// *************************************************************************** *
// *                                                                           *
// *                      Mentor Graphics Corporation                          *
// *                          All rights reserved                              *
// *                                                                           *
// *************************************************************************** *
// *                                                                           *
// * Description:         CANDB File                                           *
// * Generated at:        2021-09-06 14:00                                     *
// * System:              LPCsystem_MAIN                                       *
// * Network:             LPC1CAN                                              *
// *                                                                           *
// *************************************************************************** *
// *                                                                           *
// *             THIS CONFIGURATION MIGHT CONTAIN SOME ERRORS                  *
// *              IF THE INPUT MODEL WAS NOT PROPERLY FORMED!                  *
// *                    Do Not Use this File directly!                         *
// *                                                                           *
// *************************************************************************** *
VERSION "LPC1CAN"

NS_ :

BS_ :

BU_ :  LPC LPCdp LPCETC

BO_ 337 LpcdpLpcPASFr01 : 64 LPCdp
 SG_ AbsCtrlActv2 : 469|1@0+ (1,0) [0|1] "" LPC
 SG_ AbsCtrlActv2_UB : 468|1@0+ (1,0) [0|1] "" LPC
 SG_ AccSts2 : 415|3@0+ (1,0) [0|7] "" LPC
 SG_ AccSts2_UB : 412|1@0+ (1,0) [0|1] "" LPC
 SG_ AdPrimWhlAgEstimdGroupSafe_UB : 504|1@0+ (1,0) [0|1] "" LPC
 SG_ AdPrimWhlAgEstimdGroupSafeChks : 0|8@1+ (1.0,0.0) [0.0|255.0] "Unitless" LPC
 SG_ AdPrimWhlAgEstimdGroupSafeCntr : 8|4@1+ (1.0,0.0) [0.0|15.0] "Unitless" LPC
 SG_ AdPrimWhlAgEstimdGroupSafeQf1 : 48|2@1+ (1,0) [0|3] "" LPC
 SG_ AdPrimWhlAgEstimdGroupSafeWhlAg : 16|15@1+ (0.00005249,-0.85) [-0.85|0.8500461200000001] "rad" LPC
 SG_ AdPrimWhlAgEstimdGroupSafeWhlAgRate : 32|15@1+ (0.00005,-0.7) [-0.7|0.7000000000000002] "rad/s" LPC
 SG_ EpbSts2_UB : 254|1@0+ (1,0) [0|1] "" LPC
 SG_ EpbSts2EpbSts : 272|4@1+ (1,0) [0|15] "" LPC
 SG_ EpbSts2EpbStsChks : 256|8@1+ (1.0,0.0) [0.0|255.0] "Unitless" LPC
 SG_ EpbSts2EpbStsCntr : 264|4@1+ (1.0,0.0) [0.0|15.0] "Unitless" LPC
 SG_ FrntLeWhlSpdSnsrData_UB : 505|1@0+ (1,0) [0|1] "" LPC
 SG_ FrntLeWhlSpdSnsrDataChks : 56|8@1+ (1.0,0.0) [0.0|255.0] "Unitless" LPC
 SG_ FrntLeWhlSpdSnsrDataCntr : 64|4@1+ (1.0,0.0) [0.0|15.0] "Unitless" LPC
 SG_ FrntLeWhlSpdSnsrDataWhlAgSpdFrntLe : 72|15@1+ (0.0078125,0.0) [0.0|255.0] "Unitless" LPC
 SG_ FrntLeWhlSpdSnsrDataWhlAgSpdFrntLeQf : 96|2@1+ (1,0) [0|3] "" LPC
 SG_ FrntLeWhlSpdSnsrDataWhlRotDirFrntLe : 98|2@1+ (1,0) [0|3] "" LPC
 SG_ FrntLeWhlSpdSnsrDataWhlRotDirFrntLeQf : 100|2@1+ (1,0) [0|3] "" LPC
 SG_ FrntLeWhlSpdSnsrDataWhlRotToothCntrFrntLe : 88|8@1+ (1.0,0.0) [0.0|255.0] "Unitless" LPC
 SG_ FrntLeWhlSpdSnsrDataWhlRotToothCntrFrntLeQf : 102|2@1+ (1,0) [0|3] "" LPC
 SG_ FrntRiWhlSpdSnsrData_UB : 506|1@0+ (1,0) [0|1] "" LPC
 SG_ FrntRiWhlSpdSnsrDataChks : 104|8@1+ (1.0,0.0) [0.0|255.0] "Unitless" LPC
 SG_ FrntRiWhlSpdSnsrDataCntr : 112|4@1+ (1.0,0.0) [0.0|15.0] "Unitless" LPC
 SG_ FrntRiWhlSpdSnsrDataWhlAgSpdFrntRi : 120|15@1+ (0.0078125,0.0) [0.0|255.0] "Unitless" LPC
 SG_ FrntRiWhlSpdSnsrDataWhlAgSpdFrntRiQf : 144|2@1+ (1,0) [0|3] "" LPC
 SG_ FrntRiWhlSpdSnsrDataWhlRotDirFrntRi : 146|2@1+ (1,0) [0|3] "" LPC
 SG_ FrntRiWhlSpdSnsrDataWhlRotDirFrntRiQf : 148|2@1+ (1,0) [0|3] "" LPC
 SG_ FrntRiWhlSpdSnsrDataWhlRotToothCntrFrntRi : 136|8@1+ (1.0,0.0) [0.0|255.0] "Unitless" LPC
 SG_ FrntRiWhlSpdSnsrDataWhlRotToothCntrFrntRiQf : 150|2@1+ (1,0) [0|3] "" LPC
 SG_ IMURawData_UB : 255|1@0+ (1,0) [0|1] "" LPC
 SG_ IMURawDataIMULatAccRaw : 296|16@1+ (0.0015258789,-49.9999997952) [-49.9999997952|49.9984739163] "m/s^2" LPC
 SG_ IMURawDataIMULatAccRawQf : 392|2@1+ (1,0) [0|3] "" LPC
 SG_ IMURawDataIMULongAccRaw : 312|16@1+ (0.0015258789,-49.9999997952) [-49.9999997952|49.9984739163] "m/s^2" LPC
 SG_ IMURawDataIMULongAccRawQf : 394|2@1+ (1,0) [0|3] "" LPC
 SG_ IMURawDataIMUPitchRateRaw : 328|16@1+ (0.000159791,-5.236031488) [-5.236031488|5.235871697] "rad/s" LPC
 SG_ IMURawDataIMUPitchRateRawQf : 396|2@1+ (1,0) [0|3] "" LPC
 SG_ IMURawDataIMURollRateRaw : 344|16@1+ (0.000159791,-5.236031488) [-5.236031488|5.235871697] "rad/s" LPC
 SG_ IMURawDataIMURollRateRawQf : 398|2@1+ (1,0) [0|3] "" LPC
 SG_ IMURawDataIMUVertAccRaw : 360|16@1+ (0.0015258789,-49.9999997952) [-49.9999997952|49.9984739163] "m/s^2" LPC
 SG_ IMURawDataIMUVertAccRawQf : 400|2@1+ (1,0) [0|3] "" LPC
 SG_ IMURawDataIMUYawRateRaw : 376|16@1+ (0.000159791,-5.236031488) [-5.236031488|5.235871697] "rad/s" LPC
 SG_ IMURawDataIMUYawRateRawQf : 402|2@1+ (1,0) [0|3] "" LPC
 SG_ IMURawDataIndicationChks : 280|8@1+ (1.0,0.0) [0.0|255.0] "Unitless" LPC
 SG_ IMURawDataIndicationCntr : 288|4@1+ (1.0,0.0) [0.0|15.0] "Unitless" LPC
 SG_ NFSStMacSts_UB : 507|1@0+ (1,0) [0|1] "" LPC
 SG_ NFSStMacStsNFSActvSt : 248|3@1+ (1,0) [0|7] "" LPC
 SG_ NFSStMacStsNFSIntrfInfoTyp : 251|3@1+ (1,0) [0|7] "" LPC
 SG_ PAPAvl : 486|3@0+ (1,0) [0|7] "" LPC
 SG_ PAPAvl_UB : 487|1@0+ (1,0) [0|1] "" LPC
 SG_ PAPDrvrActvn : 496|1@0+ (1,0) [0|1] "" LPC
 SG_ PAPDrvrActvn_UB : 497|1@0+ (1,0) [0|1] "" LPC
 SG_ PAPManvStrtReq : 498|1@0+ (1,0) [0|1] "" LPC
 SG_ PAPManvStrtReq_UB : 499|1@0+ (1,0) [0|1] "" LPC
 SG_ PrkgAssiAvl : 411|3@0+ (1,0) [0|7] "" LPC
 SG_ PrkgAssiAvl_UB : 408|1@0+ (1,0) [0|1] "" LPC
 SG_ PrkgAssiDrvnActvn : 500|1@0+ (1,0) [0|1] "" LPC
 SG_ PrkgAssiDrvnActvn_UB : 501|1@0+ (1,0) [0|1] "" LPC
 SG_ ReLeWhlSpdSnsrData_UB : 502|1@0+ (1,0) [0|1] "" LPC
 SG_ ReLeWhlSpdSnsrDataChks : 152|8@1+ (1.0,0.0) [0.0|255.0] "Unitless" LPC
 SG_ ReLeWhlSpdSnsrDataCntr : 160|4@1+ (1.0,0.0) [0.0|15.0] "Unitless" LPC
 SG_ ReLeWhlSpdSnsrDataWhlAgSpdReLe : 168|15@1+ (0.0078125,0.0) [0.0|255.0] "Unitless" LPC
 SG_ ReLeWhlSpdSnsrDataWhlAgSpdReLeQf : 192|2@1+ (1,0) [0|3] "" LPC
 SG_ ReLeWhlSpdSnsrDataWhlRotDirReLe : 194|2@1+ (1,0) [0|3] "" LPC
 SG_ ReLeWhlSpdSnsrDataWhlRotDirReLeQf : 196|2@1+ (1,0) [0|3] "" LPC
 SG_ ReLeWhlSpdSnsrDataWhlRotToothCntrReLe : 184|8@1+ (1.0,0.0) [0.0|255.0] "Unitless" LPC
 SG_ ReLeWhlSpdSnsrDataWhlRotToothCntrReLeQf : 198|2@1+ (1,0) [0|3] "" LPC
 SG_ ReRiWhlSpdSnsrData_UB : 503|1@0+ (1,0) [0|1] "" LPC
 SG_ ReRiWhlSpdSnsrDataChks : 200|8@1+ (1.0,0.0) [0.0|255.0] "Unitless" LPC
 SG_ ReRiWhlSpdSnsrDataCntr : 208|4@1+ (1.0,0.0) [0.0|15.0] "Unitless" LPC
 SG_ ReRiWhlSpdSnsrDataWhlAgSpdReRi : 216|15@1+ (0.0078125,0.0) [0.0|255.0] "Unitless" LPC
 SG_ ReRiWhlSpdSnsrDataWhlAgSpdReRiQf : 240|2@1+ (1,0) [0|3] "" LPC
 SG_ ReRiWhlSpdSnsrDataWhlRotDirReRi : 242|2@1+ (1,0) [0|3] "" LPC
 SG_ ReRiWhlSpdSnsrDataWhlRotDirReRiQf : 244|2@1+ (1,0) [0|3] "" LPC
 SG_ ReRiWhlSpdSnsrDataWhlRotToothCntrReRi : 232|8@1+ (1.0,0.0) [0.0|255.0] "Unitless" LPC
 SG_ ReRiWhlSpdSnsrDataWhlRotToothCntrReRiQf : 246|2@1+ (1,0) [0|3] "" LPC
 SG_ SteerWhlTq2 : 483|12@0- (0.01,0.0) [-20.0|20.0] "NewtonMeter" LPC
 SG_ SteerWhlTq2_UB : 467|1@0+ (1,0) [0|1] "" LPC
 SG_ TireRdEstimd : 465|10@0+ (0.00048828,0.25) [0.25|0.50048764] "m" LPC
 SG_ TireRdEstimd_UB : 466|1@0+ (1,0) [0|1] "" LPC
 SG_ TrsmParkLockdSafe2_UB : 471|1@0+ (1,0) [0|1] "" LPC
 SG_ TrsmParkLockdSafe2TrsmParkLockd : 432|2@1+ (1,0) [0|3] "" LPC
 SG_ TrsmParkLockdSafe2TrsmParkLockdChks : 416|8@1+ (1.0,0.0) [0.0|255.0] "Unitless" LPC
 SG_ TrsmParkLockdSafe2TrsmParkLockdCntr : 424|4@1+ (1.0,0.0) [0.0|15.0] "Unitless" LPC
 SG_ VehMtnStSafe3_UB : 470|1@0+ (1,0) [0|1] "" LPC
 SG_ VehMtnStSafe3VehMtnSt : 456|3@1+ (1,0) [0|7] "" LPC
 SG_ VehMtnStSafe3VehMtnStChks : 440|8@1+ (1.0,0.0) [0.0|255.0] "Unitless" LPC
 SG_ VehMtnStSafe3VehMtnStCntr : 448|4@1+ (1.0,0.0) [0.0|15.0] "Unitless" LPC

BO_ 339 LpcdpSharedFr03 : 16 LPCdp
 SG_ CarTiGlb : 7|32@0+ (0.1,0.0) [0.0|429496729.5] "s" LPC
 SG_ CarTiGlb_UB : 39|1@0+ (1,0) [0|1] "" LPC
 SG_ DstTrvld : 36|21@0+ (1.0,0.0) [0.0|2000000.0] "km" LPC
 SG_ DstTrvld_UB : 38|1@0+ (1,0) [0|1] "" LPC
 SG_ OutdT_UB : 61|1@0+ (1,0) [0|1] "" LPC
 SG_ OutdTAmbTVal : 58|11@0+ (0.1,-70.0) [-70.0|134.70000000000002] "degC" LPC
 SG_ OutdTQly : 60|2@0+ (1,0) [0|3] "" LPC
 SG_ VehBattU_UB : 85|1@0+ (1,0) [0|1] "" LPC
 SG_ VehBattUSysU : 79|8@0+ (0.1,0.0) [0.0|25.0] "Volt" LPC
 SG_ VehBattUSysUQf : 87|2@0+ (1,0) [0|3] "" LPC
 SG_ VehSpdNom : 84|13@0+ (0.01,0.0) [0.0|81.91] "m/s" LPC
 SG_ VehSpdNom_UB : 103|1@0+ (1,0) [0|1] "" LPC
 SG_ VehSpdNomQf : 63|2@0+ (1,0) [0|3] "" LPC
 SG_ VehSpdNomQf_UB : 37|1@0+ (1,0) [0|1] "" LPC

BO_ 1409 LpcEtcToLpcLpc1canXcpFr01 : 64 LPCETC

BO_ 1410 LpcEtcToLpcLpc1canXcpFr02 : 64 LPCETC

BO_ 257 LpcLpc1CanFr01_100ms : 64 LPC
 SG_ AlrmPasRst : 86|1@0+ (1,0) [0|1] "" LPCdp
 SG_ AlrmPasRst_UB : 87|1@0+ (1,0) [0|1] "" LPCdp
 SG_ AlrmRednSts : 205|2@0+ (1,0) [0|3] "" LPCdp
 SG_ AlrmRednSts_UB : 181|1@0+ (1,0) [0|1] "" LPCdp
 SG_ AlrmSnsrSts_UB : 191|1@0+ (1,0) [0|1] "" LPCdp
 SG_ AlrmSnsrStsInclination : 199|2@0+ (1,0) [0|3] "" LPCdp
 SG_ AlrmSnsrStsInteriorMotion : 197|2@0+ (1,0) [0|3] "" LPCdp
 SG_ AlrmSnsrStsPerimeter : 195|2@0+ (1,0) [0|3] "" LPCdp
 SG_ AlrmSnsrStsSirenConnected : 193|2@0+ (1,0) [0|3] "" LPCdp
 SG_ AlrmSts : 119|2@0+ (1,0) [0|3] "" LPCdp
 SG_ AlrmSts_UB : 127|1@0+ (1,0) [0|1] "" LPCdp
 SG_ AlrmTrgSrc : 167|4@0+ (1,0) [0|15] "" LPCdp
 SG_ AlrmTrgSrc_UB : 103|1@0+ (1,0) [0|1] "" LPCdp
 SG_ AmbIllmnFwdSts2_UB : 301|1@0+ (1,0) [0|1] "" LPCdp
 SG_ AmbIllmnFwdSts2AmbLiIllmn : 320|16@1+ (1.0,0.0) [0.0|65534.0] "Unitless" LPCdp
 SG_ AmbIllmnFwdSts2Chks : 304|8@1+ (1.0,0.0) [0.0|255.0] "Unitless" LPCdp
 SG_ AmbIllmnFwdSts2Cntr : 312|4@1+ (1.0,0.0) [0.0|15.0] "Unitless" LPCdp
 SG_ CenLockSts_UB : 23|1@0+ (1,0) [0|1] "" LPCdp
 SG_ CenLockStsLockSrc : 19|4@0+ (1,0) [0|15] "" LPCdp
 SG_ CenLockStsLockSts : 21|2@0+ (1,0) [0|3] "" LPCdp
 SG_ CenLockStsUpdEve : 22|1@0+ (1,0) [0|1] "" LPCdp
 SG_ ChdLockSts_UB : 190|1@0+ (1,0) [0|1] "" LPCdp
 SG_ ChdLockStsDoorDrvrRe : 189|2@0+ (1,0) [0|3] "" LPCdp
 SG_ ChdLockStsDoorPass : 187|2@0+ (1,0) [0|3] "" LPCdp
 SG_ ChdLockStsDoorPassRe : 185|2@0+ (1,0) [0|3] "" LPCdp
 SG_ ChdWinProtnStsAtDrvrRe : 0|1@0+ (1,0) [0|1] "" LPCdp
 SG_ ChdWinProtnStsAtDrvrRe_UB : 1|1@0+ (1,0) [0|1] "" LPCdp
 SG_ ChdWinProtnStsAtPass : 2|1@0+ (1,0) [0|1] "" LPCdp
 SG_ ChdWinProtnStsAtPass_UB : 3|1@0+ (1,0) [0|1] "" LPCdp
 SG_ ChdWinProtnStsAtPassRe : 4|1@0+ (1,0) [0|1] "" LPCdp
 SG_ ChdWinProtnStsAtPassRe_UB : 5|1@0+ (1,0) [0|1] "" LPCdp
 SG_ DiagcForLCSP : 203|3@0+ (1,0) [0|7] "" LPCdp
 SG_ DiagcForLCSP_UB : 200|1@0+ (1,0) [0|1] "" LPCdp
 SG_ DoorDrvrSts : 27|2@0+ (1,0) [0|3] "" LPCdp
 SG_ DoorDrvrSts_UB : 28|1@0+ (1,0) [0|1] "" LPCdp
 SG_ DoorDrvrStsRe : 30|2@0+ (1,0) [0|3] "" LPCdp
 SG_ DoorDrvrStsRe_UB : 31|1@0+ (1,0) [0|1] "" LPCdp
 SG_ DoorPassSts : 33|2@0+ (1,0) [0|3] "" LPCdp
 SG_ DoorPassSts_UB : 34|1@0+ (1,0) [0|1] "" LPCdp
 SG_ DoorPassStsRe : 36|2@0+ (1,0) [0|3] "" LPCdp
 SG_ DoorPassStsRe_UB : 37|1@0+ (1,0) [0|1] "" LPCdp
 SG_ DrvrGearShiftDirReqAux_UB : 216|1@0+ (1,0) [0|1] "" LPCdp
 SG_ DrvrGearShiftDirReqAuxChks : 224|8@1+ (1.0,0.0) [0.0|255.0] "Unitless" LPCdp
 SG_ DrvrGearShiftDirReqAuxCntr : 232|4@1+ (1.0,0.0) [0.0|15.0] "Unitless" LPCdp
 SG_ DrvrGearShiftDirReqAuxDrvrGearShiftDirReqAukSts : 245|2@1+ (1,0) [0|3] "" LPCdp
 SG_ DrvrGearShiftDirReqAuxPosn : 240|5@1+ (1,0) [0|31] "" LPCdp
 SG_ ExLiHcFltHdlampBeamHiLe : 273|1@0+ (1,0) [0|1] "" LPCdp
 SG_ ExLiHcFltHdlampBeamHiLe_UB : 274|1@0+ (1,0) [0|1] "" LPCdp
 SG_ ExLiHcFltHdlampBeamHiRi : 275|1@0+ (1,0) [0|1] "" LPCdp
 SG_ ExLiHcFltHdlampBeamHiRi_UB : 276|1@0+ (1,0) [0|1] "" LPCdp
 SG_ ExLiHcFltHdlampBeamLoLe : 277|1@0+ (1,0) [0|1] "" LPCdp
 SG_ ExLiHcFltHdlampBeamLoLe_UB : 278|1@0+ (1,0) [0|1] "" LPCdp
 SG_ ExLiHcFltHdlampBeamLoRi : 279|1@0+ (1,0) [0|1] "" LPCdp
 SG_ ExLiHcFltHdlampBeamLoRi_UB : 280|1@0+ (1,0) [0|1] "" LPCdp
 SG_ ExLiHcFltHdlampDaytiRunngLe : 281|1@0+ (1,0) [0|1] "" LPCdp
 SG_ ExLiHcFltHdlampDaytiRunngLe_UB : 282|1@0+ (1,0) [0|1] "" LPCdp
 SG_ ExLiHcFltHdlampDaytiRunngRi : 283|1@0+ (1,0) [0|1] "" LPCdp
 SG_ ExLiHcFltHdlampDaytiRunngRi_UB : 284|1@0+ (1,0) [0|1] "" LPCdp
 SG_ ExLiHcFltHdlampPosLe : 285|1@0+ (1,0) [0|1] "" LPCdp
 SG_ ExLiHcFltHdlampPosLe_UB : 286|1@0+ (1,0) [0|1] "" LPCdp
 SG_ ExLiHcFltHdlampPosRi : 287|1@0+ (1,0) [0|1] "" LPCdp
 SG_ ExLiHcFltHdlampPosRi_UB : 288|1@0+ (1,0) [0|1] "" LPCdp
 SG_ ExLiHcFltHdlampSmlLe : 289|1@0+ (1,0) [0|1] "" LPCdp
 SG_ ExLiHcFltHdlampSmlLe_UB : 290|1@0+ (1,0) [0|1] "" LPCdp
 SG_ ExLiHcFltHdlampSmlRi : 291|1@0+ (1,0) [0|1] "" LPCdp
 SG_ ExLiHcFltHdlampSmlRi_UB : 292|1@0+ (1,0) [0|1] "" LPCdp
 SG_ ExLiHdFltBeamHiLe : 293|1@0+ (1,0) [0|1] "" LPCdp
 SG_ ExLiHdFltBeamHiLe_UB : 294|1@0+ (1,0) [0|1] "" LPCdp
 SG_ ExLiHdFltBeamHiRi : 295|1@0+ (1,0) [0|1] "" LPCdp
 SG_ ExLiHdFltBeamHiRi_UB : 296|1@0+ (1,0) [0|1] "" LPCdp
 SG_ ExLiHdFltBeamLoLe : 297|1@0+ (1,0) [0|1] "" LPCdp
 SG_ ExLiHdFltBeamLoLe_UB : 298|1@0+ (1,0) [0|1] "" LPCdp
 SG_ ExLiHdFltBeamLoRi : 299|1@0+ (1,0) [0|1] "" LPCdp
 SG_ ExLiHdFltBeamLoRi_UB : 300|1@0+ (1,0) [0|1] "" LPCdp
 SG_ FltBrkLiIndcn : 81|2@0+ (1,0) [0|3] "" LPCdp
 SG_ FltBrkLiIndcn_UB : 95|1@0+ (1,0) [0|1] "" LPCdp
 SG_ FwdLookCamHeatingSts : 6|1@0+ (1,0) [0|1] "" LPCdp
 SG_ FwdLookCamHeatingSts_UB : 7|1@0+ (1,0) [0|1] "" LPCdp
 SG_ GlvBoxSts : 9|2@0+ (1,0) [0|3] "" LPCdp
 SG_ GlvBoxSts_UB : 10|1@0+ (1,0) [0|1] "" LPCdp
 SG_ HoodSts : 12|2@0+ (1,0) [0|3] "" LPCdp
 SG_ HoodSts_UB : 13|1@0+ (1,0) [0|1] "" LPCdp
 SG_ LcmaLedStsDrvrSide : 15|1@0+ (1,0) [0|1] "" LPCdp
 SG_ LcmaLedStsDrvrSide_UB : 14|1@0+ (1,0) [0|1] "" LPCdp
 SG_ LcmaLedStsPassSide : 24|1@0+ (1,0) [0|1] "" LPCdp
 SG_ LcmaLedStsPassSide_UB : 25|1@0+ (1,0) [0|1] "" LPCdp
 SG_ LiOperMod : 207|2@0+ (1,0) [0|3] "" LPCdp
 SG_ LiOperMod_UB : 182|1@0+ (1,0) [0|1] "" LPCdp
 SG_ LockgCenStsForUsrFb : 42|3@0+ (1,0) [0|7] "" LPCdp
 SG_ LockgCenStsForUsrFb_UB : 43|1@0+ (1,0) [0|1] "" LPCdp
 SG_ LockgPrvtSts : 82|1@0+ (1,0) [0|1] "" LPCdp
 SG_ LockgPrvtSts_UB : 83|1@0+ (1,0) [0|1] "" LPCdp
 SG_ MirrFoldStsAtDrvr : 91|3@0+ (1,0) [0|7] "" LPCdp
 SG_ MirrFoldStsAtDrvr_UB : 88|1@0+ (1,0) [0|1] "" LPCdp
 SG_ MirrFoldStsAtPass : 47|3@0+ (1,0) [0|7] "" LPCdp
 SG_ MirrFoldStsAtPass_UB : 84|1@0+ (1,0) [0|1] "" LPCdp
 SG_ MirrorDefrosterStatus : 93|2@0+ (1,0) [0|3] "" LPCdp
 SG_ MirrorDefrosterStatus_UB : 94|1@0+ (1,0) [0|1] "" LPCdp
 SG_ MirrPosnSensFdbValDrvr_UB : 126|1@0+ (1,0) [0|1] "" LPCdp
 SG_ MirrPosnSensFdbValDrvrMirrSensXPos : 135|16@0+ (1.0,0.0) [0.0|65535.0] "Unitless" LPCdp
 SG_ MirrPosnSensFdbValDrvrMirrSensYPos : 151|16@0+ (1.0,0.0) [0.0|65535.0] "Unitless" LPCdp
 SG_ MirrPosnSensFdbValPass_UB : 85|1@0+ (1,0) [0|1] "" LPCdp
 SG_ MirrPosnSensFdbValPassMirrSensXPos : 55|16@0+ (1.0,0.0) [0.0|65535.0] "Unitless" LPCdp
 SG_ MirrPosnSensFdbValPassMirrSensYPos : 71|16@0+ (1.0,0.0) [0.0|65535.0] "Unitless" LPCdp
 SG_ PassAirbLmpSts : 179|3@0+ (1,0) [0|7] "" LPCdp
 SG_ PassAirbLmpSts_UB : 176|1@0+ (1,0) [0|1] "" LPCdp
 SG_ SeatRowSecBackRestSwtSts_UB : 210|1@0+ (1,0) [0|1] "" LPCdp
 SG_ SeatRowSecBackRestSwtStsSwtLeSts : 209|1@0+ (1,0) [0|1] "" LPCdp
 SG_ SeatRowSecBackRestSwtStsSwtRiSts : 208|1@0+ (1,0) [0|1] "" LPCdp
 SG_ SeatSwtTrSts_UB : 217|1@0+ (1,0) [0|1] "" LPCdp
 SG_ SeatSwtTrStsLeHalfSts : 221|2@0+ (1,0) [0|3] "" LPCdp
 SG_ SeatSwtTrStsRiHalfSts : 219|2@0+ (1,0) [0|3] "" LPCdp
 SG_ SftyBltTelltlFlt : 111|1@0+ (1,0) [0|1] "" LPCdp
 SG_ SftyBltTelltlFlt_UB : 110|1@0+ (1,0) [0|1] "" LPCdp
 SG_ TrlrLampChk : 215|1@0+ (1,0) [0|1] "" LPCdp
 SG_ TrlrLampChk_UB : 180|1@0+ (1,0) [0|1] "" LPCdp
 SG_ TrlrLampChkSts : 214|3@0+ (1,0) [0|7] "" LPCdp
 SG_ TrlrLampChkSts_UB : 211|1@0+ (1,0) [0|1] "" LPCdp
 SG_ TrlrLiSts : 170|3@0+ (1,0) [0|7] "" LPCdp
 SG_ TrlrLiSts_UB : 183|1@0+ (1,0) [0|1] "" LPCdp
 SG_ TrlrSrvReqToHMI : 172|1@0+ (1,0) [0|1] "" LPCdp
 SG_ TrlrSrvReqToHMI_UB : 171|1@0+ (1,0) [0|1] "" LPCdp
 SG_ TrSts : 39|2@0+ (1,0) [0|3] "" LPCdp
 SG_ TrSts_UB : 44|1@0+ (1,0) [0|1] "" LPCdp
 SG_ TurnIndcrFault_UB : 272|1@0+ (1,0) [0|1] "" LPCdp
 SG_ TurnIndcrFaultChks : 248|8@1+ (1.0,0.0) [0.0|255.0] "Unitless" LPCdp
 SG_ TurnIndcrFaultCntr : 256|4@1+ (1.0,0.0) [0.0|15.0] "Unitless" LPCdp
 SG_ TurnIndcrFaultRearLe : 264|2@1+ (1,0) [0|3] "" LPCdp
 SG_ TurnIndcrFaultRearRi : 266|2@1+ (1,0) [0|3] "" LPCdp
 SG_ TurnIndcrFaultSideLe : 268|2@1+ (1,0) [0|3] "" LPCdp
 SG_ TurnIndcrFaultSideRi : 270|2@1+ (1,0) [0|3] "" LPCdp
 SG_ TwbrSts_UB : 163|1@0+ (1,0) [0|1] "" LPCdp
 SG_ TwbrStsTwbrSts : 162|3@0+ (1,0) [0|7] "" LPCdp
 SG_ TwbrStsTwbrTyp : 175|3@0+ (1,0) [0|7] "" LPCdp
 SG_ WinPosnStsAtDrv : 100|5@0+ (1,0) [0|31] "" LPCdp
 SG_ WinPosnStsAtDrv_UB : 101|1@0+ (1,0) [0|1] "" LPCdp
 SG_ WinPosnStsAtDrvrRe : 108|5@0+ (1,0) [0|31] "" LPCdp
 SG_ WinPosnStsAtDrvrRe_UB : 109|1@0+ (1,0) [0|1] "" LPCdp
 SG_ WinPosnStsAtPass : 116|5@0+ (1,0) [0|31] "" LPCdp
 SG_ WinPosnStsAtPass_UB : 117|1@0+ (1,0) [0|1] "" LPCdp
 SG_ WinPosnStsAtPassRe : 124|5@0+ (1,0) [0|31] "" LPCdp
 SG_ WinPosnStsAtPassRe_UB : 125|1@0+ (1,0) [0|1] "" LPCdp

BO_ 256 LpcLpc1CanFr01_10ms : 64 LPC
 SG_ ActvnOfDispIllmnCSD : 305|1@0+ (1,0) [0|1] "" LPCdp
 SG_ ActvnOfDispIllmnCSD_UB : 304|1@0+ (1,0) [0|1] "" LPCdp
 SG_ ActvnOfDispIllmnDIM : 258|1@0+ (1,0) [0|1] "" LPCdp
 SG_ ActvnOfDispIllmnDIM_UB : 257|1@0+ (1,0) [0|1] "" LPCdp
 SG_ ActvnOfSwtIllmnMSM : 256|1@0+ (1,0) [0|1] "" LPCdp
 SG_ ActvnOfSwtIllmnMSM_UB : 271|1@0+ (1,0) [0|1] "" LPCdp
 SG_ ActvnOfSwtIllmnRCSM : 270|1@0+ (1,0) [0|1] "" LPCdp
 SG_ ActvnOfSwtIllmnRCSM_UB : 269|1@0+ (1,0) [0|1] "" LPCdp
 SG_ ActvnOfSwtIllmnSWM : 268|1@0+ (1,0) [0|1] "" LPCdp
 SG_ ActvnOfSwtIllmnSWM_UB : 267|1@0+ (1,0) [0|1] "" LPCdp
 SG_ ActvnOfSwtIllmnSWS : 266|1@0+ (1,0) [0|1] "" LPCdp
 SG_ ActvnOfSwtIllmnSWS_UB : 265|1@0+ (1,0) [0|1] "" LPCdp
 SG_ ADPMWakeUp : 352|1@0+ (1,0) [0|1] "" LPCdp
 SG_ ADPMWakeUp_UB : 353|1@0+ (1,0) [0|1] "" LPCdp
 SG_ ApduCmdLpcToIntrEth_UB : 431|1@0+ (1,0) [0|1] "" LPCdp
 SG_ ApduCmdLpcToIntrEthByte0 : 367|8@0+ (1.0,0.0) [0.0|255.0] "Unitless" LPCdp
 SG_ ApduCmdLpcToIntrEthByte1 : 375|8@0+ (1.0,0.0) [0.0|255.0] "Unitless" LPCdp
 SG_ ApduCmdLpcToIntrEthByte2 : 383|8@0+ (1.0,0.0) [0.0|255.0] "Unitless" LPCdp
 SG_ ApduCmdLpcToIntrEthByte3 : 391|8@0+ (1.0,0.0) [0.0|255.0] "Unitless" LPCdp
 SG_ ApduCmdLpcToIntrEthByte4 : 399|8@0+ (1.0,0.0) [0.0|255.0] "Unitless" LPCdp
 SG_ ApduCmdLpcToIntrEthByte5 : 407|8@0+ (1.0,0.0) [0.0|255.0] "Unitless" LPCdp
 SG_ ApduCmdLpcToIntrEthByte6 : 415|8@0+ (1.0,0.0) [0.0|255.0] "Unitless" LPCdp
 SG_ ApduCmdLpcToIntrEthByte7 : 423|8@0+ (1.0,0.0) [0.0|255.0] "Unitless" LPCdp
 SG_ AUDWakeUp : 358|1@0+ (1,0) [0|1] "" LPCdp
 SG_ AUDWakeUp_UB : 359|1@0+ (1,0) [0|1] "" LPCdp
 SG_ AutoIllumReq1RCSM_UB : 424|1@0+ (1,0) [0|1] "" LPCdp
 SG_ AutoIllumReq1RCSMDelayTime : 439|8@0+ (1.0,0.0) [0.0|255.0] "Unitless" LPCdp
 SG_ AutoIllumReq1RCSMPWM1 : 447|8@0+ (1.0,0.0) [0.0|255.0] "Unitless" LPCdp
 SG_ AutoIllumReq1RCSMPWM2 : 455|8@0+ (1.0,0.0) [0.0|255.0] "Unitless" LPCdp
 SG_ AutoIllumReq1RCSMPWM3 : 463|8@0+ (1.0,0.0) [0.0|255.0] "Unitless" LPCdp
 SG_ AutoIllumReq1RCSMReserve1 : 471|4@0+ (1.0,0.0) [0.0|15.0] "Unitless" LPCdp
 SG_ AutoIllumReq1RCSMReserve2 : 467|4@0+ (1.0,0.0) [0.0|15.0] "Unitless" LPCdp
 SG_ AutoIllumReq1RCSMTranBehavior : 479|2@0+ (1.0,0.0) [0.0|3.0] "Unitless" LPCdp
 SG_ AutoIllumReq1RCSMTranStep : 477|6@0+ (1.0,0.0) [0.0|63.0] "Unitless" LPCdp
 SG_ AutoIllumReqCSD_UB : 279|1@0+ (1,0) [0|1] "" LPCdp
 SG_ AutoIllumReqCSDDelayTime : 151|8@0+ (1.0,0.0) [0.0|255.0] "Unitless" LPCdp
 SG_ AutoIllumReqCSDPWM : 159|8@0+ (1.0,0.0) [0.0|255.0] "Unitless" LPCdp
 SG_ AutoIllumReqCSDReserve1 : 167|4@0+ (1.0,0.0) [0.0|15.0] "Unitless" LPCdp
 SG_ AutoIllumReqCSDReserve2 : 163|4@0+ (1.0,0.0) [0.0|15.0] "Unitless" LPCdp
 SG_ AutoIllumReqCSDTranBehavior : 175|2@0+ (1.0,0.0) [0.0|3.0] "Unitless" LPCdp
 SG_ AutoIllumReqCSDTranStep : 173|6@0+ (1.0,0.0) [0.0|63.0] "Unitless" LPCdp
 SG_ AutoIllumReqDIM_UB : 306|1@0+ (1,0) [0|1] "" LPCdp
 SG_ AutoIllumReqDIMDelayTime : 487|8@0+ (1.0,0.0) [0.0|255.0] "Unitless" LPCdp
 SG_ AutoIllumReqDIMPWM : 495|8@0+ (1.0,0.0) [0.0|255.0] "Unitless" LPCdp
 SG_ AutoIllumReqDIMReserve1 : 503|4@0+ (1.0,0.0) [0.0|15.0] "Unitless" LPCdp
 SG_ AutoIllumReqDIMReserve2 : 499|4@0+ (1.0,0.0) [0.0|15.0] "Unitless" LPCdp
 SG_ AutoIllumReqDIMTranBehavior : 511|2@0+ (1.0,0.0) [0.0|3.0] "Unitless" LPCdp
 SG_ AutoIllumReqDIMTranStep : 509|6@0+ (1.0,0.0) [0.0|63.0] "Unitless" LPCdp
 SG_ AutoIllumReqMSM_UB : 264|1@0+ (1,0) [0|1] "" LPCdp
 SG_ AutoIllumReqMSMDelayTime : 119|8@0+ (1.0,0.0) [0.0|255.0] "Unitless" LPCdp
 SG_ AutoIllumReqMSMPWM : 127|8@0+ (1.0,0.0) [0.0|255.0] "Unitless" LPCdp
 SG_ AutoIllumReqMSMReserve1 : 135|4@0+ (1.0,0.0) [0.0|15.0] "Unitless" LPCdp
 SG_ AutoIllumReqMSMReserve2 : 131|4@0+ (1.0,0.0) [0.0|15.0] "Unitless" LPCdp
 SG_ AutoIllumReqMSMTranBehavior : 143|2@0+ (1.0,0.0) [0.0|3.0] "Unitless" LPCdp
 SG_ AutoIllumReqMSMTranStep : 141|6@0+ (1.0,0.0) [0.0|63.0] "Unitless" LPCdp
 SG_ AutoIllumReqSWM_UB : 278|1@0+ (1,0) [0|1] "" LPCdp
 SG_ AutoIllumReqSWMDelayTime : 183|8@0+ (1.0,0.0) [0.0|255.0] "Unitless" LPCdp
 SG_ AutoIllumReqSWMPWM : 191|8@0+ (1.0,0.0) [0.0|255.0] "Unitless" LPCdp
 SG_ AutoIllumReqSWMReserve1 : 199|4@0+ (1.0,0.0) [0.0|15.0] "Unitless" LPCdp
 SG_ AutoIllumReqSWMReserve2 : 195|4@0+ (1.0,0.0) [0.0|15.0] "Unitless" LPCdp
 SG_ AutoIllumReqSWMTranBehavior : 207|2@0+ (1.0,0.0) [0.0|3.0] "Unitless" LPCdp
 SG_ AutoIllumReqSWMTranStep : 205|6@0+ (1.0,0.0) [0.0|63.0] "Unitless" LPCdp
 SG_ AutoIllumReqSWS_UB : 277|1@0+ (1,0) [0|1] "" LPCdp
 SG_ AutoIllumReqSWSDelayTime : 215|8@0+ (1.0,0.0) [0.0|255.0] "Unitless" LPCdp
 SG_ AutoIllumReqSWSPWM : 223|8@0+ (1.0,0.0) [0.0|255.0] "Unitless" LPCdp
 SG_ AutoIllumReqSWSReserve1 : 231|4@0+ (1.0,0.0) [0.0|15.0] "Unitless" LPCdp
 SG_ AutoIllumReqSWSReserve2 : 227|4@0+ (1.0,0.0) [0.0|15.0] "Unitless" LPCdp
 SG_ AutoIllumReqSWSTranBehavior : 239|2@0+ (1.0,0.0) [0.0|3.0] "Unitless" LPCdp
 SG_ AutoIllumReqSWSTranStep : 237|6@0+ (1.0,0.0) [0.0|63.0] "Unitless" LPCdp
 SG_ ClimateActuatorsRelay : 425|1@0+ (1,0) [0|1] "" LPCdp
 SG_ ClimateActuatorsRelay_UB : 426|1@0+ (1,0) [0|1] "" LPCdp
 SG_ DIMWakeUp : 356|1@0+ (1,0) [0|1] "" LPCdp
 SG_ DIMWakeUp_UB : 357|1@0+ (1,0) [0|1] "" LPCdp
 SG_ DrvrDetnOfMovmtInCbnRecIf_UB : 280|1@0+ (1,0) [0|1] "" LPCdp
 SG_ DrvrDetnOfMovmtInCbnRecIfDetnSts : 284|2@0+ (1,0) [0|3] "" LPCdp
 SG_ DrvrDetnOfMovmtInCbnRecIfIntrDetnAvlSts : 287|3@0+ (1,0) [0|7] "" LPCdp
 SG_ DrvrDetnOfMovmtInCbnRecIfIntrDetnOf : 282|2@0+ (1,0) [0|3] "" LPCdp
 SG_ DrvrDetnOfPresInSeatRecIf_UB : 288|1@0+ (1,0) [0|1] "" LPCdp
 SG_ DrvrDetnOfPresInSeatRecIfDetnSts : 292|2@0+ (1,0) [0|3] "" LPCdp
 SG_ DrvrDetnOfPresInSeatRecIfIntrDetnAvlSts : 295|3@0+ (1,0) [0|7] "" LPCdp
 SG_ DrvrDetnOfPresInSeatRecIfIntrDetnOf : 290|2@0+ (1,0) [0|3] "" LPCdp
 SG_ DrvrDetnOfPresRecIf_UB : 336|1@0+ (1,0) [0|1] "" LPCdp
 SG_ DrvrDetnOfPresRecIfDetnSts : 340|2@0+ (1,0) [0|3] "" LPCdp
 SG_ DrvrDetnOfPresRecIfIntrDetnAvlSts : 343|3@0+ (1,0) [0|7] "" LPCdp
 SG_ DrvrDetnOfPresRecIfIntrDetnOf : 338|2@0+ (1,0) [0|3] "" LPCdp
 SG_ ExteriorLightRelay : 427|1@0+ (1,0) [0|1] "" LPCdp
 SG_ ExteriorLightRelay_UB : 428|1@0+ (1,0) [0|1] "" LPCdp
 SG_ IgnitionPowerRelay : 308|1@0+ (1,0) [0|1] "" LPCdp
 SG_ IgnitionPowerRelay_UB : 307|1@0+ (1,0) [0|1] "" LPCdp
 SG_ NfcCardAuthPrnst_UB : 323|1@0+ (1,0) [0|1] "" LPCdp
 SG_ NfcCardAuthPrnstPakNfcDeviceIDInt : 319|8@0+ (1.0,0.0) [0.0|255.0] "Unitless" LPCdp
 SG_ NfcCardAuthPrnstSubZoneLocation : 327|4@0+ (1,0) [0|15] "" LPCdp
 SG_ PassDetnOfMovmtInCbnRecIf_UB : 255|1@0+ (1,0) [0|1] "" LPCdp
 SG_ PassDetnOfMovmtInCbnRecIfDetnSts : 249|2@0+ (1,0) [0|3] "" LPCdp
 SG_ PassDetnOfMovmtInCbnRecIfIntrDetnAvlSts : 252|3@0+ (1,0) [0|7] "" LPCdp
 SG_ PassDetnOfMovmtInCbnRecIfIntrDetnOf : 254|2@0+ (1,0) [0|3] "" LPCdp
 SG_ PassDetnOfPresInSeatRecIf_UB : 328|1@0+ (1,0) [0|1] "" LPCdp
 SG_ PassDetnOfPresInSeatRecIfDetnSts : 335|2@0+ (1,0) [0|3] "" LPCdp
 SG_ PassDetnOfPresInSeatRecIfIntrDetnAvlSts : 333|3@0+ (1,0) [0|7] "" LPCdp
 SG_ PassDetnOfPresInSeatRecIfIntrDetnOf : 330|2@0+ (1,0) [0|3] "" LPCdp
 SG_ PassDetnOfPresRecIf_UB : 247|1@0+ (1,0) [0|1] "" LPCdp
 SG_ PassDetnOfPresRecIfDetnSts : 241|2@0+ (1,0) [0|3] "" LPCdp
 SG_ PassDetnOfPresRecIfIntrDetnAvlSts : 244|3@0+ (1,0) [0|7] "" LPCdp
 SG_ PassDetnOfPresRecIfIntrDetnOf : 246|2@0+ (1,0) [0|3] "" LPCdp
 SG_ SUMWakeUp : 354|1@0+ (1,0) [0|1] "" LPCdp
 SG_ SUMWakeUp_UB : 355|1@0+ (1,0) [0|1] "" LPCdp
 SG_ TrlrPrsnt1 : 310|1@0+ (1,0) [0|1] "" LPCdp
 SG_ TrlrPrsnt1_UB : 309|1@0+ (1,0) [0|1] "" LPCdp
 SG_ UsageAuthDrvrAuthMgrAuthLvl : 71|8@0+ (1.0,0.0) [0.0|255.0] "Unitless" LPCdp
 SG_ UsageAuthDrvrAuthMgrAuthLvl_UB : 276|1@0+ (1,0) [0|1] "" LPCdp
 SG_ UsageAuthDrvrAuthMgrMAC1 : 7|32@0+ (1.0,0.0) [0.0|4294967295.0] "Unitless" LPCdp
 SG_ UsageAuthDrvrAuthMgrMAC1_UB : 275|1@0+ (1,0) [0|1] "" LPCdp
 SG_ UsageAuthDrvrAuthMgrMAC2 : 39|32@0+ (1.0,0.0) [0.0|4294967295.0] "Unitless" LPCdp
 SG_ UsageAuthDrvrAuthMgrMAC2_UB : 274|1@0+ (1,0) [0|1] "" LPCdp
 SG_ UsageAuthDrvrAuthMgrStrtTi : 79|8@0+ (1.0,0.0) [0.0|255.0] "Unitless" LPCdp
 SG_ UsageAuthDrvrAuthMgrStrtTi_UB : 273|1@0+ (1,0) [0|1] "" LPCdp
 SG_ UsageAuthDrvrAuthMgrUniqID : 87|32@0+ (1.0,0.0) [0.0|4294967295.0] "Unitless" LPCdp
 SG_ UsageAuthDrvrAuthMgrUniqID_UB : 272|1@0+ (1,0) [0|1] "" LPCdp
 SG_ UsageModeAvailable : 298|1@0+ (1,0) [0|1] "" LPCdp
 SG_ UsageModeAvailable_UB : 297|1@0+ (1,0) [0|1] "" LPCdp
 SG_ UsageModeAwake : 296|1@0+ (1,0) [0|1] "" LPCdp
 SG_ UsageModeAwake_UB : 311|1@0+ (1,0) [0|1] "" LPCdp
 SG_ UsageModeResponsive : 429|1@0+ (1,0) [0|1] "" LPCdp
 SG_ UsageModeResponsive_UB : 430|1@0+ (1,0) [0|1] "" LPCdp

BO_ 260 LpcLpc1CanFr01_20ms : 32 LPC
 SG_ DayNitSts_UB : 104|1@0+ (1,0) [0|1] "" LPCdp
 SG_ DayNitStsChks : 80|8@1+ (1.0,0.0) [0.0|255.0] "Unitless" LPCdp
 SG_ DayNitStsCntr : 88|4@1+ (1.0,0.0) [0.0|15.0] "Unitless" LPCdp
 SG_ DayNitStsValue : 96|2@1+ (1,0) [0|3] "" LPCdp
 SG_ DoorDrvrStsSafe_UB : 107|1@0+ (1,0) [0|1] "" LPCdp
 SG_ DoorDrvrStsSafeChks : 160|8@1+ (1.0,0.0) [0.0|255.0] "Unitless" LPCdp
 SG_ DoorDrvrStsSafeCntr : 168|4@1+ (1.0,0.0) [0.0|15.0] "Unitless" LPCdp
 SG_ DoorDrvrStsSafeDoorSts : 176|2@1+ (1,0) [0|3] "" LPCdp
 SG_ ExLiHcFltHdlampHozlLe : 79|1@0+ (1,0) [0|1] "" LPCdp
 SG_ ExLiHcFltHdlampHozlLe_UB : 78|1@0+ (1,0) [0|1] "" LPCdp
 SG_ ExLiHcFltHdlampHozlRi : 77|1@0+ (1,0) [0|1] "" LPCdp
 SG_ ExLiHcFltHdlampHozlRi_UB : 76|1@0+ (1,0) [0|1] "" LPCdp
 SG_ ExLiHcFltHdlampIndcrTurnLe_UB : 105|1@0+ (1,0) [0|1] "" LPCdp
 SG_ ExLiHcFltHdlampIndcrTurnLeChks : 112|8@1+ (1.0,0.0) [0.0|255.0] "Unitless" LPCdp
 SG_ ExLiHcFltHdlampIndcrTurnLeCntr : 120|4@1+ (1.0,0.0) [0.0|15.0] "Unitless" LPCdp
 SG_ ExLiHcFltHdlampIndcrTurnLeSts : 128|1@1+ (1,0) [0|1] "" LPCdp
 SG_ ExLiHcFltHdlampIndcrTurnRi_UB : 106|1@0+ (1,0) [0|1] "" LPCdp
 SG_ ExLiHcFltHdlampIndcrTurnRiChks : 136|8@1+ (1.0,0.0) [0.0|255.0] "Unitless" LPCdp
 SG_ ExLiHcFltHdlampIndcrTurnRiCntr : 144|4@1+ (1.0,0.0) [0.0|15.0] "Unitless" LPCdp
 SG_ ExLiHcFltHdlampIndcrTurnRiSts : 152|1@1+ (1,0) [0|1] "" LPCdp
 SG_ ExLiHcFltHdlampLvlLe : 75|1@0+ (1,0) [0|1] "" LPCdp
 SG_ ExLiHcFltHdlampLvlLe_UB : 74|1@0+ (1,0) [0|1] "" LPCdp
 SG_ ExLiHcFltHdlampLvlRi : 73|1@0+ (1,0) [0|1] "" LPCdp
 SG_ ExLiHcFltHdlampLvlRi_UB : 72|1@0+ (1,0) [0|1] "" LPCdp
 SG_ ExLiHcHdlampConcealFltLe : 7|1@0+ (1,0) [0|1] "" LPCdp
 SG_ ExLiHcHdlampConcealFltLe_UB : 24|1@0+ (1,0) [0|1] "" LPCdp
 SG_ ExLiHcHdlampConcealFltRi : 15|1@0+ (1,0) [0|1] "" LPCdp
 SG_ ExLiHcHdlampConcealFltRi_UB : 14|1@0+ (1,0) [0|1] "" LPCdp
 SG_ ExLiHcHdlampConcealStsLe_UB : 38|1@0+ (1,0) [0|1] "" LPCdp
 SG_ ExLiHcHdlampConcealStsLePosnSts : 23|3@0+ (1,0) [0|7] "" LPCdp
 SG_ ExLiHcHdlampConcealStsLeRefSts : 20|2@0+ (1,0) [0|3] "" LPCdp
 SG_ ExLiHcHdlampConcealStsRi_UB : 186|1@0+ (1,0) [0|1] "" LPCdp
 SG_ ExLiHcHdlampConcealStsRiPosnSts : 191|3@0+ (1,0) [0|7] "" LPCdp
 SG_ ExLiHcHdlampConcealStsRiRefSts : 188|2@0+ (1,0) [0|3] "" LPCdp
 SG_ ExLiHcHozlRefStsLe : 71|2@0+ (1,0) [0|3] "" LPCdp
 SG_ ExLiHcHozlRefStsLe_UB : 63|1@0+ (1,0) [0|1] "" LPCdp
 SG_ ExLiHcHozlRefStsRi : 69|2@0+ (1,0) [0|3] "" LPCdp
 SG_ ExLiHcHozlRefStsRi_UB : 62|1@0+ (1,0) [0|1] "" LPCdp
 SG_ ExLiHcLvlRefStsLe : 67|2@0+ (1,0) [0|3] "" LPCdp
 SG_ ExLiHcLvlRefStsLe_UB : 61|1@0+ (1,0) [0|1] "" LPCdp
 SG_ ExLiHcLvlRefStsRi : 65|2@0+ (1,0) [0|3] "" LPCdp
 SG_ ExLiHcLvlRefStsRi_UB : 60|1@0+ (1,0) [0|1] "" LPCdp
 SG_ ExLiHdCalibrationDtcLe : 111|1@0+ (1,0) [0|1] "" LPCdp
 SG_ ExLiHdCalibrationDtcLe_UB : 110|1@0+ (1,0) [0|1] "" LPCdp
 SG_ ExLiHdCalibrationDtcRi : 109|1@0+ (1,0) [0|1] "" LPCdp
 SG_ ExLiHdCalibrationDtcRi_UB : 108|1@0+ (1,0) [0|1] "" LPCdp
 SG_ ExLiHWLRequest : 58|1@0+ (1,0) [0|1] "" LPCdp
 SG_ ExLiHWLRequest_UB : 59|1@0+ (1,0) [0|1] "" LPCdp
 SG_ ExLiLpFltRearPosLi_UB : 6|1@0+ (1,0) [0|1] "" LPCdp
 SG_ ExLiLpFltRearPosLiLe : 3|2@0+ (1,0) [0|3] "" LPCdp
 SG_ ExLiLpFltRearPosLiRi : 5|2@0+ (1,0) [0|3] "" LPCdp
 SG_ ExLiLpFltRegPlate : 26|2@0+ (1,0) [0|3] "" LPCdp
 SG_ ExLiLpFltRegPlate_UB : 27|1@0+ (1,0) [0|1] "" LPCdp
 SG_ FrontWiperStatus : 30|3@0+ (1,0) [0|7] "" LPCdp
 SG_ FrontWiperStatus_UB : 31|1@0+ (1,0) [0|1] "" LPCdp
 SG_ IntrLiMgrSts : 47|16@0+ (1.0,0.0) [0.0|65535.0] "Unitless" LPCdp
 SG_ IntrLiMgrSts_UB : 39|1@0+ (1,0) [0|1] "" LPCdp
 SG_ OhcDefrstReq : 56|1@0+ (1,0) [0|1] "" LPCdp
 SG_ OhcDefrstReq_UB : 57|1@0+ (1,0) [0|1] "" LPCdp
 SG_ RainLiCmd : 12|1@0+ (1,0) [0|1] "" LPCdp
 SG_ RainLiCmd_UB : 13|1@0+ (1,0) [0|1] "" LPCdp
 SG_ Washer : 33|2@0+ (1,0) [0|3] "" LPCdp
 SG_ Washer_UB : 34|1@0+ (1,0) [0|1] "" LPCdp
 SG_ WasherRearStatus : 36|2@0+ (1,0) [0|3] "" LPCdp
 SG_ WasherRearStatus_UB : 37|1@0+ (1,0) [0|1] "" LPCdp
 SG_ WiprInPosnForSrv : 10|1@0+ (1,0) [0|1] "" LPCdp
 SG_ WiprInPosnForSrv_UB : 11|1@0+ (1,0) [0|1] "" LPCdp
 SG_ WiprInWipgAr : 8|1@0+ (1,0) [0|1] "" LPCdp
 SG_ WiprInWipgAr_UB : 9|1@0+ (1,0) [0|1] "" LPCdp
 SG_ WshrFldSts1WdElmHMI : 0|1@0+ (1,0) [0|1] "" LPCdp
 SG_ WshrFldSts1WdElmHMI_UB : 1|1@0+ (1,0) [0|1] "" LPCdp

BO_ 259 LpcLpc1CanFr01_500ms : 12 LPC
 SG_ DiagcInfoForSunSnsr_UB : 62|1@0+ (1,0) [0|1] "" LPCdp
 SG_ DiagcInfoForSunSnsrIntErr : 52|1@0+ (1,0) [0|1] "" LPCdp
 SG_ DiagcInfoForSunSnsrLedForSecuFailr : 51|1@0+ (1,0) [0|1] "" LPCdp
 SG_ DiagcInfoForSunSnsrSnsrForTFailr : 50|1@0+ (1,0) [0|1] "" LPCdp
 SG_ DiagcInfoForSunSnsrTmrRst : 49|1@0+ (1,0) [0|1] "" LPCdp
 SG_ DiagcInfoForSunSnsrUHi : 48|1@0+ (1,0) [0|1] "" LPCdp
 SG_ DiagcInfoForSunSnsrULo : 63|1@0+ (1,0) [0|1] "" LPCdp
 SG_ SunSnsr_UB : 21|1@0+ (1,0) [0|1] "" LPCdp
 SG_ SunSnsrDshbT : 7|8@0+ (1.0,-40.0) [-40.0|125.0] "Deg" LPCdp
 SG_ SunSnsrQf : 23|2@0+ (1,0) [0|3] "" LPCdp
 SG_ SunSnsrSunLoad : 15|8@0+ (3.0,0.0) [0.0|720.0] "W/m2" LPCdp

BO_ 261 LpcLpc1CanFr02_10ms : 32 LPC
 SG_ DetnOfMovmtInCbnReLeRecIf_UB : 0|1@0+ (1,0) [0|1] "" LPCdp
 SG_ DetnOfMovmtInCbnReLeRecIfDetnSts : 7|2@0+ (1,0) [0|3] "" LPCdp
 SG_ DetnOfMovmtInCbnReLeRecIfIntrDetnAvlSts : 5|3@0+ (1,0) [0|7] "" LPCdp
 SG_ DetnOfMovmtInCbnReLeRecIfIntrDetnOf : 2|2@0+ (1,0) [0|3] "" LPCdp
 SG_ DetnOfMovmtInCbnReRiRecIf_UB : 8|1@0+ (1,0) [0|1] "" LPCdp
 SG_ DetnOfMovmtInCbnReRiRecIfDetnSts : 15|2@0+ (1,0) [0|3] "" LPCdp
 SG_ DetnOfMovmtInCbnReRiRecIfIntrDetnAvlSts : 13|3@0+ (1,0) [0|7] "" LPCdp
 SG_ DetnOfMovmtInCbnReRiRecIfIntrDetnOf : 10|2@0+ (1,0) [0|3] "" LPCdp
 SG_ DetnOfMovmtInCbnThrdLeRecIf_UB : 16|1@0+ (1,0) [0|1] "" LPCdp
 SG_ DetnOfMovmtInCbnThrdLeRecIfDetnSts : 23|2@0+ (1,0) [0|3] "" LPCdp
 SG_ DetnOfMovmtInCbnThrdLeRecIfIntrDetnAvlSts : 21|3@0+ (1,0) [0|7] "" LPCdp
 SG_ DetnOfMovmtInCbnThrdLeRecIfIntrDetnOf : 18|2@0+ (1,0) [0|3] "" LPCdp
 SG_ DetnOfMovmtInCbnThrdRiRecIf_UB : 24|1@0+ (1,0) [0|1] "" LPCdp
 SG_ DetnOfMovmtInCbnThrdRiRecIfDetnSts : 31|2@0+ (1,0) [0|3] "" LPCdp
 SG_ DetnOfMovmtInCbnThrdRiRecIfIntrDetnAvlSts : 29|3@0+ (1,0) [0|7] "" LPCdp
 SG_ DetnOfMovmtInCbnThrdRiRecIfIntrDetnOf : 26|2@0+ (1,0) [0|3] "" LPCdp
 SG_ DetnOfMovmtInCbnTrMovmtRecIf_UB : 32|1@0+ (1,0) [0|1] "" LPCdp
 SG_ DetnOfMovmtInCbnTrMovmtRecIfDetnSts : 39|2@0+ (1,0) [0|3] "" LPCdp
 SG_ DetnOfMovmtInCbnTrMovmtRecIfIntrDetnAvlSts : 37|3@0+ (1,0) [0|7] "" LPCdp
 SG_ DetnOfMovmtInCbnTrMovmtRecIfIntrDetnOf : 34|2@0+ (1,0) [0|3] "" LPCdp
 SG_ DetnOfPresInSeatReLeRecIf_UB : 40|1@0+ (1,0) [0|1] "" LPCdp
 SG_ DetnOfPresInSeatReLeRecIfDetnSts : 47|2@0+ (1,0) [0|3] "" LPCdp
 SG_ DetnOfPresInSeatReLeRecIfIntrDetnAvlSts : 45|3@0+ (1,0) [0|7] "" LPCdp
 SG_ DetnOfPresInSeatReLeRecIfIntrDetnOf : 42|2@0+ (1,0) [0|3] "" LPCdp
 SG_ DetnOfPresInSeatReMidRecIf_UB : 48|1@0+ (1,0) [0|1] "" LPCdp
 SG_ DetnOfPresInSeatReMidRecIfDetnSts : 55|2@0+ (1,0) [0|3] "" LPCdp
 SG_ DetnOfPresInSeatReMidRecIfIntrDetnAvlSts : 53|3@0+ (1,0) [0|7] "" LPCdp
 SG_ DetnOfPresInSeatReMidRecIfIntrDetnOf : 50|2@0+ (1,0) [0|3] "" LPCdp
 SG_ DetnOfPresInSeatReRiRecIf_UB : 56|1@0+ (1,0) [0|1] "" LPCdp
 SG_ DetnOfPresInSeatReRiRecIfDetnSts : 63|2@0+ (1,0) [0|3] "" LPCdp
 SG_ DetnOfPresInSeatReRiRecIfIntrDetnAvlSts : 61|3@0+ (1,0) [0|7] "" LPCdp
 SG_ DetnOfPresInSeatReRiRecIfIntrDetnOf : 58|2@0+ (1,0) [0|3] "" LPCdp
 SG_ DetnOfPresInSeatThrdLeRecIf_UB : 64|1@0+ (1,0) [0|1] "" LPCdp
 SG_ DetnOfPresInSeatThrdLeRecIfDetnSts : 71|2@0+ (1,0) [0|3] "" LPCdp
 SG_ DetnOfPresInSeatThrdLeRecIfIntrDetnAvlSts : 69|3@0+ (1,0) [0|7] "" LPCdp
 SG_ DetnOfPresInSeatThrdLeRecIfIntrDetnOf : 66|2@0+ (1,0) [0|3] "" LPCdp
 SG_ DetnOfPresInSeatThrdRiRecIf_UB : 72|1@0+ (1,0) [0|1] "" LPCdp
 SG_ DetnOfPresInSeatThrdRiRecIfDetnSts : 79|2@0+ (1,0) [0|3] "" LPCdp
 SG_ DetnOfPresInSeatThrdRiRecIfIntrDetnAvlSts : 77|3@0+ (1,0) [0|7] "" LPCdp
 SG_ DetnOfPresInSeatThrdRiRecIfIntrDetnOf : 74|2@0+ (1,0) [0|3] "" LPCdp
 SG_ DetnOfPresReLeRecIf_UB : 80|1@0+ (1,0) [0|1] "" LPCdp
 SG_ DetnOfPresReLeRecIfDetnSts : 87|2@0+ (1,0) [0|3] "" LPCdp
 SG_ DetnOfPresReLeRecIfIntrDetnAvlSts : 85|3@0+ (1,0) [0|7] "" LPCdp
 SG_ DetnOfPresReLeRecIfIntrDetnOf : 82|2@0+ (1,0) [0|3] "" LPCdp
 SG_ DetnOfPresReMidRecIf_UB : 88|1@0+ (1,0) [0|1] "" LPCdp
 SG_ DetnOfPresReMidRecIfDetnSts : 95|2@0+ (1,0) [0|3] "" LPCdp
 SG_ DetnOfPresReMidRecIfIntrDetnAvlSts : 93|3@0+ (1,0) [0|7] "" LPCdp
 SG_ DetnOfPresReMidRecIfIntrDetnOf : 90|2@0+ (1,0) [0|3] "" LPCdp
 SG_ DetnOfPresReRiRecIf_UB : 96|1@0+ (1,0) [0|1] "" LPCdp
 SG_ DetnOfPresReRiRecIfDetnSts : 103|2@0+ (1,0) [0|3] "" LPCdp
 SG_ DetnOfPresReRiRecIfIntrDetnAvlSts : 101|3@0+ (1,0) [0|7] "" LPCdp
 SG_ DetnOfPresReRiRecIfIntrDetnOf : 98|2@0+ (1,0) [0|3] "" LPCdp
 SG_ DetnOfPresThrdLeRecIf_UB : 104|1@0+ (1,0) [0|1] "" LPCdp
 SG_ DetnOfPresThrdLeRecIfDetnSts : 111|2@0+ (1,0) [0|3] "" LPCdp
 SG_ DetnOfPresThrdLeRecIfIntrDetnAvlSts : 109|3@0+ (1,0) [0|7] "" LPCdp
 SG_ DetnOfPresThrdLeRecIfIntrDetnOf : 106|2@0+ (1,0) [0|3] "" LPCdp
 SG_ DetnOfPresThrdRiRecIf_UB : 112|1@0+ (1,0) [0|1] "" LPCdp
 SG_ DetnOfPresThrdRiRecIfDetnSts : 119|2@0+ (1,0) [0|3] "" LPCdp
 SG_ DetnOfPresThrdRiRecIfIntrDetnAvlSts : 117|3@0+ (1,0) [0|7] "" LPCdp
 SG_ DetnOfPresThrdRiRecIfIntrDetnOf : 114|2@0+ (1,0) [0|3] "" LPCdp
 SG_ DetnOfTrPresRecIf_UB : 120|1@0+ (1,0) [0|1] "" LPCdp
 SG_ DetnOfTrPresRecIfDetnSts : 127|2@0+ (1,0) [0|3] "" LPCdp
 SG_ DetnOfTrPresRecIfIntrDetnAvlSts : 125|3@0+ (1,0) [0|7] "" LPCdp
 SG_ DetnOfTrPresRecIfIntrDetnOf : 122|2@0+ (1,0) [0|3] "" LPCdp
 SG_ ExLiLpReBrkLiFlt_UB : 148|1@0+ (1,0) [0|1] "" LPCdp
 SG_ ExLiLpReBrkLiFltChks : 128|8@1+ (1.0,0.0) [0.0|255.0] "Unitless" LPCdp
 SG_ ExLiLpReBrkLiFltCntr : 136|4@1+ (1.0,0.0) [0.0|15.0] "Unitless" LPCdp
 SG_ ExLiLpReBrkLiFltReBrkLiLeFlt : 144|2@1+ (1,0) [0|3] "" LPCdp
 SG_ ExLiLpReBrkLiFltReBrkLiReFlt : 146|2@1+ (1,0) [0|3] "" LPCdp
 SG_ ExLiLpReFogLiFlt_UB : 149|1@0+ (1,0) [0|1] "" LPCdp
 SG_ ExLiLpReFogLiFltLe : 153|2@0+ (1,0) [0|3] "" LPCdp
 SG_ ExLiLpReFogLiFltRi : 155|2@0+ (1,0) [0|3] "" LPCdp
 SG_ ExLiLpRevLiFlt_UB : 150|1@0+ (1,0) [0|1] "" LPCdp
 SG_ ExLiLpRevLiFltLe : 157|2@0+ (1,0) [0|3] "" LPCdp
 SG_ ExLiLpRevLiFltRi : 159|2@0+ (1,0) [0|3] "" LPCdp
 SG_ LpcReqNfcRespIntrEth : 160|1@0+ (1,0) [0|1] "" LPCdp
 SG_ LpcReqNfcRespIntrEth_UB : 151|1@0+ (1,0) [0|1] "" LPCdp

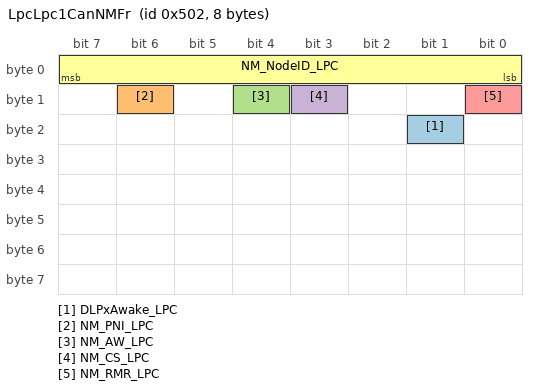
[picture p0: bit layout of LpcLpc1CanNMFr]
BO_ 1282 LpcLpc1CanNMFr : 8 LPC
 SG_ DLPxAwake_LPC : 17|1@0+ (1,0) [0|0] "" LPCdp
 SG_ NM_PNI_LPC : 14|1@0+ (1,0) [0|0] "" LPCdp
 SG_ NM_AW_LPC : 12|1@0+ (1,0) [0|0] "" LPCdp
 SG_ NM_CS_LPC : 11|1@0+ (1,0) [0|0] "" LPCdp
 SG_ NM_RMR_LPC : 8|1@0+ (1,0) [0|0] "" LPCdp
 SG_ NM_NodeID_LPC : 7|8@0+ (1,0) [0|0] "" LPCdp

BO_ 1411 LpcToLpcEtcLpc1canXcpFr01 : 64 LPC

BO_ 1412 LpcToLpcEtcLpc1canXcpFr02 : 64 LPC

BO_ 1413 LpcToLpcEtcLpc1canXcpFr03 : 64 LPC

BO_ 1414 LpcToLpcEtcLpc1canXcpFr04 : 64 LPC

BO_ 1415 LpcToLpcEtcLpc1canXcpFr05 : 64 LPC

BO_ 1416 LpcToLpcEtcLpc1canXcpFr06 : 64 LPC

BO_ 1417 LpcToLpcEtcLpc1canXcpFr07 : 64 LPC

BO_ 1418 LpcToLpcEtcLpc1canXcpFr08 : 64 LPC

BO_ 1419 LpcToLpcEtcLpc1canXcpFr09 : 64 LPC

BO_ 1420 LpcToLpcEtcLpc1canXcpFr10 : 64 LPC

CM_ SG_ 337 AdPrimWhlAgEstimdGroupSafeChks "E2E Checksum";
CM_ SG_ 337 AdPrimWhlAgEstimdGroupSafeCntr "E2E Counter";
CM_ SG_ 337 AdPrimWhlAgEstimdGroupSafeQf1 "Quality Factor of the rack position¨";
CM_ SG_ 337 AdPrimWhlAgEstimdGroupSafeWhlAg "Wheel angle estimate";
CM_ SG_ 337 AdPrimWhlAgEstimdGroupSafeWhlAgRate "Wheel angle rate estimate.";
CM_ SG_ 337 EpbSts2EpbSts "Status of the parking brake system";
CM_ SG_ 337 EpbSts2EpbStsChks "Checksum for EPB status";
CM_ SG_ 337 EpbSts2EpbStsCntr "Counter for EPB status";
CM_ SG_ 337 FrntLeWhlSpdSnsrDataChks "E2E CheckSum";
CM_ SG_ 337 FrntLeWhlSpdSnsrDataCntr "E2E Counter";
CM_ SG_ 337 FrntLeWhlSpdSnsrDataWhlAgSpdFrntLe "Wheel angle speed for front left wheel";
CM_ SG_ 337 FrntLeWhlSpdSnsrDataWhlAgSpdFrntLeQf "Wheel angle speed for front left wheel Qf";
CM_ SG_ 337 FrntLeWhlSpdSnsrDataWhlRotDirFrntLe "Wheel rotation direction for front left wheel";
CM_ SG_ 337 FrntLeWhlSpdSnsrDataWhlRotDirFrntLeQf "Wheel rotation direction for front left wheel Qf";
CM_ SG_ 337 FrntLeWhlSpdSnsrDataWhlRotToothCntrFrntLe "Wheel Rotation Tooth Counter Record for front left wheel";
CM_ SG_ 337 FrntLeWhlSpdSnsrDataWhlRotToothCntrFrntLeQf "Wheel Rotation Tooth Counter Record for front left wheel Qf";
CM_ SG_ 337 FrntRiWhlSpdSnsrDataChks "E2E CheckSum";
CM_ SG_ 337 FrntRiWhlSpdSnsrDataCntr "E2E Counter";
CM_ SG_ 337 FrntRiWhlSpdSnsrDataWhlAgSpdFrntRi "Wheel angle speed for front right wheel";
CM_ SG_ 337 FrntRiWhlSpdSnsrDataWhlAgSpdFrntRiQf "Wheel angle speed for front right wheel Qf";
CM_ SG_ 337 FrntRiWhlSpdSnsrDataWhlRotDirFrntRi "Wheel rotation direction for front right wheel";
CM_ SG_ 337 FrntRiWhlSpdSnsrDataWhlRotDirFrntRiQf "Wheel rotation direction for front right wheel Qf";
CM_ SG_ 337 FrntRiWhlSpdSnsrDataWhlRotToothCntrFrntRi "Wheel Rotation Tooth Counter record for front right wheel";
CM_ SG_ 337 FrntRiWhlSpdSnsrDataWhlRotToothCntrFrntRiQf "Wheel Rotation Tooth Counter Record for front right wheel Qf";
CM_ SG_ 337 IMURawDataIMULatAccRaw "IMU Lateral Acceleration Raw Data ";
CM_ SG_ 337 IMURawDataIMULatAccRawQf "IMU Lateral Acceleration Raw Quality Factor";
CM_ SG_ 337 IMURawDataIMULongAccRaw "IMU Longitudinal Acceleration Raw Data";
CM_ SG_ 337 IMURawDataIMULongAccRawQf "IMU Longitudinal Acceleration Raw Quality Factor";
CM_ SG_ 337 IMURawDataIMUPitchRateRaw "IMU Pitch Rate Raw Data";
CM_ SG_ 337 IMURawDataIMUPitchRateRawQf "IMU Pitch Rate Raw Quality Factor";
CM_ SG_ 337 IMURawDataIMURollRateRaw "IMU Roll Rate Raw Data";
CM_ SG_ 337 IMURawDataIMURollRateRawQf "IMU Roll Rate Raw Quality Factor";
CM_ SG_ 337 IMURawDataIMUVertAccRaw "IMU Vertical Acceleration Raw Data";
CM_ SG_ 337 IMURawDataIMUVertAccRawQf "IMU Vertical Acceleration Raw Quality Factor";
CM_ SG_ 337 IMURawDataIMUYawRateRaw "IMU Yaw Rate Raw Data";
CM_ SG_ 337 IMURawDataIMUYawRateRawQf "IMU Yaw Rate Raw Quality Factor";
CM_ SG_ 337 IMURawDataIndicationChks "IMU Raw Data Indication E2E Protection Checksum";
CM_ SG_ 337 IMURawDataIndicationCntr "IMU Raw Data Indication E2E Protection Counter";
CM_ SG_ 337 NFSStMacStsNFSActvSt "NFS Status";
CM_ SG_ 337 NFSStMacStsNFSIntrfInfoTyp "NFS Interface";
CM_ SG_ 337 ReLeWhlSpdSnsrDataChks "E2E CheckSum";
CM_ SG_ 337 ReLeWhlSpdSnsrDataCntr "E2E Counter";
CM_ SG_ 337 ReLeWhlSpdSnsrDataWhlAgSpdReLe "Wheel angle speed for rear left wheel";
CM_ SG_ 337 ReLeWhlSpdSnsrDataWhlAgSpdReLeQf "Wheel angle speed for rear left wheel Qf";
CM_ SG_ 337 ReLeWhlSpdSnsrDataWhlRotDirReLe "Wheel rotation direction for rear left wheel";
CM_ SG_ 337 ReLeWhlSpdSnsrDataWhlRotDirReLeQf "Wheel rotation direction for rear left wheel Qf";
CM_ SG_ 337 ReLeWhlSpdSnsrDataWhlRotToothCntrReLe "Wheel Rotation Tooth Counter Record for rear left wheel";
CM_ SG_ 337 ReLeWhlSpdSnsrDataWhlRotToothCntrReLeQf "Wheel Rotation Tooth Counter Record for rear left wheel Qf";
CM_ SG_ 337 ReRiWhlSpdSnsrDataChks "E2E CheckSum";
CM_ SG_ 337 ReRiWhlSpdSnsrDataCntr "E2E Counter";
CM_ SG_ 337 ReRiWhlSpdSnsrDataWhlAgSpdReRi "Wheel angle speed for rear right wheel";
CM_ SG_ 337 ReRiWhlSpdSnsrDataWhlAgSpdReRiQf "Wheel angle speed for rear right wheel Qf";
CM_ SG_ 337 ReRiWhlSpdSnsrDataWhlRotDirReRi "Wheel rotation direction for rear right wheel";
CM_ SG_ 337 ReRiWhlSpdSnsrDataWhlRotDirReRiQf "Wheel rotation direction for rear right wheel Qf";
CM_ SG_ 337 ReRiWhlSpdSnsrDataWhlRotToothCntrReRi "Wheel Rotation Tooth Counter Record for rear right wheel";
CM_ SG_ 337 ReRiWhlSpdSnsrDataWhlRotToothCntrReRiQf "Wheel Rotation Tooth Counter Record for rear right wheel Qf";
CM_ SG_ 337 SteerWhlTq2 "Measured steer wheel torque";
CM_ SG_ 337 TrsmParkLockdSafe2TrsmParkLockd "Transmission park lock status";
CM_ SG_ 337 TrsmParkLockdSafe2TrsmParkLockdChks "Checksum for TrsmParkLockd";
CM_ SG_ 337 TrsmParkLockdSafe2TrsmParkLockdCntr "Counter for TrsmParkLockd";
CM_ SG_ 337 VehMtnStSafe3VehMtnSt "Vehicle motion state";
CM_ SG_ 337 VehMtnStSafe3VehMtnStChks "Checksum for vehicle motion state";
CM_ SG_ 337 VehMtnStSafe3VehMtnStCntr "Counter for vehicle motion state";
CM_ SG_ 339 CarTiGlb "Presents a tiime value that shall be used by all ECUs to time-stamp diagnsotic trouble codes (DTC) according to the requirements for Global DTC snapshot data.";
CM_ SG_ 339 OutdTAmbTVal "Ambient temp value";
CM_ SG_ 339 OutdTQly "Quality Factor of the ambient temp";
CM_ SG_ 339 VehBattUSysU "System Voltage";
CM_ SG_ 339 VehBattUSysUQf "System voltaeg quality factor";
CM_ SG_ 257 AlrmPasRst "Reset passive arm in IHU";
CM_ SG_ 257 AlrmRednSts "Is the reduced Guard on";
CM_ SG_ 257 AlrmSnsrStsInclination "Detects inclination change in vehicle";
CM_ SG_ 257 AlrmSnsrStsInteriorMotion "Detects movement inside vehicle";
CM_ SG_ 257 AlrmSnsrStsPerimeter "Detects if doors are opened when armed";
CM_ SG_ 257 AlrmSnsrStsSirenConnected "Detects if connection with siren is lost";
CM_ SG_ 257 AlrmSts "Used to send Alarm Status from Theft  Protection to Exterior Alarm Module";
CM_ SG_ 257 AlrmTrgSrc "Shows the source of the alarm activation.";
CM_ SG_ 257 AmbIllmnFwdSts2AmbLiIllmn "Illuminance in Lux from forward light sensor";
CM_ SG_ 257 AmbIllmnFwdSts2Chks "CRC Checksum";
CM_ SG_ 257 AmbIllmnFwdSts2Cntr "Send counter used for sequence check";
CM_ SG_ 257 CenLockStsLockSrc "Lock source";
CM_ SG_ 257 CenLockStsLockSts "Lock status";
CM_ SG_ 257 CenLockStsUpdEve "Update event";
CM_ SG_ 257 ChdLockStsDoorDrvrRe "Rear driver door";
CM_ SG_ 257 ChdLockStsDoorPass "Passenger door";
CM_ SG_ 257 ChdLockStsDoorPassRe "Rear passenger door";
CM_ SG_ 257 ChdWinProtnStsAtDrvrRe "'Signal sent from the rear driver door module to the Driver door module that informs of the local status of the power window disable functionality.
'
";
CM_ SG_ 257 ChdWinProtnStsAtPass "Windows child protection command to disable the  local window operation at passenger door";
CM_ SG_ 257 ChdWinProtnStsAtPassRe "'Signal sent from the rear passenger door module to the Driver door module that informs of the local status of the power window disable functionality.
'
";
CM_ SG_ 257 DoorDrvrSts "DoorDrvrSts - Driver Door Status

Ukwn - Unknown status
Opend - Opened
Clsd - Closed";
CM_ SG_ 257 DoorDrvrStsRe "DoorDrvrReSts - Driver Side Rear Door Status

Ukwn - Unknown status
Opend - Opened
Clsd - Closed";
CM_ SG_ 257 DoorPassSts "DoorPassSts - Passenger Door Status

Ukwn - Unknown status
Opend - Opened
Clsd - Closed";
CM_ SG_ 257 DoorPassStsRe "DoorPassReSts - Passenger Side Rear Door Status

Ukwn - Unknown status
Opend - Opened
Clsd - Closed";
CM_ SG_ 257 DrvrGearShiftDirReqAuxChks "Checksum";
CM_ SG_ 257 DrvrGearShiftDirReqAuxCntr "Counter";
CM_ SG_ 257 DrvrGearShiftDirReqAuxDrvrGearShiftDirReqAukSts "Safety Level Status";
CM_ SG_ 257 DrvrGearShiftDirReqAuxPosn "Gear Shiter Position";
CM_ SG_ 257 FltBrkLiIndcn "Faulty brake light information from LPC to VCU.";
CM_ SG_ 257 FwdLookCamHeatingSts "Heating status from OHC";
CM_ SG_ 257 GlvBoxSts "Status of glove box.";
CM_ SG_ 257 HoodSts "HoodSts - Hood Status

Ukwn - Unknown status
Opend - Opened
Clsd - Closed";
CM_ SG_ 257 LcmaLedStsDrvrSide "Signal which indicates if the LCMA LED HMI is broken or not.";
CM_ SG_ 257 LcmaLedStsPassSide "Signal which indicates if the LCMA LED HMI is broken or not.";
CM_ SG_ 257 LockgCenStsForUsrFb "LockgCenStsForUsrFb - Central Locking Status for User Feedback

The signal is used to communicate central locking status to the user of the vehicle

Undefd - ?Undefined status (to be used when sufficient information about door and lock status is not available)
Opend - ?At least one door or taligate/bootlid or hood is open
Clsd (Closed) - ?All doors, tailgate/bootlid and hood are closed (at least one door or tailgate/bootlid is unlocked)
Lockd (Locked) - ?All doors, tailgate/bootlid and hood are closed and all doors and tailgate/bootlid are locked (at least one door is unsafed)
Safe - ?All doors, tailgate/bootlid and hood are closed, tailgate/bootlid is locked and all doors are safed (double locked)";
CM_ SG_ 257 LockgPrvtSts "Private locking status read from memory.";
CM_ SG_ 257 MirrFoldStsAtDrvr "Reports the fold status of the outer rear view mirrors. Driver side.";
CM_ SG_ 257 MirrFoldStsAtPass "Reports the fold status of the outer rear view mirrors. Passanger side.";
CM_ SG_ 257 MirrPosnSensFdbValDrvrMirrSensXPos " sensor value of X axis";
CM_ SG_ 257 MirrPosnSensFdbValDrvrMirrSensYPos "sensor value of Y axis";
CM_ SG_ 257 MirrPosnSensFdbValPassMirrSensXPos " sensor value of X axis";
CM_ SG_ 257 MirrPosnSensFdbValPassMirrSensYPos "sensor value of Y axis";
CM_ SG_ 257 SeatRowSecBackRestSwtStsSwtLeSts "Left Side Seat Micro Switch Status";
CM_ SG_ 257 SeatRowSecBackRestSwtStsSwtRiSts "Right Side Seat Micro Switch Status";
CM_ SG_ 257 SeatSwtTrStsLeHalfSts "Luggage Compartment Switch Pack Seat Left Half Status";
CM_ SG_ 257 SeatSwtTrStsRiHalfSts "Luggage Compartment Switch Pack Seat Right Half Status";
CM_ SG_ 257 SftyBltTelltlFlt "Signals indicates if the safety belt reminder telltale in the OHC is broken.";
CM_ SG_ 257 TrlrLampChk "Is it possible to start a trailer lampcheck. Signal sent to DIM that shall ask teh user if user wants to start a traielr lamp check";
CM_ SG_ 257 TrlrLampChkSts "Status on trailer lamp check in Towbar control SWC. Signal sent to DIM som DIM can control Popups";
CM_ SG_ 257 TrlrLiSts "Status of brake light and indicators on a trailer";
CM_ SG_ 257 TrlrSrvReqToHMI "Signal to HMI to request a trailer service request popup in DIM";
CM_ SG_ 257 TrSts "TrSts - Tailgate/Bootlid Status

Ukwn - Unknown status
Opend - Opened
Clsd - Closed";
CM_ SG_ 257 TurnIndcrFaultChks "Checksum";
CM_ SG_ 257 TurnIndcrFaultCntr "Counter";
CM_ SG_ 257 TurnIndcrFaultRearLe "Rear Left Turn Indicator Fault";
CM_ SG_ 257 TurnIndcrFaultRearRi "Rear Right Turn Indicator Fault";
CM_ SG_ 257 TurnIndcrFaultSideLe "Left Side Turn Indicator Fault";
CM_ SG_ 257 TurnIndcrFaultSideRi "Right Side Turn Indicator Fault";
CM_ SG_ 257 TwbrStsTwbrSts "What is the position of the Tow Bar. Has values for both fully and semi electrical";
CM_ SG_ 257 TwbrStsTwbrTyp "Which type of Tow Bar is attached to the vehicle";
CM_ SG_ 257 WinPosnStsAtDrv "'Signal sent to inform the rest of the car of the window position status for the front driver side door. The value of the signal is either an approximated percentage of openness, of the window is moving or if the position is unkown.
'
";
CM_ SG_ 257 WinPosnStsAtDrvrRe "'Signal sent to inform the rest of the car of the window position status for the rear driver side door. The value of the signal is either an approximated percentage of openness, of the window is moving or if the position is unkown.
'
";
CM_ SG_ 257 WinPosnStsAtPass "'Signal sent to inform the rest of the car of the window position status for the front passenger side door. The value of the signal is either an approximated percentage of openness, of the window is moving or if the position is unkown.
'
";
CM_ SG_ 257 WinPosnStsAtPassRe "'Signal sent to inform the rest of the car of the window position status for the rear passenger side door. The value of the signal is either an approximated percentage of openness, of the window is moving or if the position is unkown.
'
";
CM_ SG_ 256 AutoIllumReq1RCSMDelayTime "Delay time";
CM_ SG_ 256 AutoIllumReq1RCSMPWM1 "PWM duty steps";
CM_ SG_ 256 AutoIllumReq1RCSMPWM2 "PWM duty steps";
CM_ SG_ 256 AutoIllumReq1RCSMPWM3 "PWM duty steps";
CM_ SG_ 256 AutoIllumReq1RCSMReserve1 "Reserve bits for future use";
CM_ SG_ 256 AutoIllumReq1RCSMReserve2 "Reserve bits for future use";
CM_ SG_ 256 AutoIllumReq1RCSMTranBehavior "Transition behavior";
CM_ SG_ 256 AutoIllumReq1RCSMTranStep "Transition steps";
CM_ SG_ 256 AutoIllumReqCSDDelayTime "Delay time";
CM_ SG_ 256 AutoIllumReqCSDPWM "PWM duty steps";
CM_ SG_ 256 AutoIllumReqCSDReserve1 "Reserve bit for future use.";
CM_ SG_ 256 AutoIllumReqCSDReserve2 "Reserve bits for future use.";
CM_ SG_ 256 AutoIllumReqCSDTranBehavior "Transition behavior";
CM_ SG_ 256 AutoIllumReqCSDTranStep "Transition steps";
CM_ SG_ 256 AutoIllumReqDIMDelayTime "Delay time";
CM_ SG_ 256 AutoIllumReqDIMPWM "PWM duty steps";
CM_ SG_ 256 AutoIllumReqDIMReserve1 "Reserve bit for future use.";
CM_ SG_ 256 AutoIllumReqDIMReserve2 "Reserve bits for future use.";
CM_ SG_ 256 AutoIllumReqDIMTranBehavior "Transition behavior";
CM_ SG_ 256 AutoIllumReqDIMTranStep "Transition steps";
CM_ SG_ 256 AutoIllumReqMSMDelayTime "Delay time";
CM_ SG_ 256 AutoIllumReqMSMPWM "PWM duty steps";
CM_ SG_ 256 AutoIllumReqMSMReserve1 "Reserve bit for future use.";
CM_ SG_ 256 AutoIllumReqMSMReserve2 "Reserve bits for future use.";
CM_ SG_ 256 AutoIllumReqMSMTranBehavior "Transition behavior";
CM_ SG_ 256 AutoIllumReqMSMTranStep "Transition steps";
CM_ SG_ 256 AutoIllumReqSWMDelayTime "Delay time";
CM_ SG_ 256 AutoIllumReqSWMPWM "PWM duty steps";
CM_ SG_ 256 AutoIllumReqSWMReserve1 "Reserve bit for future use.";
CM_ SG_ 256 AutoIllumReqSWMReserve2 "Reserve bits for future use.";
CM_ SG_ 256 AutoIllumReqSWMTranBehavior "Transition behavior";
CM_ SG_ 256 AutoIllumReqSWMTranStep "Transition steps";
CM_ SG_ 256 AutoIllumReqSWSDelayTime "Delay time";
CM_ SG_ 256 AutoIllumReqSWSPWM "PWM duty steps";
CM_ SG_ 256 AutoIllumReqSWSReserve1 "Reserve bit for future use.";
CM_ SG_ 256 AutoIllumReqSWSReserve2 "Reserve bits for future use.";
CM_ SG_ 256 AutoIllumReqSWSTranBehavior "Transition behavior";
CM_ SG_ 256 AutoIllumReqSWSTranStep "Transition steps";
CM_ SG_ 256 DrvrDetnOfMovmtInCbnRecIfDetnSts "Shows the detection status.";
CM_ SG_ 256 DrvrDetnOfMovmtInCbnRecIfIntrDetnAvlSts "Shows the availability stsatus of the sensor.";
CM_ SG_ 256 DrvrDetnOfMovmtInCbnRecIfIntrDetnOf "Shows quality of the detection status.";
CM_ SG_ 256 DrvrDetnOfPresInSeatRecIfDetnSts "Shows the detection status.";
CM_ SG_ 256 DrvrDetnOfPresInSeatRecIfIntrDetnAvlSts "Shows the availability stsatus of the sensor.";
CM_ SG_ 256 DrvrDetnOfPresInSeatRecIfIntrDetnOf "Shows quality of the detection status.";
CM_ SG_ 256 DrvrDetnOfPresRecIfDetnSts "Shows the detection status.";
CM_ SG_ 256 DrvrDetnOfPresRecIfIntrDetnAvlSts "Shows the availability stsatus of the sensor.";
CM_ SG_ 256 DrvrDetnOfPresRecIfIntrDetnOf "Shows quality of the detection status.";
CM_ SG_ 256 NfcCardAuthPrnstPakNfcDeviceIDInt "Hold up to 256 IDs. Phone and RFk IDs are reserved for PAK only. 255=Default value/no device";
CM_ SG_ 256 NfcCardAuthPrnstSubZoneLocation "Shows where the NFC card is located (exterior/interior NFC reader)";
CM_ SG_ 256 PassDetnOfMovmtInCbnRecIfDetnSts "Shows the detection status.";
CM_ SG_ 256 PassDetnOfMovmtInCbnRecIfIntrDetnAvlSts "Shows the availability stsatus of the sensor.";
CM_ SG_ 256 PassDetnOfMovmtInCbnRecIfIntrDetnOf "Shows quality of the detection status.";
CM_ SG_ 256 PassDetnOfPresInSeatRecIfDetnSts "Shows the detection status.";
CM_ SG_ 256 PassDetnOfPresInSeatRecIfIntrDetnAvlSts "Shows the availability stsatus of the sensor.";
CM_ SG_ 256 PassDetnOfPresInSeatRecIfIntrDetnOf "Shows quality of the detection status.";
CM_ SG_ 256 PassDetnOfPresRecIfDetnSts "Shows the detection status.";
CM_ SG_ 256 PassDetnOfPresRecIfIntrDetnAvlSts "Shows the availability stsatus of the sensor.";
CM_ SG_ 256 PassDetnOfPresRecIfIntrDetnOf "Shows quality of the detection status.";
CM_ SG_ 256 TrlrPrsnt1 "Is a ttrailer connected to the vehicle";
CM_ SG_ 260 DayNitStsChks "Checksum";
CM_ SG_ 260 DayNitStsCntr "Counter";
CM_ SG_ 260 DoorDrvrStsSafeChks "Checksum";
CM_ SG_ 260 DoorDrvrStsSafeCntr "Counter";
CM_ SG_ 260 DoorDrvrStsSafeDoorSts "Door status";
CM_ SG_ 260 ExLiHcFltHdlampIndcrTurnLeChks "Checksum";
CM_ SG_ 260 ExLiHcFltHdlampIndcrTurnLeCntr "Counter";
CM_ SG_ 260 ExLiHcFltHdlampIndcrTurnLeSts "Turn indicator fault left side";
CM_ SG_ 260 ExLiHcFltHdlampIndcrTurnRiChks "Checksum";
CM_ SG_ 260 ExLiHcFltHdlampIndcrTurnRiCntr "Counter";
CM_ SG_ 260 ExLiHcFltHdlampIndcrTurnRiSts "Turn indicator fault left side";
CM_ SG_ 260 ExLiHcHdlampConcealFltLe "Concealable head lamp fault signal";
CM_ SG_ 260 ExLiHcHdlampConcealStsLePosnSts "Concealable head lamp position status";
CM_ SG_ 260 ExLiHcHdlampConcealStsLeRefSts "Concealable head lamp reference run status";
CM_ SG_ 260 ExLiHcHdlampConcealStsRiPosnSts "Concealable head lamp position status";
CM_ SG_ 260 ExLiHcHdlampConcealStsRiRefSts "Concealable head lamp reference run status";
CM_ SG_ 260 ExLiHdCalibrationDtcLe "Status of DLPL calibration DTC.
True = DTC set
False = DTC not set";
CM_ SG_ 260 ExLiHdCalibrationDtcRi "Status of DLPR calibration DTC.
True = DTC set
False = DTC not set";
CM_ SG_ 260 ExLiLpFltRearPosLiLe "Left Side Fault";
CM_ SG_ 260 ExLiLpFltRearPosLiRi "Right Side Fault";
CM_ SG_ 260 ExLiLpFltRegPlate "Registration Plate Light fault status.";
CM_ SG_ 260 IntrLiMgrSts "Provides the interior light system state scenarios. ";
CM_ SG_ 260 WiprInPosnForSrv "Information regarding when the windscreen wipers are in service position where for example the wipers can be raised for wiper blade exchange.";
CM_ SG_ 260 WiprInWipgAr "Information regarding wiper position on the windscreen.
?Off = Wiper lever out of wiping area (in park segment)
On = Wiper lever in wiping area";
CM_ SG_ 260 WshrFldSts1WdElmHMI "Information regarding if the washer fluid level is low. 
On = Washer Fluid Level Low
Off = Washer Fluid Level Not Low. ";
CM_ SG_ 259 DiagcInfoForSunSnsrIntErr "Internal error detected";
CM_ SG_ 259 DiagcInfoForSunSnsrLedForSecuFailr "Security LED failure";
CM_ SG_ 259 DiagcInfoForSunSnsrSnsrForTFailr "Temperature sensor failure";
CM_ SG_ 259 DiagcInfoForSunSnsrTmrRst "Watchdog timer resetted";
CM_ SG_ 259 DiagcInfoForSunSnsrUHi "Overvoltage detected";
CM_ SG_ 259 DiagcInfoForSunSnsrULo "Undervoltage detected";
CM_ SG_ 261 DetnOfMovmtInCbnReLeRecIfDetnSts "Shows the detection status.";
CM_ SG_ 261 DetnOfMovmtInCbnReLeRecIfIntrDetnAvlSts "Shows the availability stsatus of the sensor.";
CM_ SG_ 261 DetnOfMovmtInCbnReLeRecIfIntrDetnOf "Shows quality of the detection status.";
CM_ SG_ 261 DetnOfMovmtInCbnReRiRecIfDetnSts "Shows the detection status.";
CM_ SG_ 261 DetnOfMovmtInCbnReRiRecIfIntrDetnAvlSts "Shows the availability stsatus of the sensor.";
CM_ SG_ 261 DetnOfMovmtInCbnReRiRecIfIntrDetnOf "Shows quality of the detection status.";
CM_ SG_ 261 DetnOfMovmtInCbnThrdLeRecIfDetnSts "Shows the detection status.";
CM_ SG_ 261 DetnOfMovmtInCbnThrdLeRecIfIntrDetnAvlSts "Shows the availability stsatus of the sensor.";
CM_ SG_ 261 DetnOfMovmtInCbnThrdLeRecIfIntrDetnOf "Shows quality of the detection status.";
CM_ SG_ 261 DetnOfMovmtInCbnThrdRiRecIfDetnSts "Shows the detection status.";
CM_ SG_ 261 DetnOfMovmtInCbnThrdRiRecIfIntrDetnAvlSts "Shows the availability stsatus of the sensor.";
CM_ SG_ 261 DetnOfMovmtInCbnThrdRiRecIfIntrDetnOf "Shows quality of the detection status.";
CM_ SG_ 261 DetnOfMovmtInCbnTrMovmtRecIfDetnSts "Shows the detection status.";
CM_ SG_ 261 DetnOfMovmtInCbnTrMovmtRecIfIntrDetnAvlSts "Shows the availability stsatus of the sensor.";
CM_ SG_ 261 DetnOfMovmtInCbnTrMovmtRecIfIntrDetnOf "Shows quality of the detection status.";
CM_ SG_ 261 DetnOfPresInSeatReLeRecIfDetnSts "Shows the detection status.";
CM_ SG_ 261 DetnOfPresInSeatReLeRecIfIntrDetnAvlSts "Shows the availability stsatus of the sensor.";
CM_ SG_ 261 DetnOfPresInSeatReLeRecIfIntrDetnOf "Shows quality of the detection status.";
CM_ SG_ 261 DetnOfPresInSeatReMidRecIfDetnSts "Shows the detection status.";
CM_ SG_ 261 DetnOfPresInSeatReMidRecIfIntrDetnAvlSts "Shows the availability stsatus of the sensor.";
CM_ SG_ 261 DetnOfPresInSeatReMidRecIfIntrDetnOf "Shows quality of the detection status.";
CM_ SG_ 261 DetnOfPresInSeatReRiRecIfDetnSts "Shows the detection status.";
CM_ SG_ 261 DetnOfPresInSeatReRiRecIfIntrDetnAvlSts "Shows the availability stsatus of the sensor.";
CM_ SG_ 261 DetnOfPresInSeatReRiRecIfIntrDetnOf "Shows quality of the detection status.";
CM_ SG_ 261 DetnOfPresInSeatThrdLeRecIfDetnSts "Shows the detection status.";
CM_ SG_ 261 DetnOfPresInSeatThrdLeRecIfIntrDetnAvlSts "Shows the availability stsatus of the sensor.";
CM_ SG_ 261 DetnOfPresInSeatThrdLeRecIfIntrDetnOf "Shows quality of the detection status.";
CM_ SG_ 261 DetnOfPresInSeatThrdRiRecIfDetnSts "Shows the detection status.";
CM_ SG_ 261 DetnOfPresInSeatThrdRiRecIfIntrDetnAvlSts "Shows the availability stsatus of the sensor.";
CM_ SG_ 261 DetnOfPresInSeatThrdRiRecIfIntrDetnOf "Shows quality of the detection status.";
CM_ SG_ 261 DetnOfPresReLeRecIfDetnSts "Shows the detection status.";
CM_ SG_ 261 DetnOfPresReLeRecIfIntrDetnAvlSts "Shows the availability stsatus of the sensor.";
CM_ SG_ 261 DetnOfPresReLeRecIfIntrDetnOf "Shows quality of the detection status.";
CM_ SG_ 261 DetnOfPresReMidRecIfDetnSts "Shows the detection status.";
CM_ SG_ 261 DetnOfPresReMidRecIfIntrDetnAvlSts "Shows the availability stsatus of the sensor.";
CM_ SG_ 261 DetnOfPresReMidRecIfIntrDetnOf "Shows quality of the detection status.";
CM_ SG_ 261 DetnOfPresReRiRecIfDetnSts "Shows the detection status.";
CM_ SG_ 261 DetnOfPresReRiRecIfIntrDetnAvlSts "Shows the availability stsatus of the sensor.";
CM_ SG_ 261 DetnOfPresReRiRecIfIntrDetnOf "Shows quality of the detection status.";
CM_ SG_ 261 DetnOfPresThrdLeRecIfDetnSts "Shows the detection status.";
CM_ SG_ 261 DetnOfPresThrdLeRecIfIntrDetnAvlSts "Shows the availability stsatus of the sensor.";
CM_ SG_ 261 DetnOfPresThrdLeRecIfIntrDetnOf "Shows quality of the detection status.";
CM_ SG_ 261 DetnOfPresThrdRiRecIfDetnSts "Shows the detection status.";
CM_ SG_ 261 DetnOfPresThrdRiRecIfIntrDetnAvlSts "Shows the availability stsatus of the sensor.";
CM_ SG_ 261 DetnOfPresThrdRiRecIfIntrDetnOf "Shows quality of the detection status.";
CM_ SG_ 261 DetnOfTrPresRecIfDetnSts "Shows the detection status.";
CM_ SG_ 261 DetnOfTrPresRecIfIntrDetnAvlSts "Shows the availability stsatus of the sensor.";
CM_ SG_ 261 DetnOfTrPresRecIfIntrDetnOf "Shows quality of the detection status.";
CM_ SG_ 261 ExLiLpReBrkLiFltChks "Checksum";
CM_ SG_ 261 ExLiLpReBrkLiFltCntr "Counter";
CM_ SG_ 261 ExLiLpReBrkLiFltReBrkLiLeFlt "Fault on rear brake light Left";
CM_ SG_ 261 ExLiLpReBrkLiFltReBrkLiReFlt "Fault on rear brake light right";
CM_ SG_ 261 ExLiLpReFogLiFltLe "Left Side Fault";
CM_ SG_ 261 ExLiLpReFogLiFltRi "Right Side Fault";
CM_ SG_ 261 ExLiLpRevLiFltLe "Left Side Fault";
CM_ SG_ 261 ExLiLpRevLiFltRi "Right Side Fault";
BA_DEF_ BO_ "CANFD_BRS" ENUM "0","1";
BA_DEF_ BO_ "GenMsgCycleTime" INT 0 65536; // [ms]
BA_DEF_ BO_ "GenMsgDelayTime" INT 0 65536; // [ms]
BA_DEF_ BO_ "GenMsgSendType" ENUM "cyclic", "spontaneous", "not-used", "not-used", "not-used", "cyclicAndSpontaneous", "not-used", "cyclicIfActive", "NoMsgSendType"; // [us]
BA_DEF_ BO_ "GenMsgStartDelayTime" INT 0 65536; // [ms]
BA_DEF_ BO_ "VFrameFormat" ENUM "StandardCAN","ExtendedCAN","reserved","J1939PG","reserved","reserved","reserved","reserved","reserved","reserved","reserved","reserved","reserved","reserved","StandardCAN_FD","ExtendedCAN_FD";
BA_DEF_ SG_ "GenSigSendType" ENUM "Cyclic","OnWrite","OnWriteWithRepetition","OnChange","OnChangeWithRepetition","IfActive","IfActiveWithRepetition","NoSigSendType";
BA_DEF_ SG_ "GenSigStartValue" HEX 0 80000000;
BA_DEF_ BO_ "GenMsgILSupport" ENUM "No","Yes";
BA_DEF_ BO_ "NmAsrMessage" ENUM "No","Yes";
BA_DEF_ SG_ "GenSigFuncType" ENUM "NoFunction","n/a","n/a","n/a","n/a","n/a","n/a","n/a","n/a","n/a","n/a","n/a","n/a","n/a","n/a","CHK","CNTR","n/a","n/a","n/a","CNTR_AR_01","CRC_AR_01_BOTH","CRC_AR_01_ALT","CRC_AR_01_LOW","CRC_AR_01_NIBBLE","CNTR_AR_04","CRC_AR_04A","CNTR_AR_05","CRC_AR_05";
BA_DEF_ SG_ "GenSigDataID" STRING;
BA_DEF_DEF_ "CANFD_BRS" "1";
BA_DEF_DEF_ "GenSigStartValue" 0;
BA_DEF_DEF_ "VFrameFormat" "J1939PG";
BA_DEF_DEF_ "GenSigSendType" "NoSigSendType";
BA_DEF_DEF_ "GenMsgCycleTime" 0;
BA_DEF_DEF_ "GenMsgDelayTime" 0;
BA_DEF_DEF_ "GenMsgStartDelayTime" 0;
BA_DEF_DEF_ "GenMsgSendType" "NoMsgSendType";
BA_DEF_DEF_ "GenMsgILSupport" "Yes";
BA_DEF_DEF_ "NmAsrMessage" "No";
BA_DEF_DEF_ "GenSigFuncType" "NoFunction";
BA_DEF_DEF_ "GenSigDataID" "";
// Frame: LpcEtcToLpcLpc1canXcpFr01
BA_ "GenMsgDelayTime" BO_ 1409 5.000;
BA_ "GenMsgSendType" BO_ 1409 1;
BA_ "VFrameFormat" BO_ 1409 14;
// Frame: LpcEtcToLpcLpc1canXcpFr02
BA_ "GenMsgDelayTime" BO_ 1410 5.000;
BA_ "GenMsgSendType" BO_ 1410 1;
BA_ "VFrameFormat" BO_ 1410 14;
// Frame: LpcLpc1CanFr01_100ms
BA_ "GenMsgCycleTime" BO_ 257 100.000;
BA_ "GenMsgSendType" BO_ 257 0;
BA_ "VFrameFormat" BO_ 257 14;
// Frame: LpcLpc1CanFr01_10ms
BA_ "GenMsgCycleTime" BO_ 256 10.000;
BA_ "GenMsgSendType" BO_ 256 0;
BA_ "VFrameFormat" BO_ 256 14;
// Frame: LpcLpc1CanFr01_20ms
BA_ "GenMsgCycleTime" BO_ 260 20.000;
BA_ "GenMsgSendType" BO_ 260 0;
BA_ "VFrameFormat" BO_ 260 14;
// Frame: LpcLpc1CanFr01_500ms
BA_ "GenMsgCycleTime" BO_ 259 500.000;
BA_ "GenMsgSendType" BO_ 259 0;
BA_ "VFrameFormat" BO_ 259 14;
// Frame: LpcLpc1CanFr02_10ms
BA_ "GenMsgCycleTime" BO_ 261 10.000;
BA_ "GenMsgSendType" BO_ 261 0;
BA_ "VFrameFormat" BO_ 261 14;
// Frame: LpcLpc1CanNMFr
BA_ "GenMsgDelayTime" BO_ 1282 20.000;
BA_ "GenMsgSendType" BO_ 1282 1;
BA_ "VFrameFormat" BO_ 1282 14;
// Frame: LpcToLpcEtcLpc1canXcpFr01
BA_ "GenMsgDelayTime" BO_ 1411 5.000;
BA_ "GenMsgSendType" BO_ 1411 1;
BA_ "VFrameFormat" BO_ 1411 14;
// Frame: LpcToLpcEtcLpc1canXcpFr02
BA_ "GenMsgDelayTime" BO_ 1412 5.000;
BA_ "GenMsgSendType" BO_ 1412 1;
BA_ "VFrameFormat" BO_ 1412 14;
// Frame: LpcToLpcEtcLpc1canXcpFr03
BA_ "GenMsgDelayTime" BO_ 1413 5.000;
BA_ "GenMsgSendType" BO_ 1413 1;
BA_ "VFrameFormat" BO_ 1413 14;
// Frame: LpcToLpcEtcLpc1canXcpFr04
BA_ "GenMsgDelayTime" BO_ 1414 5.000;
BA_ "GenMsgSendType" BO_ 1414 1;
BA_ "VFrameFormat" BO_ 1414 14;
// Frame: LpcToLpcEtcLpc1canXcpFr05
BA_ "GenMsgDelayTime" BO_ 1415 5.000;
BA_ "GenMsgSendType" BO_ 1415 1;
BA_ "VFrameFormat" BO_ 1415 14;
// Frame: LpcToLpcEtcLpc1canXcpFr06
BA_ "GenMsgDelayTime" BO_ 1416 5.000;
BA_ "GenMsgSendType" BO_ 1416 1;
BA_ "VFrameFormat" BO_ 1416 14;
// Frame: LpcToLpcEtcLpc1canXcpFr07
BA_ "GenMsgDelayTime" BO_ 1417 5.000;
BA_ "GenMsgSendType" BO_ 1417 1;
BA_ "VFrameFormat" BO_ 1417 14;
// Frame: LpcToLpcEtcLpc1canXcpFr08
BA_ "GenMsgDelayTime" BO_ 1418 5.000;
BA_ "GenMsgSendType" BO_ 1418 1;
BA_ "VFrameFormat" BO_ 1418 14;
// Frame: LpcToLpcEtcLpc1canXcpFr09
BA_ "GenMsgDelayTime" BO_ 1419 5.000;
BA_ "GenMsgSendType" BO_ 1419 1;
BA_ "VFrameFormat" BO_ 1419 14;
// Frame: LpcToLpcEtcLpc1canXcpFr10
BA_ "GenMsgDelayTime" BO_ 1420 5.000;
BA_ "GenMsgSendType" BO_ 1420 1;
BA_ "VFrameFormat" BO_ 1420 14;
// Frame: LpcdpLpcPASFr01
BA_ "GenMsgCycleTime" BO_ 337 10.000;
BA_ "GenMsgSendType" BO_ 337 0;
BA_ "VFrameFormat" BO_ 337 14;
// Frame: LpcdpSharedFr03
BA_ "GenMsgCycleTime" BO_ 339 100.000;
BA_ "GenMsgSendType" BO_ 339 0;
BA_ "VFrameFormat" BO_ 339 14;
BA_ "GenMsgILSupport" BO_ 1282 0;
BA_ "NmAsrMessage" BO_ 1282 1;
BA_ "GenSigSendType" SG_ 256 ADPMWakeUp 0;
BA_ "GenSigSendType" SG_ 256 AUDWakeUp 0;
BA_ "GenSigSendType" SG_ 337 AbsCtrlActv2 0;
BA_ "GenSigSendType" SG_ 337 AccSts2 0;
BA_ "GenSigSendType" SG_ 256 ActvnOfDispIllmnCSD 0;
BA_ "GenSigSendType" SG_ 256 ActvnOfDispIllmnDIM 0;
BA_ "GenSigSendType" SG_ 256 ActvnOfSwtIllmnMSM 0;
BA_ "GenSigSendType" SG_ 256 ActvnOfSwtIllmnRCSM 0;
BA_ "GenSigSendType" SG_ 256 ActvnOfSwtIllmnSWM 0;
BA_ "GenSigSendType" SG_ 256 ActvnOfSwtIllmnSWS 0;
BA_ "GenSigDataID" SG_ 337 AdPrimWhlAgEstimdGroupSafeChks "0x1AF";
BA_ "GenSigFuncType" SG_ 337 AdPrimWhlAgEstimdGroupSafeChks 21;
BA_ "GenSigSendType" SG_ 337 AdPrimWhlAgEstimdGroupSafeChks 0;
BA_ "GenSigFuncType" SG_ 337 AdPrimWhlAgEstimdGroupSafeCntr 20;
BA_ "GenSigSendType" SG_ 337 AdPrimWhlAgEstimdGroupSafeCntr 0;
BA_ "GenSigSendType" SG_ 337 AdPrimWhlAgEstimdGroupSafeQf1 0;
BA_ "GenSigSendType" SG_ 337 AdPrimWhlAgEstimdGroupSafeWhlAg 0;
BA_ "GenSigSendType" SG_ 337 AdPrimWhlAgEstimdGroupSafeWhlAgRate 0;
BA_ "GenSigStartValue" SG_ 337 AdPrimWhlAgEstimdGroupSafeWhlAgRate 14000;
BA_ "GenSigSendType" SG_ 257 AlrmPasRst 0;
BA_ "GenSigSendType" SG_ 257 AlrmRednSts 0;
BA_ "GenSigSendType" SG_ 257 AlrmSnsrStsInclination 0;
BA_ "GenSigSendType" SG_ 257 AlrmSnsrStsInteriorMotion 0;
BA_ "GenSigSendType" SG_ 257 AlrmSnsrStsPerimeter 0;
BA_ "GenSigSendType" SG_ 257 AlrmSnsrStsSirenConnected 0;
BA_ "GenSigSendType" SG_ 257 AlrmSts 0;
BA_ "GenSigSendType" SG_ 257 AlrmTrgSrc 0;
BA_ "GenSigSendType" SG_ 257 AmbIllmnFwdSts2AmbLiIllmn 0;
BA_ "GenSigSendType" SG_ 257 AmbIllmnFwdSts2Chks 0;
BA_ "GenSigSendType" SG_ 257 AmbIllmnFwdSts2Cntr 0;
BA_ "GenSigSendType" SG_ 256 ApduCmdLpcToIntrEthByte0 1;
BA_ "GenSigSendType" SG_ 256 ApduCmdLpcToIntrEthByte1 1;
BA_ "GenSigSendType" SG_ 256 ApduCmdLpcToIntrEthByte2 1;
BA_ "GenSigSendType" SG_ 256 ApduCmdLpcToIntrEthByte3 1;
BA_ "GenSigSendType" SG_ 256 ApduCmdLpcToIntrEthByte4 1;
BA_ "GenSigSendType" SG_ 256 ApduCmdLpcToIntrEthByte5 1;
BA_ "GenSigSendType" SG_ 256 ApduCmdLpcToIntrEthByte6 1;
BA_ "GenSigSendType" SG_ 256 ApduCmdLpcToIntrEthByte7 1;
BA_ "GenSigSendType" SG_ 256 AutoIllumReq1RCSMDelayTime 0;
BA_ "GenSigSendType" SG_ 256 AutoIllumReq1RCSMPWM1 0;
BA_ "GenSigSendType" SG_ 256 AutoIllumReq1RCSMPWM2 0;
BA_ "GenSigSendType" SG_ 256 AutoIllumReq1RCSMPWM3 0;
BA_ "GenSigSendType" SG_ 256 AutoIllumReq1RCSMReserve1 0;
BA_ "GenSigSendType" SG_ 256 AutoIllumReq1RCSMReserve2 0;
BA_ "GenSigSendType" SG_ 256 AutoIllumReq1RCSMTranBehavior 0;
BA_ "GenSigSendType" SG_ 256 AutoIllumReq1RCSMTranStep 0;
BA_ "GenSigSendType" SG_ 256 AutoIllumReqCSDDelayTime 0;
BA_ "GenSigSendType" SG_ 256 AutoIllumReqCSDPWM 0;
BA_ "GenSigSendType" SG_ 256 AutoIllumReqCSDReserve1 0;
BA_ "GenSigSendType" SG_ 256 AutoIllumReqCSDReserve2 0;
BA_ "GenSigSendType" SG_ 256 AutoIllumReqCSDTranBehavior 0;
BA_ "GenSigSendType" SG_ 256 AutoIllumReqCSDTranStep 0;
BA_ "GenSigSendType" SG_ 256 AutoIllumReqDIMDelayTime 0;
BA_ "GenSigSendType" SG_ 256 AutoIllumReqDIMPWM 0;
BA_ "GenSigSendType" SG_ 256 AutoIllumReqDIMReserve1 0;
BA_ "GenSigSendType" SG_ 256 AutoIllumReqDIMReserve2 0;
BA_ "GenSigSendType" SG_ 256 AutoIllumReqDIMTranBehavior 0;
BA_ "GenSigSendType" SG_ 256 AutoIllumReqDIMTranStep 0;
BA_ "GenSigSendType" SG_ 256 AutoIllumReqMSMDelayTime 0;
BA_ "GenSigSendType" SG_ 256 AutoIllumReqMSMPWM 0;
BA_ "GenSigSendType" SG_ 256 AutoIllumReqMSMReserve1 0;
BA_ "GenSigSendType" SG_ 256 AutoIllumReqMSMReserve2 0;
BA_ "GenSigSendType" SG_ 256 AutoIllumReqMSMTranBehavior 0;
BA_ "GenSigSendType" SG_ 256 AutoIllumReqMSMTranStep 0;
BA_ "GenSigSendType" SG_ 256 AutoIllumReqSWMDelayTime 0;
BA_ "GenSigSendType" SG_ 256 AutoIllumReqSWMPWM 0;
BA_ "GenSigSendType" SG_ 256 AutoIllumReqSWMReserve1 0;
BA_ "GenSigSendType" SG_ 256 AutoIllumReqSWMReserve2 0;
BA_ "GenSigSendType" SG_ 256 AutoIllumReqSWMTranBehavior 0;
BA_ "GenSigSendType" SG_ 256 AutoIllumReqSWMTranStep 0;
BA_ "GenSigSendType" SG_ 256 AutoIllumReqSWSDelayTime 0;
BA_ "GenSigSendType" SG_ 256 AutoIllumReqSWSPWM 0;
BA_ "GenSigSendType" SG_ 256 AutoIllumReqSWSReserve1 0;
BA_ "GenSigSendType" SG_ 256 AutoIllumReqSWSReserve2 0;
BA_ "GenSigSendType" SG_ 256 AutoIllumReqSWSTranBehavior 0;
BA_ "GenSigSendType" SG_ 256 AutoIllumReqSWSTranStep 0;
BA_ "GenSigSendType" SG_ 339 CarTiGlb 0;
BA_ "GenSigSendType" SG_ 257 CenLockStsLockSrc 0;
BA_ "GenSigSendType" SG_ 257 CenLockStsLockSts 0;
BA_ "GenSigSendType" SG_ 257 CenLockStsUpdEve 0;
BA_ "GenSigSendType" SG_ 257 ChdLockStsDoorDrvrRe 0;
BA_ "GenSigSendType" SG_ 257 ChdLockStsDoorPass 0;
BA_ "GenSigSendType" SG_ 257 ChdLockStsDoorPassRe 0;
BA_ "GenSigSendType" SG_ 257 ChdWinProtnStsAtDrvrRe 0;
BA_ "GenSigSendType" SG_ 257 ChdWinProtnStsAtPass 0;
BA_ "GenSigSendType" SG_ 257 ChdWinProtnStsAtPassRe 0;
BA_ "GenSigSendType" SG_ 256 ClimateActuatorsRelay 0;
BA_ "GenSigStartValue" SG_ 256 ClimateActuatorsRelay 1;
BA_ "GenSigSendType" SG_ 256 DIMWakeUp 0;
BA_ "GenSigSendType" SG_ 260 DayNitStsChks 0;
BA_ "GenSigSendType" SG_ 260 DayNitStsCntr 0;
BA_ "GenSigSendType" SG_ 260 DayNitStsValue 0;
BA_ "GenSigSendType" SG_ 261 DetnOfMovmtInCbnReLeRecIfDetnSts 0;
BA_ "GenSigSendType" SG_ 261 DetnOfMovmtInCbnReLeRecIfIntrDetnAvlSts 0;
BA_ "GenSigSendType" SG_ 261 DetnOfMovmtInCbnReLeRecIfIntrDetnOf 0;
BA_ "GenSigSendType" SG_ 261 DetnOfMovmtInCbnReRiRecIfDetnSts 0;
BA_ "GenSigSendType" SG_ 261 DetnOfMovmtInCbnReRiRecIfIntrDetnAvlSts 0;
BA_ "GenSigSendType" SG_ 261 DetnOfMovmtInCbnReRiRecIfIntrDetnOf 0;
BA_ "GenSigSendType" SG_ 261 DetnOfMovmtInCbnThrdLeRecIfDetnSts 0;
BA_ "GenSigSendType" SG_ 261 DetnOfMovmtInCbnThrdLeRecIfIntrDetnAvlSts 0;
BA_ "GenSigSendType" SG_ 261 DetnOfMovmtInCbnThrdLeRecIfIntrDetnOf 0;
BA_ "GenSigSendType" SG_ 261 DetnOfMovmtInCbnThrdRiRecIfDetnSts 0;
BA_ "GenSigSendType" SG_ 261 DetnOfMovmtInCbnThrdRiRecIfIntrDetnAvlSts 0;
BA_ "GenSigSendType" SG_ 261 DetnOfMovmtInCbnThrdRiRecIfIntrDetnOf 0;
BA_ "GenSigSendType" SG_ 261 DetnOfMovmtInCbnTrMovmtRecIfDetnSts 0;
BA_ "GenSigSendType" SG_ 261 DetnOfMovmtInCbnTrMovmtRecIfIntrDetnAvlSts 0;
BA_ "GenSigSendType" SG_ 261 DetnOfMovmtInCbnTrMovmtRecIfIntrDetnOf 0;
BA_ "GenSigSendType" SG_ 261 DetnOfPresInSeatReLeRecIfDetnSts 0;
BA_ "GenSigSendType" SG_ 261 DetnOfPresInSeatReLeRecIfIntrDetnAvlSts 0;
BA_ "GenSigSendType" SG_ 261 DetnOfPresInSeatReLeRecIfIntrDetnOf 0;
BA_ "GenSigSendType" SG_ 261 DetnOfPresInSeatReMidRecIfDetnSts 0;
BA_ "GenSigSendType" SG_ 261 DetnOfPresInSeatReMidRecIfIntrDetnAvlSts 0;
BA_ "GenSigSendType" SG_ 261 DetnOfPresInSeatReMidRecIfIntrDetnOf 0;
BA_ "GenSigSendType" SG_ 261 DetnOfPresInSeatReRiRecIfDetnSts 0;
BA_ "GenSigSendType" SG_ 261 DetnOfPresInSeatReRiRecIfIntrDetnAvlSts 0;
BA_ "GenSigSendType" SG_ 261 DetnOfPresInSeatReRiRecIfIntrDetnOf 0;
BA_ "GenSigSendType" SG_ 261 DetnOfPresInSeatThrdLeRecIfDetnSts 0;
BA_ "GenSigSendType" SG_ 261 DetnOfPresInSeatThrdLeRecIfIntrDetnAvlSts 0;
BA_ "GenSigSendType" SG_ 261 DetnOfPresInSeatThrdLeRecIfIntrDetnOf 0;
BA_ "GenSigSendType" SG_ 261 DetnOfPresInSeatThrdRiRecIfDetnSts 0;
BA_ "GenSigSendType" SG_ 261 DetnOfPresInSeatThrdRiRecIfIntrDetnAvlSts 0;
BA_ "GenSigSendType" SG_ 261 DetnOfPresInSeatThrdRiRecIfIntrDetnOf 0;
BA_ "GenSigSendType" SG_ 261 DetnOfPresReLeRecIfDetnSts 0;
BA_ "GenSigSendType" SG_ 261 DetnOfPresReLeRecIfIntrDetnAvlSts 0;
BA_ "GenSigSendType" SG_ 261 DetnOfPresReLeRecIfIntrDetnOf 0;
BA_ "GenSigSendType" SG_ 261 DetnOfPresReMidRecIfDetnSts 0;
BA_ "GenSigSendType" SG_ 261 DetnOfPresReMidRecIfIntrDetnAvlSts 0;
BA_ "GenSigSendType" SG_ 261 DetnOfPresReMidRecIfIntrDetnOf 0;
BA_ "GenSigSendType" SG_ 261 DetnOfPresReRiRecIfDetnSts 0;
BA_ "GenSigSendType" SG_ 261 DetnOfPresReRiRecIfIntrDetnAvlSts 0;
BA_ "GenSigSendType" SG_ 261 DetnOfPresReRiRecIfIntrDetnOf 0;
BA_ "GenSigSendType" SG_ 261 DetnOfPresThrdLeRecIfDetnSts 0;
BA_ "GenSigSendType" SG_ 261 DetnOfPresThrdLeRecIfIntrDetnAvlSts 0;
BA_ "GenSigSendType" SG_ 261 DetnOfPresThrdLeRecIfIntrDetnOf 0;
BA_ "GenSigSendType" SG_ 261 DetnOfPresThrdRiRecIfDetnSts 0;
BA_ "GenSigSendType" SG_ 261 DetnOfPresThrdRiRecIfIntrDetnAvlSts 0;
BA_ "GenSigSendType" SG_ 261 DetnOfPresThrdRiRecIfIntrDetnOf 0;
BA_ "GenSigSendType" SG_ 261 DetnOfTrPresRecIfDetnSts 0;
BA_ "GenSigSendType" SG_ 261 DetnOfTrPresRecIfIntrDetnAvlSts 0;
BA_ "GenSigSendType" SG_ 261 DetnOfTrPresRecIfIntrDetnOf 0;
BA_ "GenSigSendType" SG_ 257 DiagcForLCSP 0;
BA_ "GenSigSendType" SG_ 259 DiagcInfoForSunSnsrIntErr 0;
BA_ "GenSigSendType" SG_ 259 DiagcInfoForSunSnsrLedForSecuFailr 0;
BA_ "GenSigSendType" SG_ 259 DiagcInfoForSunSnsrSnsrForTFailr 0;
BA_ "GenSigSendType" SG_ 259 DiagcInfoForSunSnsrTmrRst 0;
BA_ "GenSigSendType" SG_ 259 DiagcInfoForSunSnsrUHi 0;
BA_ "GenSigSendType" SG_ 259 DiagcInfoForSunSnsrULo 0;
BA_ "GenSigSendType" SG_ 257 DoorDrvrSts 0;
BA_ "GenSigSendType" SG_ 257 DoorDrvrStsRe 0;
BA_ "GenSigDataID" SG_ 260 DoorDrvrStsSafeChks "0xB18";
BA_ "GenSigFuncType" SG_ 260 DoorDrvrStsSafeChks 21;
BA_ "GenSigSendType" SG_ 260 DoorDrvrStsSafeChks 0;
BA_ "GenSigFuncType" SG_ 260 DoorDrvrStsSafeCntr 20;
BA_ "GenSigSendType" SG_ 260 DoorDrvrStsSafeCntr 0;
BA_ "GenSigSendType" SG_ 260 DoorDrvrStsSafeDoorSts 0;
BA_ "GenSigSendType" SG_ 257 DoorPassSts 0;
BA_ "GenSigSendType" SG_ 257 DoorPassStsRe 0;
BA_ "GenSigSendType" SG_ 256 DrvrDetnOfMovmtInCbnRecIfDetnSts 0;
BA_ "GenSigSendType" SG_ 256 DrvrDetnOfMovmtInCbnRecIfIntrDetnAvlSts 0;
BA_ "GenSigSendType" SG_ 256 DrvrDetnOfMovmtInCbnRecIfIntrDetnOf 0;
BA_ "GenSigSendType" SG_ 256 DrvrDetnOfPresInSeatRecIfDetnSts 0;
BA_ "GenSigSendType" SG_ 256 DrvrDetnOfPresInSeatRecIfIntrDetnAvlSts 0;
BA_ "GenSigSendType" SG_ 256 DrvrDetnOfPresInSeatRecIfIntrDetnOf 0;
BA_ "GenSigSendType" SG_ 256 DrvrDetnOfPresRecIfDetnSts 0;
BA_ "GenSigSendType" SG_ 256 DrvrDetnOfPresRecIfIntrDetnAvlSts 0;
BA_ "GenSigSendType" SG_ 256 DrvrDetnOfPresRecIfIntrDetnOf 0;
BA_ "GenSigSendType" SG_ 257 DrvrGearShiftDirReqAuxChks 0;
BA_ "GenSigSendType" SG_ 257 DrvrGearShiftDirReqAuxCntr 0;
BA_ "GenSigSendType" SG_ 257 DrvrGearShiftDirReqAuxDrvrGearShiftDirReqAukSts 0;
BA_ "GenSigSendType" SG_ 257 DrvrGearShiftDirReqAuxPosn 0;
BA_ "GenSigSendType" SG_ 339 DstTrvld 0;
BA_ "GenSigSendType" SG_ 337 EpbSts2EpbSts 0;
BA_ "GenSigDataID" SG_ 337 EpbSts2EpbStsChks "0x87E";
BA_ "GenSigFuncType" SG_ 337 EpbSts2EpbStsChks 21;
BA_ "GenSigSendType" SG_ 337 EpbSts2EpbStsChks 0;
BA_ "GenSigFuncType" SG_ 337 EpbSts2EpbStsCntr 20;
BA_ "GenSigSendType" SG_ 337 EpbSts2EpbStsCntr 0;
BA_ "GenSigSendType" SG_ 260 ExLiHWLRequest 0;
BA_ "GenSigSendType" SG_ 257 ExLiHcFltHdlampBeamHiLe 0;
BA_ "GenSigSendType" SG_ 257 ExLiHcFltHdlampBeamHiRi 0;
BA_ "GenSigSendType" SG_ 257 ExLiHcFltHdlampBeamLoLe 0;
BA_ "GenSigSendType" SG_ 257 ExLiHcFltHdlampBeamLoRi 0;
BA_ "GenSigSendType" SG_ 257 ExLiHcFltHdlampDaytiRunngLe 0;
BA_ "GenSigSendType" SG_ 257 ExLiHcFltHdlampDaytiRunngRi 0;
BA_ "GenSigSendType" SG_ 260 ExLiHcFltHdlampHozlLe 0;
BA_ "GenSigSendType" SG_ 260 ExLiHcFltHdlampHozlRi 0;
BA_ "GenSigDataID" SG_ 260 ExLiHcFltHdlampIndcrTurnLeChks "0x7A4";
BA_ "GenSigFuncType" SG_ 260 ExLiHcFltHdlampIndcrTurnLeChks 21;
BA_ "GenSigSendType" SG_ 260 ExLiHcFltHdlampIndcrTurnLeChks 0;
BA_ "GenSigFuncType" SG_ 260 ExLiHcFltHdlampIndcrTurnLeCntr 20;
BA_ "GenSigSendType" SG_ 260 ExLiHcFltHdlampIndcrTurnLeCntr 0;
BA_ "GenSigSendType" SG_ 260 ExLiHcFltHdlampIndcrTurnLeSts 0;
BA_ "GenSigDataID" SG_ 260 ExLiHcFltHdlampIndcrTurnRiChks "0x7A5";
BA_ "GenSigFuncType" SG_ 260 ExLiHcFltHdlampIndcrTurnRiChks 21;
BA_ "GenSigSendType" SG_ 260 ExLiHcFltHdlampIndcrTurnRiChks 0;
BA_ "GenSigFuncType" SG_ 260 ExLiHcFltHdlampIndcrTurnRiCntr 20;
BA_ "GenSigSendType" SG_ 260 ExLiHcFltHdlampIndcrTurnRiCntr 0;
BA_ "GenSigSendType" SG_ 260 ExLiHcFltHdlampIndcrTurnRiSts 0;
BA_ "GenSigSendType" SG_ 260 ExLiHcFltHdlampLvlLe 0;
BA_ "GenSigSendType" SG_ 260 ExLiHcFltHdlampLvlRi 0;
BA_ "GenSigSendType" SG_ 257 ExLiHcFltHdlampPosLe 0;
BA_ "GenSigSendType" SG_ 257 ExLiHcFltHdlampPosRi 0;
BA_ "GenSigSendType" SG_ 257 ExLiHcFltHdlampSmlLe 0;
BA_ "GenSigSendType" SG_ 257 ExLiHcFltHdlampSmlRi 0;
BA_ "GenSigSendType" SG_ 260 ExLiHcHdlampConcealFltLe 0;
BA_ "GenSigSendType" SG_ 260 ExLiHcHdlampConcealFltRi 0;
BA_ "GenSigSendType" SG_ 260 ExLiHcHdlampConcealStsLePosnSts 0;
BA_ "GenSigSendType" SG_ 260 ExLiHcHdlampConcealStsLeRefSts 0;
BA_ "GenSigSendType" SG_ 260 ExLiHcHdlampConcealStsRiPosnSts 0;
BA_ "GenSigSendType" SG_ 260 ExLiHcHdlampConcealStsRiRefSts 0;
BA_ "GenSigSendType" SG_ 260 ExLiHcHozlRefStsLe 0;
BA_ "GenSigSendType" SG_ 260 ExLiHcHozlRefStsRi 0;
BA_ "GenSigSendType" SG_ 260 ExLiHcLvlRefStsLe 0;
BA_ "GenSigSendType" SG_ 260 ExLiHcLvlRefStsRi 0;
BA_ "GenSigSendType" SG_ 260 ExLiHdCalibrationDtcLe 0;
BA_ "GenSigSendType" SG_ 260 ExLiHdCalibrationDtcRi 0;
BA_ "GenSigSendType" SG_ 257 ExLiHdFltBeamHiLe 0;
BA_ "GenSigSendType" SG_ 257 ExLiHdFltBeamHiRi 0;
BA_ "GenSigSendType" SG_ 257 ExLiHdFltBeamLoLe 0;
BA_ "GenSigSendType" SG_ 257 ExLiHdFltBeamLoRi 0;
BA_ "GenSigSendType" SG_ 260 ExLiLpFltRearPosLiLe 0;
BA_ "GenSigSendType" SG_ 260 ExLiLpFltRearPosLiRi 0;
BA_ "GenSigSendType" SG_ 260 ExLiLpFltRegPlate 0;
BA_ "GenSigSendType" SG_ 261 ExLiLpReBrkLiFltChks 0;
BA_ "GenSigSendType" SG_ 261 ExLiLpReBrkLiFltCntr 0;
BA_ "GenSigSendType" SG_ 261 ExLiLpReBrkLiFltReBrkLiLeFlt 0;
BA_ "GenSigSendType" SG_ 261 ExLiLpReBrkLiFltReBrkLiReFlt 0;
BA_ "GenSigSendType" SG_ 261 ExLiLpReFogLiFltLe 0;
BA_ "GenSigSendType" SG_ 261 ExLiLpReFogLiFltRi 0;
BA_ "GenSigSendType" SG_ 261 ExLiLpRevLiFltLe 0;
BA_ "GenSigSendType" SG_ 261 ExLiLpRevLiFltRi 0;
BA_ "GenSigSendType" SG_ 256 ExteriorLightRelay 0;
BA_ "GenSigSendType" SG_ 257 FltBrkLiIndcn 0;
BA_ "GenSigDataID" SG_ 337 FrntLeWhlSpdSnsrDataChks "0x832";
BA_ "GenSigFuncType" SG_ 337 FrntLeWhlSpdSnsrDataChks 21;
BA_ "GenSigSendType" SG_ 337 FrntLeWhlSpdSnsrDataChks 0;
BA_ "GenSigFuncType" SG_ 337 FrntLeWhlSpdSnsrDataCntr 20;
BA_ "GenSigSendType" SG_ 337 FrntLeWhlSpdSnsrDataCntr 0;
BA_ "GenSigSendType" SG_ 337 FrntLeWhlSpdSnsrDataWhlAgSpdFrntLe 0;
BA_ "GenSigSendType" SG_ 337 FrntLeWhlSpdSnsrDataWhlAgSpdFrntLeQf 0;
BA_ "GenSigSendType" SG_ 337 FrntLeWhlSpdSnsrDataWhlRotDirFrntLe 0;
BA_ "GenSigSendType" SG_ 337 FrntLeWhlSpdSnsrDataWhlRotDirFrntLeQf 0;
BA_ "GenSigSendType" SG_ 337 FrntLeWhlSpdSnsrDataWhlRotToothCntrFrntLe 0;
BA_ "GenSigSendType" SG_ 337 FrntLeWhlSpdSnsrDataWhlRotToothCntrFrntLeQf 0;
BA_ "GenSigDataID" SG_ 337 FrntRiWhlSpdSnsrDataChks "0x833";
BA_ "GenSigFuncType" SG_ 337 FrntRiWhlSpdSnsrDataChks 21;
BA_ "GenSigSendType" SG_ 337 FrntRiWhlSpdSnsrDataChks 0;
BA_ "GenSigFuncType" SG_ 337 FrntRiWhlSpdSnsrDataCntr 20;
BA_ "GenSigSendType" SG_ 337 FrntRiWhlSpdSnsrDataCntr 0;
BA_ "GenSigSendType" SG_ 337 FrntRiWhlSpdSnsrDataWhlAgSpdFrntRi 0;
BA_ "GenSigSendType" SG_ 337 FrntRiWhlSpdSnsrDataWhlAgSpdFrntRiQf 0;
BA_ "GenSigSendType" SG_ 337 FrntRiWhlSpdSnsrDataWhlRotDirFrntRi 0;
BA_ "GenSigSendType" SG_ 337 FrntRiWhlSpdSnsrDataWhlRotDirFrntRiQf 0;
BA_ "GenSigSendType" SG_ 337 FrntRiWhlSpdSnsrDataWhlRotToothCntrFrntRi 0;
BA_ "GenSigSendType" SG_ 337 FrntRiWhlSpdSnsrDataWhlRotToothCntrFrntRiQf 0;
BA_ "GenSigSendType" SG_ 260 FrontWiperStatus 0;
BA_ "GenSigSendType" SG_ 257 FwdLookCamHeatingSts 0;
BA_ "GenSigSendType" SG_ 257 GlvBoxSts 0;
BA_ "GenSigSendType" SG_ 257 HoodSts 0;
BA_ "GenSigSendType" SG_ 337 IMURawDataIMULatAccRaw 0;
BA_ "GenSigStartValue" SG_ 337 IMURawDataIMULatAccRaw 32768;
BA_ "GenSigSendType" SG_ 337 IMURawDataIMULatAccRawQf 0;
BA_ "GenSigStartValue" SG_ 337 IMURawDataIMULatAccRawQf 1;
BA_ "GenSigSendType" SG_ 337 IMURawDataIMULongAccRaw 0;
BA_ "GenSigStartValue" SG_ 337 IMURawDataIMULongAccRaw 32768;
BA_ "GenSigSendType" SG_ 337 IMURawDataIMULongAccRawQf 0;
BA_ "GenSigStartValue" SG_ 337 IMURawDataIMULongAccRawQf 1;
BA_ "GenSigSendType" SG_ 337 IMURawDataIMUPitchRateRaw 0;
BA_ "GenSigStartValue" SG_ 337 IMURawDataIMUPitchRateRaw 32768;
BA_ "GenSigSendType" SG_ 337 IMURawDataIMUPitchRateRawQf 0;
BA_ "GenSigStartValue" SG_ 337 IMURawDataIMUPitchRateRawQf 1;
BA_ "GenSigSendType" SG_ 337 IMURawDataIMURollRateRaw 0;
BA_ "GenSigStartValue" SG_ 337 IMURawDataIMURollRateRaw 32768;
BA_ "GenSigSendType" SG_ 337 IMURawDataIMURollRateRawQf 0;
BA_ "GenSigStartValue" SG_ 337 IMURawDataIMURollRateRawQf 1;
BA_ "GenSigSendType" SG_ 337 IMURawDataIMUVertAccRaw 0;
BA_ "GenSigStartValue" SG_ 337 IMURawDataIMUVertAccRaw 32768;
BA_ "GenSigSendType" SG_ 337 IMURawDataIMUVertAccRawQf 0;
BA_ "GenSigStartValue" SG_ 337 IMURawDataIMUVertAccRawQf 1;
BA_ "GenSigSendType" SG_ 337 IMURawDataIMUYawRateRaw 0;
BA_ "GenSigStartValue" SG_ 337 IMURawDataIMUYawRateRaw 32768;
BA_ "GenSigSendType" SG_ 337 IMURawDataIMUYawRateRawQf 0;
BA_ "GenSigStartValue" SG_ 337 IMURawDataIMUYawRateRawQf 1;
BA_ "GenSigDataID" SG_ 337 IMURawDataIndicationChks "0x882";
BA_ "GenSigFuncType" SG_ 337 IMURawDataIndicationChks 21;
BA_ "GenSigSendType" SG_ 337 IMURawDataIndicationChks 0;
BA_ "GenSigFuncType" SG_ 337 IMURawDataIndicationCntr 20;
BA_ "GenSigSendType" SG_ 337 IMURawDataIndicationCntr 0;
BA_ "GenSigSendType" SG_ 256 IgnitionPowerRelay 0;
BA_ "GenSigSendType" SG_ 260 IntrLiMgrSts 0;
BA_ "GenSigSendType" SG_ 257 LcmaLedStsDrvrSide 0;
BA_ "GenSigSendType" SG_ 257 LcmaLedStsPassSide 0;
BA_ "GenSigSendType" SG_ 257 LiOperMod 0;
BA_ "GenSigSendType" SG_ 257 LockgCenStsForUsrFb 0;
BA_ "GenSigSendType" SG_ 257 LockgPrvtSts 0;
BA_ "GenSigSendType" SG_ 261 LpcReqNfcRespIntrEth 0;
BA_ "GenSigSendType" SG_ 257 MirrFoldStsAtDrvr 0;
BA_ "GenSigSendType" SG_ 257 MirrFoldStsAtPass 0;
BA_ "GenSigSendType" SG_ 257 MirrPosnSensFdbValDrvrMirrSensXPos 0;
BA_ "GenSigSendType" SG_ 257 MirrPosnSensFdbValDrvrMirrSensYPos 0;
BA_ "GenSigSendType" SG_ 257 MirrPosnSensFdbValPassMirrSensXPos 0;
BA_ "GenSigSendType" SG_ 257 MirrPosnSensFdbValPassMirrSensYPos 0;
BA_ "GenSigSendType" SG_ 257 MirrorDefrosterStatus 0;
BA_ "GenSigSendType" SG_ 337 NFSStMacStsNFSActvSt 0;
BA_ "GenSigSendType" SG_ 337 NFSStMacStsNFSIntrfInfoTyp 0;
BA_ "GenSigSendType" SG_ 256 NfcCardAuthPrnstPakNfcDeviceIDInt 0;
BA_ "GenSigStartValue" SG_ 256 NfcCardAuthPrnstPakNfcDeviceIDInt 255;
BA_ "GenSigSendType" SG_ 256 NfcCardAuthPrnstSubZoneLocation 0;
BA_ "GenSigStartValue" SG_ 256 NfcCardAuthPrnstSubZoneLocation 15;
BA_ "GenSigSendType" SG_ 260 OhcDefrstReq 0;
BA_ "GenSigSendType" SG_ 339 OutdTAmbTVal 0;
BA_ "GenSigStartValue" SG_ 339 OutdTAmbTVal 700;
BA_ "GenSigSendType" SG_ 339 OutdTQly 0;
BA_ "GenSigSendType" SG_ 337 PAPAvl 0;
BA_ "GenSigSendType" SG_ 337 PAPDrvrActvn 0;
BA_ "GenSigSendType" SG_ 337 PAPManvStrtReq 0;
BA_ "GenSigSendType" SG_ 257 PassAirbLmpSts 0;
BA_ "GenSigSendType" SG_ 256 PassDetnOfMovmtInCbnRecIfDetnSts 0;
BA_ "GenSigSendType" SG_ 256 PassDetnOfMovmtInCbnRecIfIntrDetnAvlSts 0;
BA_ "GenSigSendType" SG_ 256 PassDetnOfMovmtInCbnRecIfIntrDetnOf 0;
BA_ "GenSigSendType" SG_ 256 PassDetnOfPresInSeatRecIfDetnSts 0;
BA_ "GenSigSendType" SG_ 256 PassDetnOfPresInSeatRecIfIntrDetnAvlSts 0;
BA_ "GenSigSendType" SG_ 256 PassDetnOfPresInSeatRecIfIntrDetnOf 0;
BA_ "GenSigSendType" SG_ 256 PassDetnOfPresRecIfDetnSts 0;
BA_ "GenSigSendType" SG_ 256 PassDetnOfPresRecIfIntrDetnAvlSts 0;
BA_ "GenSigSendType" SG_ 256 PassDetnOfPresRecIfIntrDetnOf 0;
BA_ "GenSigSendType" SG_ 337 PrkgAssiAvl 0;
BA_ "GenSigSendType" SG_ 337 PrkgAssiDrvnActvn 0;
BA_ "GenSigStartValue" SG_ 337 PrkgAssiDrvnActvn 1;
BA_ "GenSigSendType" SG_ 260 RainLiCmd 0;
BA_ "GenSigDataID" SG_ 337 ReLeWhlSpdSnsrDataChks "0x834";
BA_ "GenSigFuncType" SG_ 337 ReLeWhlSpdSnsrDataChks 21;
BA_ "GenSigSendType" SG_ 337 ReLeWhlSpdSnsrDataChks 0;
BA_ "GenSigFuncType" SG_ 337 ReLeWhlSpdSnsrDataCntr 20;
BA_ "GenSigSendType" SG_ 337 ReLeWhlSpdSnsrDataCntr 0;
BA_ "GenSigSendType" SG_ 337 ReLeWhlSpdSnsrDataWhlAgSpdReLe 0;
BA_ "GenSigSendType" SG_ 337 ReLeWhlSpdSnsrDataWhlAgSpdReLeQf 0;
BA_ "GenSigSendType" SG_ 337 ReLeWhlSpdSnsrDataWhlRotDirReLe 0;
BA_ "GenSigSendType" SG_ 337 ReLeWhlSpdSnsrDataWhlRotDirReLeQf 0;
BA_ "GenSigSendType" SG_ 337 ReLeWhlSpdSnsrDataWhlRotToothCntrReLe 0;
BA_ "GenSigSendType" SG_ 337 ReLeWhlSpdSnsrDataWhlRotToothCntrReLeQf 0;
BA_ "GenSigDataID" SG_ 337 ReRiWhlSpdSnsrDataChks "0x835";
BA_ "GenSigFuncType" SG_ 337 ReRiWhlSpdSnsrDataChks 21;
BA_ "GenSigSendType" SG_ 337 ReRiWhlSpdSnsrDataChks 0;
BA_ "GenSigFuncType" SG_ 337 ReRiWhlSpdSnsrDataCntr 20;
BA_ "GenSigSendType" SG_ 337 ReRiWhlSpdSnsrDataCntr 0;
BA_ "GenSigSendType" SG_ 337 ReRiWhlSpdSnsrDataWhlAgSpdReRi 0;
BA_ "GenSigSendType" SG_ 337 ReRiWhlSpdSnsrDataWhlAgSpdReRiQf 0;
BA_ "GenSigSendType" SG_ 337 ReRiWhlSpdSnsrDataWhlRotDirReRi 0;
BA_ "GenSigSendType" SG_ 337 ReRiWhlSpdSnsrDataWhlRotDirReRiQf 0;
BA_ "GenSigSendType" SG_ 337 ReRiWhlSpdSnsrDataWhlRotToothCntrReRi 0;
BA_ "GenSigSendType" SG_ 337 ReRiWhlSpdSnsrDataWhlRotToothCntrReRiQf 0;
BA_ "GenSigSendType" SG_ 256 SUMWakeUp 0;
BA_ "GenSigSendType" SG_ 257 SeatRowSecBackRestSwtStsSwtLeSts 0;
BA_ "GenSigSendType" SG_ 257 SeatRowSecBackRestSwtStsSwtRiSts 0;
BA_ "GenSigSendType" SG_ 257 SeatSwtTrStsLeHalfSts 0;
BA_ "GenSigSendType" SG_ 257 SeatSwtTrStsRiHalfSts 0;
BA_ "GenSigSendType" SG_ 257 SftyBltTelltlFlt 0;
BA_ "GenSigSendType" SG_ 337 SteerWhlTq2 0;
BA_ "GenSigSendType" SG_ 259 SunSnsrDshbT 0;
BA_ "GenSigStartValue" SG_ 259 SunSnsrDshbT 40;
BA_ "GenSigSendType" SG_ 259 SunSnsrQf 0;
BA_ "GenSigSendType" SG_ 259 SunSnsrSunLoad 0;
BA_ "GenSigSendType" SG_ 337 TireRdEstimd 0;
BA_ "GenSigSendType" SG_ 257 TrSts 0;
BA_ "GenSigSendType" SG_ 257 TrlrLampChk 1;
BA_ "GenSigSendType" SG_ 257 TrlrLampChkSts 1;
BA_ "GenSigSendType" SG_ 257 TrlrLiSts 1;
BA_ "GenSigSendType" SG_ 256 TrlrPrsnt1 0;
BA_ "GenSigSendType" SG_ 257 TrlrSrvReqToHMI 1;
BA_ "GenSigSendType" SG_ 337 TrsmParkLockdSafe2TrsmParkLockd 0;
BA_ "GenSigStartValue" SG_ 337 TrsmParkLockdSafe2TrsmParkLockd 3;
BA_ "GenSigDataID" SG_ 337 TrsmParkLockdSafe2TrsmParkLockdChks "0x87F";
BA_ "GenSigFuncType" SG_ 337 TrsmParkLockdSafe2TrsmParkLockdChks 21;
BA_ "GenSigSendType" SG_ 337 TrsmParkLockdSafe2TrsmParkLockdChks 0;
BA_ "GenSigFuncType" SG_ 337 TrsmParkLockdSafe2TrsmParkLockdCntr 20;
BA_ "GenSigSendType" SG_ 337 TrsmParkLockdSafe2TrsmParkLockdCntr 0;
BA_ "GenSigDataID" SG_ 257 TurnIndcrFaultChks "0x9CD";
BA_ "GenSigFuncType" SG_ 257 TurnIndcrFaultChks 21;
BA_ "GenSigSendType" SG_ 257 TurnIndcrFaultChks 0;
BA_ "GenSigFuncType" SG_ 257 TurnIndcrFaultCntr 20;
BA_ "GenSigSendType" SG_ 257 TurnIndcrFaultCntr 0;
BA_ "GenSigSendType" SG_ 257 TurnIndcrFaultRearLe 0;
BA_ "GenSigSendType" SG_ 257 TurnIndcrFaultRearRi 0;
BA_ "GenSigSendType" SG_ 257 TurnIndcrFaultSideLe 0;
BA_ "GenSigSendType" SG_ 257 TurnIndcrFaultSideRi 0;
BA_ "GenSigSendType" SG_ 257 TwbrStsTwbrSts 1;
BA_ "GenSigSendType" SG_ 257 TwbrStsTwbrTyp 1;
BA_ "GenSigStartValue" SG_ 257 TwbrStsTwbrTyp 3;
BA_ "GenSigSendType" SG_ 256 UsageAuthDrvrAuthMgrAuthLvl 0;
BA_ "GenSigSendType" SG_ 256 UsageAuthDrvrAuthMgrMAC1 0;
BA_ "GenSigSendType" SG_ 256 UsageAuthDrvrAuthMgrMAC2 0;
BA_ "GenSigSendType" SG_ 256 UsageAuthDrvrAuthMgrStrtTi 0;
BA_ "GenSigSendType" SG_ 256 UsageAuthDrvrAuthMgrUniqID 0;
BA_ "GenSigSendType" SG_ 256 UsageModeAvailable 0;
BA_ "GenSigSendType" SG_ 256 UsageModeAwake 0;
BA_ "GenSigSendType" SG_ 256 UsageModeResponsive 0;
BA_ "GenSigSendType" SG_ 339 VehBattUSysU 0;
BA_ "GenSigSendType" SG_ 339 VehBattUSysUQf 0;
BA_ "GenSigStartValue" SG_ 339 VehBattUSysUQf 2;
BA_ "GenSigSendType" SG_ 337 VehMtnStSafe3VehMtnSt 0;
BA_ "GenSigDataID" SG_ 337 VehMtnStSafe3VehMtnStChks "0x880";
BA_ "GenSigFuncType" SG_ 337 VehMtnStSafe3VehMtnStChks 21;
BA_ "GenSigSendType" SG_ 337 VehMtnStSafe3VehMtnStChks 0;
BA_ "GenSigFuncType" SG_ 337 VehMtnStSafe3VehMtnStCntr 20;
BA_ "GenSigSendType" SG_ 337 VehMtnStSafe3VehMtnStCntr 0;
BA_ "GenSigSendType" SG_ 339 VehSpdNom 0;
BA_ "GenSigSendType" SG_ 339 VehSpdNomQf 0;
BA_ "GenSigSendType" SG_ 260 Washer 0;
BA_ "GenSigSendType" SG_ 260 WasherRearStatus 0;
BA_ "GenSigSendType" SG_ 257 WinPosnStsAtDrv 0;
BA_ "GenSigSendType" SG_ 257 WinPosnStsAtDrvrRe 0;
BA_ "GenSigSendType" SG_ 257 WinPosnStsAtPass 0;
BA_ "GenSigSendType" SG_ 257 WinPosnStsAtPassRe 0;
BA_ "GenSigSendType" SG_ 260 WiprInPosnForSrv 0;
BA_ "GenSigSendType" SG_ 260 WiprInWipgAr 0;
BA_ "GenSigSendType" SG_ 260 WshrFldSts1WdElmHMI 0;
VAL_ 337 AbsCtrlActv2 0 "CtrlSts1_NoCtrl" 1 "CtrlSts1_InCtrl";
VAL_ 337 AccSts2 0 "AccSts2_Undef" 1 "AccSts2_Off" 2 "AccSts2_Stb" 3 "AccSts2_Stop" 4 "AccSts2_StopTmp" 5 "AccSts2_Actv" 6 "AccSts2_Resd1" 7 "AccSts2_Resd2";
VAL_ 337 AdPrimWhlAgEstimdGroupSafeQf1 0 "Qf1_DevOfDataUndefd" 1 "Qf1_DataTmpUndefdAndEvlnInProgs" 2 "Qf1_DevOfDataNotWithinRngAllwd" 3 "Qf1_DataCalcdWithDevDefd";
VAL_ 337 EpbSts2EpbSts 0 "EpbSts1_Inin" 1 "EpbSts1_Diag" 2 "EpbSts1_Resd2" 3 "EpbSts1_AllAppld" 4 "EpbSts1_Resd4" 5 "EpbSts1_AllInTran" 6 "EpbSts1_BrkgDynByActr" 7 "EpbSts1_Resd7" 8 "EpbSts1_Resd8" 9 "EpbSts1_ActrAllReld" 10 "EpbSts1_BrkgDynDegraded" 11 "EpbSts1_Resd11" 12 "EpbSts1_BrkgDyn" 13 "EpbSts1_Resd13" 14 "EpbSts1_Resd14" 15 "EpbSts1_Err";
VAL_ 337 FrntLeWhlSpdSnsrDataWhlAgSpdFrntLeQf 0 "Qf1_DevOfDataUndefd" 1 "Qf1_DataTmpUndefdAndEvlnInProgs" 2 "Qf1_DevOfDataNotWithinRngAllwd" 3 "Qf1_DataCalcdWithDevDefd";
VAL_ 337 FrntLeWhlSpdSnsrDataWhlRotDirFrntLe 0 "WhlRotlDirStd1_Undefd" 1 "WhlRotlDirStd1_StandStill" 2 "WhlRotlDirStd1_Fwd" 3 "WhlRotlDirStd1_Backw";
VAL_ 337 FrntLeWhlSpdSnsrDataWhlRotDirFrntLeQf 0 "Qf1_DevOfDataUndefd" 1 "Qf1_DataTmpUndefdAndEvlnInProgs" 2 "Qf1_DevOfDataNotWithinRngAllwd" 3 "Qf1_DataCalcdWithDevDefd";
VAL_ 337 FrntLeWhlSpdSnsrDataWhlRotToothCntrFrntLeQf 0 "Qf1_DevOfDataUndefd" 1 "Qf1_DataTmpUndefdAndEvlnInProgs" 2 "Qf1_DevOfDataNotWithinRngAllwd" 3 "Qf1_DataCalcdWithDevDefd";
VAL_ 337 FrntRiWhlSpdSnsrDataWhlAgSpdFrntRiQf 0 "Qf1_DevOfDataUndefd" 1 "Qf1_DataTmpUndefdAndEvlnInProgs" 2 "Qf1_DevOfDataNotWithinRngAllwd" 3 "Qf1_DataCalcdWithDevDefd";
VAL_ 337 FrntRiWhlSpdSnsrDataWhlRotDirFrntRi 0 "WhlRotlDirStd1_Undefd" 1 "WhlRotlDirStd1_StandStill" 2 "WhlRotlDirStd1_Fwd" 3 "WhlRotlDirStd1_Backw";
VAL_ 337 FrntRiWhlSpdSnsrDataWhlRotDirFrntRiQf 0 "Qf1_DevOfDataUndefd" 1 "Qf1_DataTmpUndefdAndEvlnInProgs" 2 "Qf1_DevOfDataNotWithinRngAllwd" 3 "Qf1_DataCalcdWithDevDefd";
VAL_ 337 FrntRiWhlSpdSnsrDataWhlRotToothCntrFrntRiQf 0 "Qf1_DevOfDataUndefd" 1 "Qf1_DataTmpUndefdAndEvlnInProgs" 2 "Qf1_DevOfDataNotWithinRngAllwd" 3 "Qf1_DataCalcdWithDevDefd";
VAL_ 337 IMURawDataIMULatAccRawQf 0 "Qf1_DevOfDataUndefd" 1 "Qf1_DataTmpUndefdAndEvlnInProgs" 2 "Qf1_DevOfDataNotWithinRngAllwd" 3 "Qf1_DataCalcdWithDevDefd";
VAL_ 337 IMURawDataIMULongAccRawQf 0 "Qf1_DevOfDataUndefd" 1 "Qf1_DataTmpUndefdAndEvlnInProgs" 2 "Qf1_DevOfDataNotWithinRngAllwd" 3 "Qf1_DataCalcdWithDevDefd";
VAL_ 337 IMURawDataIMUPitchRateRawQf 0 "Qf1_DevOfDataUndefd" 1 "Qf1_DataTmpUndefdAndEvlnInProgs" 2 "Qf1_DevOfDataNotWithinRngAllwd" 3 "Qf1_DataCalcdWithDevDefd";
VAL_ 337 IMURawDataIMURollRateRawQf 0 "Qf1_DevOfDataUndefd" 1 "Qf1_DataTmpUndefdAndEvlnInProgs" 2 "Qf1_DevOfDataNotWithinRngAllwd" 3 "Qf1_DataCalcdWithDevDefd";
VAL_ 337 IMURawDataIMUVertAccRawQf 0 "Qf1_DevOfDataUndefd" 1 "Qf1_DataTmpUndefdAndEvlnInProgs" 2 "Qf1_DevOfDataNotWithinRngAllwd" 3 "Qf1_DataCalcdWithDevDefd";
VAL_ 337 IMURawDataIMUYawRateRawQf 0 "Qf1_DevOfDataUndefd" 1 "Qf1_DataTmpUndefdAndEvlnInProgs" 2 "Qf1_DevOfDataNotWithinRngAllwd" 3 "Qf1_DataCalcdWithDevDefd";
VAL_ 337 NFSStMacStsNFSActvSt 0 "NFSActvSt_Undefd" 1 "NFSActvSt_Off" 2 "NFSActvSt_Standby" 3 "NFSActvSt_On" 4 "NFSActvSt_Malfunction" 5 "NFSActvSt_AutnmsDrvModOn" 6 "NFSActvSt_Reserved2" 7 "NFSActvSt_Reserved3";
VAL_ 337 NFSStMacStsNFSIntrfInfoTyp 0 "NFSIntrfInfoTyp_Undefd" 1 "NFSIntrfInfoTyp_sdi" 2 "NFSIntrfInfoTyp_ff" 3 "NFSIntrfInfoTyp_Reserved1" 4 "NFSIntrfInfoTyp_Reserved2" 5 "NFSIntrfInfoTyp_Reserved3" 6 "NFSIntrfInfoTyp_Reserved4";
VAL_ 337 PAPAvl 0 "AvlSts_Undefd" 1 "AvlSts_Off" 2 "AvlSts_Stb" 3 "AvlSts_On" 4 "AvlSts_Malfunction" 5 "AvlSts_Resd1" 6 "AvlSts_Resd2" 7 "AvlSts_Resd3";
VAL_ 337 PAPDrvrActvn 0 "OnOff1_Off" 1 "OnOff1_On";
VAL_ 337 PAPManvStrtReq 0 "PAPManvStrtReq_NoReq" 1 "PAPManvStrtReq_Req";
VAL_ 337 PrkgAssiAvl 0 "AvlSts_Undefd" 1 "AvlSts_Off" 2 "AvlSts_Stb" 3 "AvlSts_On" 4 "AvlSts_Malfunction" 5 "AvlSts_Resd1" 6 "AvlSts_Resd2" 7 "AvlSts_Resd3";
VAL_ 337 PrkgAssiDrvnActvn 0 "OnOff1_Off" 1 "OnOff1_On";
VAL_ 337 ReLeWhlSpdSnsrDataWhlAgSpdReLeQf 0 "Qf1_DevOfDataUndefd" 1 "Qf1_DataTmpUndefdAndEvlnInProgs" 2 "Qf1_DevOfDataNotWithinRngAllwd" 3 "Qf1_DataCalcdWithDevDefd";
VAL_ 337 ReLeWhlSpdSnsrDataWhlRotDirReLe 0 "WhlRotlDirStd1_Undefd" 1 "WhlRotlDirStd1_StandStill" 2 "WhlRotlDirStd1_Fwd" 3 "WhlRotlDirStd1_Backw";
VAL_ 337 ReLeWhlSpdSnsrDataWhlRotDirReLeQf 0 "Qf1_DevOfDataUndefd" 1 "Qf1_DataTmpUndefdAndEvlnInProgs" 2 "Qf1_DevOfDataNotWithinRngAllwd" 3 "Qf1_DataCalcdWithDevDefd";
VAL_ 337 ReLeWhlSpdSnsrDataWhlRotToothCntrReLeQf 0 "Qf1_DevOfDataUndefd" 1 "Qf1_DataTmpUndefdAndEvlnInProgs" 2 "Qf1_DevOfDataNotWithinRngAllwd" 3 "Qf1_DataCalcdWithDevDefd";
VAL_ 337 ReRiWhlSpdSnsrDataWhlAgSpdReRiQf 0 "Qf1_DevOfDataUndefd" 1 "Qf1_DataTmpUndefdAndEvlnInProgs" 2 "Qf1_DevOfDataNotWithinRngAllwd" 3 "Qf1_DataCalcdWithDevDefd";
VAL_ 337 ReRiWhlSpdSnsrDataWhlRotDirReRi 0 "WhlRotlDirStd1_Undefd" 1 "WhlRotlDirStd1_StandStill" 2 "WhlRotlDirStd1_Fwd" 3 "WhlRotlDirStd1_Backw";
VAL_ 337 ReRiWhlSpdSnsrDataWhlRotDirReRiQf 0 "Qf1_DevOfDataUndefd" 1 "Qf1_DataTmpUndefdAndEvlnInProgs" 2 "Qf1_DevOfDataNotWithinRngAllwd" 3 "Qf1_DataCalcdWithDevDefd";
VAL_ 337 ReRiWhlSpdSnsrDataWhlRotToothCntrReRiQf 0 "Qf1_DevOfDataUndefd" 1 "Qf1_DataTmpUndefdAndEvlnInProgs" 2 "Qf1_DevOfDataNotWithinRngAllwd" 3 "Qf1_DataCalcdWithDevDefd";
VAL_ 337 TrsmParkLockdSafe2TrsmParkLockd 0 "TrsmParkLock1_ParkNotEngd" 1 "TrsmParkLock1_ParkEngd" 2 "TrsmParkLock1_NotInUse" 3 "TrsmParkLock1_Undefd";
VAL_ 337 VehMtnStSafe3VehMtnSt 0 "VehMtnSt2_Ukwn" 1 "VehMtnSt2_StandStillVal1" 2 "VehMtnSt2_StandStillVal2" 3 "VehMtnSt2_StandStillVal3" 4 "VehMtnSt2_RollgFwdVal1" 5 "VehMtnSt2_RollgFwdVal2" 6 "VehMtnSt2_RollgBackwVal1" 7 "VehMtnSt2_RollgBackwVal2";
VAL_ 339 OutdTQly 0 "GenQf1_UndefindDataAccur" 1 "GenQf1_TmpUndefdData" 2 "GenQf1_DataAccurNotWithinSpcn" 3 "GenQf1_AccurData";
VAL_ 339 VehBattUSysUQf 0 "GenQf1_UndefindDataAccur" 1 "GenQf1_TmpUndefdData" 2 "GenQf1_DataAccurNotWithinSpcn" 3 "GenQf1_AccurData";
VAL_ 339 VehSpdNomQf 0 "GenQf1_UndefindDataAccur" 1 "GenQf1_TmpUndefdData" 2 "GenQf1_DataAccurNotWithinSpcn" 3 "GenQf1_AccurData";
VAL_ 257 AlrmPasRst 0 "NoReqOffReq_NoReq" 1 "NoReqOffReq_OffReq";
VAL_ 257 AlrmRednSts 0 "OnOffSafe1_OnOffSafeInvld1" 1 "OnOffSafe1_OnOffSafeOn" 2 "OnOffSafe1_OnOffSafeOff" 3 "OnOffSafe1_OnOffSafeInvld2";
VAL_ 257 AlrmSnsrStsInclination 0 "OnOffSafe1_OnOffSafeInvld1" 1 "OnOffSafe1_OnOffSafeOn" 2 "OnOffSafe1_OnOffSafeOff" 3 "OnOffSafe1_OnOffSafeInvld2";
VAL_ 257 AlrmSnsrStsInteriorMotion 0 "OnOffSafe1_OnOffSafeInvld1" 1 "OnOffSafe1_OnOffSafeOn" 2 "OnOffSafe1_OnOffSafeOff" 3 "OnOffSafe1_OnOffSafeInvld2";
VAL_ 257 AlrmSnsrStsPerimeter 0 "OnOffSafe1_OnOffSafeInvld1" 1 "OnOffSafe1_OnOffSafeOn" 2 "OnOffSafe1_OnOffSafeOff" 3 "OnOffSafe1_OnOffSafeInvld2";
VAL_ 257 AlrmSnsrStsSirenConnected 0 "OnOffSafe1_OnOffSafeInvld1" 1 "OnOffSafe1_OnOffSafeOn" 2 "OnOffSafe1_OnOffSafeOff" 3 "OnOffSafe1_OnOffSafeInvld2";
VAL_ 257 AlrmSts 0 "AlrmSt_Disarmd" 1 "AlrmSt_Armd" 2 "AlrmSt_Actv";
VAL_ 257 AlrmTrgSrc 0 "AlrmTrgSrc3_NoTrgSrc" 1 "AlrmTrgSrc3_SnsrSoundr" 2 "AlrmTrgSrc3_SnsrIncln" 3 "AlrmTrgSrc3_SnsrIntrScanr" 4 "AlrmTrgSrc3_Hood" 5 "AlrmTrgSrc3_Tr" 6 "AlrmTrgSrc3_DoorDrvr" 7 "AlrmTrgSrc3_DoorPass" 8 "AlrmTrgSrc3_DoorDrvrRe" 9 "AlrmTrgSrc3_DoorPassRe" 10 "AlrmTrgSrc3_LidFuel" 11 "AlrmTrgSrc3_LidChrgn" 12 "AlrmTrgSrc3_ExtActvn";
VAL_ 257 CenLockStsLockSrc 0 "LockgTrigSrc_NoTrigSrc" 1 "LockgTrigSrc_KeyRem" 2 "LockgTrigSrc_Keyls" 3 "LockgTrigSrc_IntrSwt" 4 "LockgTrigSrc_SpdAut" 5 "LockgTrigSrc_TmrAut" 6 "LockgTrigSrc_Slam" 7 "LockgTrigSrc_Telm" 8 "LockgTrigSrc_Crash" 9 "LockgTrigSrc_ExtrlCmd" 10 "LockgTrigSrc_NFC" 11 "LockgTrigSrc_WlkAway" 12 "LockgTrigSrc_InrOpen" 13 "LockgTrigSrc_Apprch" 14 "LockgTrigSrc_Resd1" 15 "LockgTrigSrc_Resd2";
VAL_ 257 CenLockStsLockSts 0 "LockSt3_LockUndefd" 1 "LockSt3_LockUnlckd" 2 "LockSt3_LockTrUnlckd" 3 "LockSt3_LockLockd";
VAL_ 257 CenLockStsUpdEve 0 "Boolean_FALSE" 1 "Boolean_TRUE";
VAL_ 257 ChdLockStsDoorDrvrRe 0 "OnOffFault2_Ukwn" 1 "OnOffFault2_On" 2 "OnOffFault2_Off" 3 "OnOffFault2_Err";
VAL_ 257 ChdLockStsDoorPass 0 "OnOffFault2_Ukwn" 1 "OnOffFault2_On" 2 "OnOffFault2_Off" 3 "OnOffFault2_Err";
VAL_ 257 ChdLockStsDoorPassRe 0 "OnOffFault2_Ukwn" 1 "OnOffFault2_On" 2 "OnOffFault2_Off" 3 "OnOffFault2_Err";
VAL_ 257 ChdWinProtnStsAtDrvrRe 0 "OnOff1_Off" 1 "OnOff1_On";
VAL_ 257 ChdWinProtnStsAtPass 0 "OnOff1_Off" 1 "OnOff1_On";
VAL_ 257 ChdWinProtnStsAtPassRe 0 "OnOff1_Off" 1 "OnOff1_On";
VAL_ 257 DiagcForLCSP 0 "DiagcForLCSPSts_NotFlt" 1 "DiagcForLCSPSts_OutdURng" 2 "DiagcForLCSPSts_TmrErr" 3 "DiagcForLCSPSts_MemErr" 4 "DiagcForLCSPSts_TouchErr" 5 "DiagcForLCSPSts_TBD1" 6 "DiagcForLCSPSts_TBD2" 7 "DiagcForLCSPSts_TBD3";
VAL_ 257 DoorDrvrSts 0 "DoorSts2_Ukwn" 1 "DoorSts2_Opend" 2 "DoorSts2_Clsd";
VAL_ 257 DoorDrvrStsRe 0 "DoorSts2_Ukwn" 1 "DoorSts2_Opend" 2 "DoorSts2_Clsd";
VAL_ 257 DoorPassSts 0 "DoorSts2_Ukwn" 1 "DoorSts2_Opend" 2 "DoorSts2_Clsd";
VAL_ 257 DoorPassStsRe 0 "DoorSts2_Ukwn" 1 "DoorSts2_Opend" 2 "DoorSts2_Clsd";
VAL_ 257 DrvrGearShiftDirReqAuxDrvrGearShiftDirReqAukSts 0 "DrvrGearShiftDirReqAuxSts_Initialization" 1 "DrvrGearShiftDirReqAuxSts_NotASILB" 2 "DrvrGearShiftDirReqAuxSts_Reserved" 3 "DrvrGearShiftDirReqAuxSts_ASILB";
VAL_ 257 DrvrGearShiftDirReqAuxPosn 0 "DrvrGearShiftDirReqAuxPosn_Zero" 1 "DrvrGearShiftDirReqAuxPosn_Up1Step" 2 "DrvrGearShiftDirReqAuxPosn_Up2Step" 3 "DrvrGearShiftDirReqAuxPosn_Dn1Step" 4 "DrvrGearShiftDirReqAuxPosn_Dn2Step";
VAL_ 257 ExLiHcFltHdlampBeamHiLe 0 "DevErrSts2_NoFlt" 1 "DevErrSts2_Flt";
VAL_ 257 ExLiHcFltHdlampBeamHiRi 0 "DevErrSts2_NoFlt" 1 "DevErrSts2_Flt";
VAL_ 257 ExLiHcFltHdlampBeamLoLe 0 "DevErrSts2_NoFlt" 1 "DevErrSts2_Flt";
VAL_ 257 ExLiHcFltHdlampBeamLoRi 0 "DevErrSts2_NoFlt" 1 "DevErrSts2_Flt";
VAL_ 257 ExLiHcFltHdlampDaytiRunngLe 0 "DevErrSts2_NoFlt" 1 "DevErrSts2_Flt";
VAL_ 257 ExLiHcFltHdlampDaytiRunngRi 0 "DevErrSts2_NoFlt" 1 "DevErrSts2_Flt";
VAL_ 257 ExLiHcFltHdlampPosLe 0 "DevErrSts2_NoFlt" 1 "DevErrSts2_Flt";
VAL_ 257 ExLiHcFltHdlampPosRi 0 "DevErrSts2_NoFlt" 1 "DevErrSts2_Flt";
VAL_ 257 ExLiHcFltHdlampSmlLe 0 "DevErrSts2_NoFlt" 1 "DevErrSts2_Flt";
VAL_ 257 ExLiHcFltHdlampSmlRi 0 "DevErrSts2_NoFlt" 1 "DevErrSts2_Flt";
VAL_ 257 ExLiHdFltBeamHiLe 0 "DevErrSts2_NoFlt" 1 "DevErrSts2_Flt";
VAL_ 257 ExLiHdFltBeamHiRi 0 "DevErrSts2_NoFlt" 1 "DevErrSts2_Flt";
VAL_ 257 ExLiHdFltBeamLoLe 0 "DevErrSts2_NoFlt" 1 "DevErrSts2_Flt";
VAL_ 257 ExLiHdFltBeamLoRi 0 "DevErrSts2_NoFlt" 1 "DevErrSts2_Flt";
VAL_ 257 FltBrkLiIndcn 0 "OnOffCrit1_NotVld1" 1 "OnOffCrit1_Off" 2 "OnOffCrit1_On" 3 "OnOffCrit1_NotVld2";
VAL_ 257 FwdLookCamHeatingSts 0 "Boolean_FALSE" 1 "Boolean_TRUE";
VAL_ 257 GlvBoxSts 0 "DoorSts2_Ukwn" 1 "DoorSts2_Opend" 2 "DoorSts2_Clsd";
VAL_ 257 HoodSts 0 "DoorSts2_Ukwn" 1 "DoorSts2_Opend" 2 "DoorSts2_Clsd";
VAL_ 257 LcmaLedStsDrvrSide 0 "OkNotOk1_Ok" 1 "OkNotOk1_NotOk";
VAL_ 257 LcmaLedStsPassSide 0 "OkNotOk1_Ok" 1 "OkNotOk1_NotOk";
VAL_ 257 LiOperMod 0 "LiOperMod_Night" 1 "LiOperMod_Day" 2 "LiOperMod_Twli" 3 "LiOperMod_Tnl";
VAL_ 257 LockgCenStsForUsrFb 0 "LockSt2_Undefd" 1 "LockSt2_Opend" 2 "LockSt2_Clsd" 3 "LockSt2_Lockd" 4 "LockSt2_Safe";
VAL_ 257 LockgPrvtSts 0 "OnOff1_Off" 1 "OnOff1_On";
VAL_ 257 MirrFoldStsAtDrvr 0 "MirrFoldStsTyp_MirrFoldPosnUndefd" 1 "MirrFoldStsTyp_MirrNotFoldPosn" 2 "MirrFoldStsTyp_MirrFoldPosn" 3 "MirrFoldStsTyp_MirrMovgToNotFold" 4 "MirrFoldStsTyp_MirrMovgToFold";
VAL_ 257 MirrFoldStsAtPass 0 "MirrFoldStsTyp_MirrFoldPosnUndefd" 1 "MirrFoldStsTyp_MirrNotFoldPosn" 2 "MirrFoldStsTyp_MirrFoldPosn" 3 "MirrFoldStsTyp_MirrMovgToNotFold" 4 "MirrFoldStsTyp_MirrMovgToFold";
VAL_ 257 MirrorDefrosterStatus 0 "OnOffNoReq_NoReq" 1 "OnOffNoReq_On" 2 "OnOffNoReq_Off";
VAL_ 257 PassAirbLmpSts 0 "PassAirbLmpSts_PadOffPaeOff" 1 "PassAirbLmpSts_PadOffPaeOn" 2 "PassAirbLmpSts_PadOnPaeOff" 3 "PassAirbLmpSts_PadOnPaeOn" 4 "PassAirbLmpSts_Fault" 5 "PassAirbLmpSts_Spare1" 6 "PassAirbLmpSts_Spare2" 7 "PassAirbLmpSts_Spare3";
VAL_ 257 SeatRowSecBackRestSwtStsSwtLeSts 0 "OnOff1_Off" 1 "OnOff1_On";
VAL_ 257 SeatRowSecBackRestSwtStsSwtRiSts 0 "OnOff1_Off" 1 "OnOff1_On";
VAL_ 257 SeatSwtTrStsLeHalfSts 0 "SeatBtnPsd_Init" 1 "SeatBtnPsd_BtnIdle" 2 "SeatBtnPsd_BtnPsd" 3 "SeatBtnPsd_Invalid";
VAL_ 257 SeatSwtTrStsRiHalfSts 0 "SeatBtnPsd_Init" 1 "SeatBtnPsd_BtnIdle" 2 "SeatBtnPsd_BtnPsd" 3 "SeatBtnPsd_Invalid";
VAL_ 257 SftyBltTelltlFlt 0 "DevErrSts2_NoFlt" 1 "DevErrSts2_Flt";
VAL_ 257 TrlrLampChk 0 "TrlrLampChkSts1_TrlrLampChkNotAvl" 1 "TrlrLampChkSts1_TrlrLampChkAvl";
VAL_ 257 TrlrLampChkSts 0 "TrlrLampChkSts2_Idle" 1 "TrlrLampChkSts2_TrlrLampChkStrtd" 2 "TrlrLampChkSts2_TrlrLampChkCmpl" 3 "TrlrLampChkSts2_CnclOper" 4 "TrlrLampChkSts2_TrlrLampEngOffReqd" 5 "TrlrLampChkSts2_Resd1" 6 "TrlrLampChkSts2_Resd2" 7 "TrlrLampChkSts2_Resd3";
VAL_ 257 TrlrLiSts 0 "LampFailrSts1_LampNoFailr" 1 "LampFailrSts1_LampIndcrTurnRiFailr" 2 "LampFailrSts1_LampIndcrTurnLeFailr" 3 "LampFailrSts1_LampIndcrTurnLeAndRiFailr" 4 "LampFailrSts1_BrkLampFailr" 5 "LampFailrSts1_BrkLampAndIndcrTurnRiFailr" 6 "LampFailrSts1_BrkLampAndIndcrTurnLeFailr" 7 "LampFailrSts1_BrkAndIndcrTurnAllFailr";
VAL_ 257 TrlrSrvReqToHMI 0 "DevErrSts2_NoFlt" 1 "DevErrSts2_Flt";
VAL_ 257 TrSts 0 "DoorSts2_Ukwn" 1 "DoorSts2_Opend" 2 "DoorSts2_Clsd";
VAL_ 257 TurnIndcrFaultRearLe 0 "DiagExtrLiLinRe_Init" 1 "DiagExtrLiLinRe_NoFlt" 2 "DiagExtrLiLinRe_Warning" 3 "DiagExtrLiLinRe_Flt";
VAL_ 257 TurnIndcrFaultRearRi 0 "DiagExtrLiLinRe_Init" 1 "DiagExtrLiLinRe_NoFlt" 2 "DiagExtrLiLinRe_Warning" 3 "DiagExtrLiLinRe_Flt";
VAL_ 257 TurnIndcrFaultSideLe 0 "DiagExtrLiLinRe_Init" 1 "DiagExtrLiLinRe_NoFlt" 2 "DiagExtrLiLinRe_Warning" 3 "DiagExtrLiLinRe_Flt";
VAL_ 257 TurnIndcrFaultSideRi 0 "DiagExtrLiLinRe_Init" 1 "DiagExtrLiLinRe_NoFlt" 2 "DiagExtrLiLinRe_Warning" 3 "DiagExtrLiLinRe_Flt";
VAL_ 257 TwbrStsTwbrSts 0 "TwbrPosnSts_Uknwn" 1 "TwbrPosnSts_Unlocked" 2 "TwbrPosnSts_Locked" 3 "TwbrPosnSts_Outfolded" 4 "TwbrPosnSts_MovingIn" 5 "TwbrPosnSts_Infolded" 6 "TwbrPosnSts_MovingOut" 7 "TwbrPosnSts_Reserved";
VAL_ 257 TwbrStsTwbrTyp 0 "TwbrTyp_Semi1" 1 "TwbrTyp_Semi2" 2 "TwbrTyp_Semi3" 3 "TwbrTyp_Full1" 4 "TwbrTyp_Full2" 5 "TwbrTyp_Full3" 6 "TwbrTyp_Ful4" 7 "TwbrTyp_Fixed";
VAL_ 257 WinPosnStsAtDrv 0 "WinAndRoofAndCurtPosnTyp_PosnUkwn" 1 "WinAndRoofAndCurtPosnTyp_ClsFull" 2 "WinAndRoofAndCurtPosnTyp_PercOpen4" 3 "WinAndRoofAndCurtPosnTyp_PercOpen8" 4 "WinAndRoofAndCurtPosnTyp_PercOpen12" 5 "WinAndRoofAndCurtPosnTyp_PercOpen16" 6 "WinAndRoofAndCurtPosnTyp_PercOpen20" 7 "WinAndRoofAndCurtPosnTyp_PercOpen24" 8 "WinAndRoofAndCurtPosnTyp_PercOpen28" 9 "WinAndRoofAndCurtPosnTyp_PercOpen32" 10 "WinAndRoofAndCurtPosnTyp_PercOpen36" 11 "WinAndRoofAndCurtPosnTyp_PercOpen40" 12 "WinAndRoofAndCurtPosnTyp_PercOpen44" 13 "WinAndRoofAndCurtPosnTyp_PercOpen48" 14 "WinAndRoofAndCurtPosnTyp_PercOpen52" 15 "WinAndRoofAndCurtPosnTyp_PercOpen56" 16 "WinAndRoofAndCurtPosnTyp_PercOpen60" 17 "WinAndRoofAndCurtPosnTyp_PercOpen64" 18 "WinAndRoofAndCurtPosnTyp_PercOpen68" 19 "WinAndRoofAndCurtPosnTyp_PercOpen72" 20 "WinAndRoofAndCurtPosnTyp_PercOpen76" 21 "WinAndRoofAndCurtPosnTyp_PercOpen80" 22 "WinAndRoofAndCurtPosnTyp_PercOpen84" 23 "WinAndRoofAndCurtPosnTyp_PercOpen88" 24 "WinAndRoofAndCurtPosnTyp_PercOpen92" 25 "WinAndRoofAndCurtPosnTyp_PercOpen96" 26 "WinAndRoofAndCurtPosnTyp_OpenFull" 27 "WinAndRoofAndCurtPosnTyp_Resd1" 28 "WinAndRoofAndCurtPosnTyp_Resd2" 29 "WinAndRoofAndCurtPosnTyp_Resd3" 30 "WinAndRoofAndCurtPosnTyp_Resd4" 31 "WinAndRoofAndCurtPosnTyp_Movg";
VAL_ 257 WinPosnStsAtDrvrRe 0 "WinAndRoofAndCurtPosnTyp_PosnUkwn" 1 "WinAndRoofAndCurtPosnTyp_ClsFull" 2 "WinAndRoofAndCurtPosnTyp_PercOpen4" 3 "WinAndRoofAndCurtPosnTyp_PercOpen8" 4 "WinAndRoofAndCurtPosnTyp_PercOpen12" 5 "WinAndRoofAndCurtPosnTyp_PercOpen16" 6 "WinAndRoofAndCurtPosnTyp_PercOpen20" 7 "WinAndRoofAndCurtPosnTyp_PercOpen24" 8 "WinAndRoofAndCurtPosnTyp_PercOpen28" 9 "WinAndRoofAndCurtPosnTyp_PercOpen32" 10 "WinAndRoofAndCurtPosnTyp_PercOpen36" 11 "WinAndRoofAndCurtPosnTyp_PercOpen40" 12 "WinAndRoofAndCurtPosnTyp_PercOpen44" 13 "WinAndRoofAndCurtPosnTyp_PercOpen48" 14 "WinAndRoofAndCurtPosnTyp_PercOpen52" 15 "WinAndRoofAndCurtPosnTyp_PercOpen56" 16 "WinAndRoofAndCurtPosnTyp_PercOpen60" 17 "WinAndRoofAndCurtPosnTyp_PercOpen64" 18 "WinAndRoofAndCurtPosnTyp_PercOpen68" 19 "WinAndRoofAndCurtPosnTyp_PercOpen72" 20 "WinAndRoofAndCurtPosnTyp_PercOpen76" 21 "WinAndRoofAndCurtPosnTyp_PercOpen80" 22 "WinAndRoofAndCurtPosnTyp_PercOpen84" 23 "WinAndRoofAndCurtPosnTyp_PercOpen88" 24 "WinAndRoofAndCurtPosnTyp_PercOpen92" 25 "WinAndRoofAndCurtPosnTyp_PercOpen96" 26 "WinAndRoofAndCurtPosnTyp_OpenFull" 27 "WinAndRoofAndCurtPosnTyp_Resd1" 28 "WinAndRoofAndCurtPosnTyp_Resd2" 29 "WinAndRoofAndCurtPosnTyp_Resd3" 30 "WinAndRoofAndCurtPosnTyp_Resd4" 31 "WinAndRoofAndCurtPosnTyp_Movg";
VAL_ 257 WinPosnStsAtPass 0 "WinAndRoofAndCurtPosnTyp_PosnUkwn" 1 "WinAndRoofAndCurtPosnTyp_ClsFull" 2 "WinAndRoofAndCurtPosnTyp_PercOpen4" 3 "WinAndRoofAndCurtPosnTyp_PercOpen8" 4 "WinAndRoofAndCurtPosnTyp_PercOpen12" 5 "WinAndRoofAndCurtPosnTyp_PercOpen16" 6 "WinAndRoofAndCurtPosnTyp_PercOpen20" 7 "WinAndRoofAndCurtPosnTyp_PercOpen24" 8 "WinAndRoofAndCurtPosnTyp_PercOpen28" 9 "WinAndRoofAndCurtPosnTyp_PercOpen32" 10 "WinAndRoofAndCurtPosnTyp_PercOpen36" 11 "WinAndRoofAndCurtPosnTyp_PercOpen40" 12 "WinAndRoofAndCurtPosnTyp_PercOpen44" 13 "WinAndRoofAndCurtPosnTyp_PercOpen48" 14 "WinAndRoofAndCurtPosnTyp_PercOpen52" 15 "WinAndRoofAndCurtPosnTyp_PercOpen56" 16 "WinAndRoofAndCurtPosnTyp_PercOpen60" 17 "WinAndRoofAndCurtPosnTyp_PercOpen64" 18 "WinAndRoofAndCurtPosnTyp_PercOpen68" 19 "WinAndRoofAndCurtPosnTyp_PercOpen72" 20 "WinAndRoofAndCurtPosnTyp_PercOpen76" 21 "WinAndRoofAndCurtPosnTyp_PercOpen80" 22 "WinAndRoofAndCurtPosnTyp_PercOpen84" 23 "WinAndRoofAndCurtPosnTyp_PercOpen88" 24 "WinAndRoofAndCurtPosnTyp_PercOpen92" 25 "WinAndRoofAndCurtPosnTyp_PercOpen96" 26 "WinAndRoofAndCurtPosnTyp_OpenFull" 27 "WinAndRoofAndCurtPosnTyp_Resd1" 28 "WinAndRoofAndCurtPosnTyp_Resd2" 29 "WinAndRoofAndCurtPosnTyp_Resd3" 30 "WinAndRoofAndCurtPosnTyp_Resd4" 31 "WinAndRoofAndCurtPosnTyp_Movg";
VAL_ 257 WinPosnStsAtPassRe 0 "WinAndRoofAndCurtPosnTyp_PosnUkwn" 1 "WinAndRoofAndCurtPosnTyp_ClsFull" 2 "WinAndRoofAndCurtPosnTyp_PercOpen4" 3 "WinAndRoofAndCurtPosnTyp_PercOpen8" 4 "WinAndRoofAndCurtPosnTyp_PercOpen12" 5 "WinAndRoofAndCurtPosnTyp_PercOpen16" 6 "WinAndRoofAndCurtPosnTyp_PercOpen20" 7 "WinAndRoofAndCurtPosnTyp_PercOpen24" 8 "WinAndRoofAndCurtPosnTyp_PercOpen28" 9 "WinAndRoofAndCurtPosnTyp_PercOpen32" 10 "WinAndRoofAndCurtPosnTyp_PercOpen36" 11 "WinAndRoofAndCurtPosnTyp_PercOpen40" 12 "WinAndRoofAndCurtPosnTyp_PercOpen44" 13 "WinAndRoofAndCurtPosnTyp_PercOpen48" 14 "WinAndRoofAndCurtPosnTyp_PercOpen52" 15 "WinAndRoofAndCurtPosnTyp_PercOpen56" 16 "WinAndRoofAndCurtPosnTyp_PercOpen60" 17 "WinAndRoofAndCurtPosnTyp_PercOpen64" 18 "WinAndRoofAndCurtPosnTyp_PercOpen68" 19 "WinAndRoofAndCurtPosnTyp_PercOpen72" 20 "WinAndRoofAndCurtPosnTyp_PercOpen76" 21 "WinAndRoofAndCurtPosnTyp_PercOpen80" 22 "WinAndRoofAndCurtPosnTyp_PercOpen84" 23 "WinAndRoofAndCurtPosnTyp_PercOpen88" 24 "WinAndRoofAndCurtPosnTyp_PercOpen92" 25 "WinAndRoofAndCurtPosnTyp_PercOpen96" 26 "WinAndRoofAndCurtPosnTyp_OpenFull" 27 "WinAndRoofAndCurtPosnTyp_Resd1" 28 "WinAndRoofAndCurtPosnTyp_Resd2" 29 "WinAndRoofAndCurtPosnTyp_Resd3" 30 "WinAndRoofAndCurtPosnTyp_Resd4" 31 "WinAndRoofAndCurtPosnTyp_Movg";
VAL_ 256 ActvnOfDispIllmnCSD 0 "Boolean_FALSE" 1 "Boolean_TRUE";
VAL_ 256 ActvnOfDispIllmnDIM 0 "Boolean_FALSE" 1 "Boolean_TRUE";
VAL_ 256 ActvnOfSwtIllmnMSM 0 "Boolean_FALSE" 1 "Boolean_TRUE";
VAL_ 256 ActvnOfSwtIllmnRCSM 0 "Boolean_FALSE" 1 "Boolean_TRUE";
VAL_ 256 ActvnOfSwtIllmnSWM 0 "Boolean_FALSE" 1 "Boolean_TRUE";
VAL_ 256 ActvnOfSwtIllmnSWS 0 "Boolean_FALSE" 1 "Boolean_TRUE";
VAL_ 256 ADPMWakeUp 0 "OnOff1_Off" 1 "OnOff1_On";
VAL_ 256 AUDWakeUp 0 "OnOff1_Off" 1 "OnOff1_On";
VAL_ 256 ClimateActuatorsRelay 0 "OnOff1_Off" 1 "OnOff1_On";
VAL_ 256 DIMWakeUp 0 "OnOff1_Off" 1 "OnOff1_On";
VAL_ 256 DrvrDetnOfMovmtInCbnRecIfDetnSts 0 "DetnSts_Undefd" 1 "DetnSts_NotDetd" 2 "DetnSts_Detd" 3 "DetnSts_Resd";
VAL_ 256 DrvrDetnOfMovmtInCbnRecIfIntrDetnAvlSts 0 "IntrDetnAvlSts_Undefd" 1 "IntrDetnAvlSts_NotAvl" 2 "IntrDetnAvlSts_Avl" 3 "IntrDetnAvlSts_Flt" 4 "IntrDetnAvlSts_PosnNotPrsnt" 5 "IntrDetnAvlSts_Resd0" 6 "IntrDetnAvlSts_Resd1" 7 "IntrDetnAvlSts_Resd2";
VAL_ 256 DrvrDetnOfMovmtInCbnRecIfIntrDetnOf 0 "IntrDetnQf_Undefd" 1 "IntrDetnQf_InProgs" 2 "IntrDetnQf_NotSpec" 3 "IntrDetnQf_DataOK";
VAL_ 256 DrvrDetnOfPresInSeatRecIfDetnSts 0 "DetnSts_Undefd" 1 "DetnSts_NotDetd" 2 "DetnSts_Detd" 3 "DetnSts_Resd";
VAL_ 256 DrvrDetnOfPresInSeatRecIfIntrDetnAvlSts 0 "IntrDetnAvlSts_Undefd" 1 "IntrDetnAvlSts_NotAvl" 2 "IntrDetnAvlSts_Avl" 3 "IntrDetnAvlSts_Flt" 4 "IntrDetnAvlSts_PosnNotPrsnt" 5 "IntrDetnAvlSts_Resd0" 6 "IntrDetnAvlSts_Resd1" 7 "IntrDetnAvlSts_Resd2";
VAL_ 256 DrvrDetnOfPresInSeatRecIfIntrDetnOf 0 "IntrDetnQf_Undefd" 1 "IntrDetnQf_InProgs" 2 "IntrDetnQf_NotSpec" 3 "IntrDetnQf_DataOK";
VAL_ 256 DrvrDetnOfPresRecIfDetnSts 0 "DetnSts_Undefd" 1 "DetnSts_NotDetd" 2 "DetnSts_Detd" 3 "DetnSts_Resd";
VAL_ 256 DrvrDetnOfPresRecIfIntrDetnAvlSts 0 "IntrDetnAvlSts_Undefd" 1 "IntrDetnAvlSts_NotAvl" 2 "IntrDetnAvlSts_Avl" 3 "IntrDetnAvlSts_Flt" 4 "IntrDetnAvlSts_PosnNotPrsnt" 5 "IntrDetnAvlSts_Resd0" 6 "IntrDetnAvlSts_Resd1" 7 "IntrDetnAvlSts_Resd2";
VAL_ 256 DrvrDetnOfPresRecIfIntrDetnOf 0 "IntrDetnQf_Undefd" 1 "IntrDetnQf_InProgs" 2 "IntrDetnQf_NotSpec" 3 "IntrDetnQf_DataOK";
VAL_ 256 ExteriorLightRelay 0 "OnOff1_Off" 1 "OnOff1_On";
VAL_ 256 IgnitionPowerRelay 0 "OnOff1_Off" 1 "OnOff1_On";
VAL_ 256 NfcCardAuthPrnstSubZoneLocation 0 "ApproachSubZoneEnum_LeftSideFront" 1 "ApproachSubZoneEnum_LeftSideRear" 2 "ApproachSubZoneEnum_Trunk" 3 "ApproachSubZoneEnum_RightSideRear" 4 "ApproachSubZoneEnum_RightSideFront" 5 "ApproachSubZoneEnum_Frunk" 6 "ApproachSubZoneEnum_ExtNfcReader" 7 "ApproachSubZoneEnum_IntNfcReader" 8 "ApproachSubZoneEnum_Spare1" 9 "ApproachSubZoneEnum_Spare2" 10 "ApproachSubZoneEnum_Spare3" 11 "ApproachSubZoneEnum_Spare4" 12 "ApproachSubZoneEnum_Spare5" 13 "ApproachSubZoneEnum_Spare6" 14 "ApproachSubZoneEnum_ConnBleOutsideUwb" 15 "ApproachSubZoneEnum_NoDeviceDefault";
VAL_ 256 PassDetnOfMovmtInCbnRecIfDetnSts 0 "DetnSts_Undefd" 1 "DetnSts_NotDetd" 2 "DetnSts_Detd" 3 "DetnSts_Resd";
VAL_ 256 PassDetnOfMovmtInCbnRecIfIntrDetnAvlSts 0 "IntrDetnAvlSts_Undefd" 1 "IntrDetnAvlSts_NotAvl" 2 "IntrDetnAvlSts_Avl" 3 "IntrDetnAvlSts_Flt" 4 "IntrDetnAvlSts_PosnNotPrsnt" 5 "IntrDetnAvlSts_Resd0" 6 "IntrDetnAvlSts_Resd1" 7 "IntrDetnAvlSts_Resd2";
VAL_ 256 PassDetnOfMovmtInCbnRecIfIntrDetnOf 0 "IntrDetnQf_Undefd" 1 "IntrDetnQf_InProgs" 2 "IntrDetnQf_NotSpec" 3 "IntrDetnQf_DataOK";
VAL_ 256 PassDetnOfPresInSeatRecIfDetnSts 0 "DetnSts_Undefd" 1 "DetnSts_NotDetd" 2 "DetnSts_Detd" 3 "DetnSts_Resd";
VAL_ 256 PassDetnOfPresInSeatRecIfIntrDetnAvlSts 0 "IntrDetnAvlSts_Undefd" 1 "IntrDetnAvlSts_NotAvl" 2 "IntrDetnAvlSts_Avl" 3 "IntrDetnAvlSts_Flt" 4 "IntrDetnAvlSts_PosnNotPrsnt" 5 "IntrDetnAvlSts_Resd0" 6 "IntrDetnAvlSts_Resd1" 7 "IntrDetnAvlSts_Resd2";
VAL_ 256 PassDetnOfPresInSeatRecIfIntrDetnOf 0 "IntrDetnQf_Undefd" 1 "IntrDetnQf_InProgs" 2 "IntrDetnQf_NotSpec" 3 "IntrDetnQf_DataOK";
VAL_ 256 PassDetnOfPresRecIfDetnSts 0 "DetnSts_Undefd" 1 "DetnSts_NotDetd" 2 "DetnSts_Detd" 3 "DetnSts_Resd";
VAL_ 256 PassDetnOfPresRecIfIntrDetnAvlSts 0 "IntrDetnAvlSts_Undefd" 1 "IntrDetnAvlSts_NotAvl" 2 "IntrDetnAvlSts_Avl" 3 "IntrDetnAvlSts_Flt" 4 "IntrDetnAvlSts_PosnNotPrsnt" 5 "IntrDetnAvlSts_Resd0" 6 "IntrDetnAvlSts_Resd1" 7 "IntrDetnAvlSts_Resd2";
VAL_ 256 PassDetnOfPresRecIfIntrDetnOf 0 "IntrDetnQf_Undefd" 1 "IntrDetnQf_InProgs" 2 "IntrDetnQf_NotSpec" 3 "IntrDetnQf_DataOK";
VAL_ 256 SUMWakeUp 0 "OnOff1_Off" 1 "OnOff1_On";
VAL_ 256 TrlrPrsnt1 0 "TrlrPrsntSts_TrlrNotPrsnt" 1 "TrlrPrsntSts_TrlrPrsnt";
VAL_ 256 UsageModeAvailable 0 "OnOff1_Off" 1 "OnOff1_On";
VAL_ 256 UsageModeAwake 0 "OnOff1_Off" 1 "OnOff1_On";
VAL_ 256 UsageModeResponsive 0 "OnOff1_Off" 1 "OnOff1_On";
VAL_ 260 DayNitStsValue 0 "OutdBriSts_Ukwn" 1 "OutdBriSts_Night" 2 "OutdBriSts_Day" 3 "OutdBriSts_Invld";
VAL_ 260 DoorDrvrStsSafeDoorSts 0 "DoorSts2_Ukwn" 1 "DoorSts2_Opend" 2 "DoorSts2_Clsd";
VAL_ 260 ExLiHcFltHdlampHozlLe 0 "DevErrSts2_NoFlt" 1 "DevErrSts2_Flt";
VAL_ 260 ExLiHcFltHdlampHozlRi 0 "DevErrSts2_NoFlt" 1 "DevErrSts2_Flt";
VAL_ 260 ExLiHcFltHdlampIndcrTurnLeSts 0 "DevErrSts2_NoFlt" 1 "DevErrSts2_Flt";
VAL_ 260 ExLiHcFltHdlampIndcrTurnRiSts 0 "DevErrSts2_NoFlt" 1 "DevErrSts2_Flt";
VAL_ 260 ExLiHcFltHdlampLvlLe 0 "DevErrSts2_NoFlt" 1 "DevErrSts2_Flt";
VAL_ 260 ExLiHcFltHdlampLvlRi 0 "DevErrSts2_NoFlt" 1 "DevErrSts2_Flt";
VAL_ 260 ExLiHcHdlampConcealFltLe 0 "DevErrSts2_NoFlt" 1 "DevErrSts2_Flt";
VAL_ 260 ExLiHcHdlampConcealFltRi 0 "DevErrSts2_NoFlt" 1 "DevErrSts2_Flt";
VAL_ 260 ExLiHcHdlampConcealStsLePosnSts 0 "HdlampConcealPosnSts_Uknwn" 1 "HdlampConcealPosnSts_Actv" 2 "HdlampConcealPosnSts_Closed" 3 "HdlampConcealPosnSts_Btwn" 4 "HdlampConcealPosnSts_Open" 5 "HdlampConcealPosnSts_Failr";
VAL_ 260 ExLiHcHdlampConcealStsLeRefSts 0 "HdlampConcealRefSts_Uknwn" 1 "HdlampConcealRefSts_Actv" 2 "HdlampConcealRefSts_Cmpl" 3 "HdlampConcealRefSts_Failr";
VAL_ 260 ExLiHcHdlampConcealStsRiPosnSts 0 "HdlampConcealPosnSts_Uknwn" 1 "HdlampConcealPosnSts_Actv" 2 "HdlampConcealPosnSts_Closed" 3 "HdlampConcealPosnSts_Btwn" 4 "HdlampConcealPosnSts_Open" 5 "HdlampConcealPosnSts_Failr";
VAL_ 260 ExLiHcHdlampConcealStsRiRefSts 0 "HdlampConcealRefSts_Uknwn" 1 "HdlampConcealRefSts_Actv" 2 "HdlampConcealRefSts_Cmpl" 3 "HdlampConcealRefSts_Failr";
VAL_ 260 ExLiHcHozlRefStsLe 0 "LvlRefSts_Uknwn" 1 "LvlRefSts_Actv" 2 "LvlRefSts_Cmpl" 3 "LvlRefSts_Failr";
VAL_ 260 ExLiHcHozlRefStsRi 0 "LvlRefSts_Uknwn" 1 "LvlRefSts_Actv" 2 "LvlRefSts_Cmpl" 3 "LvlRefSts_Failr";
VAL_ 260 ExLiHcLvlRefStsLe 0 "LvlRefSts_Uknwn" 1 "LvlRefSts_Actv" 2 "LvlRefSts_Cmpl" 3 "LvlRefSts_Failr";
VAL_ 260 ExLiHcLvlRefStsRi 0 "LvlRefSts_Uknwn" 1 "LvlRefSts_Actv" 2 "LvlRefSts_Cmpl" 3 "LvlRefSts_Failr";
VAL_ 260 ExLiHdCalibrationDtcLe 0 "Boolean_FALSE" 1 "Boolean_TRUE";
VAL_ 260 ExLiHdCalibrationDtcRi 0 "Boolean_FALSE" 1 "Boolean_TRUE";
VAL_ 260 ExLiHWLRequest 0 "Boolean_FALSE" 1 "Boolean_TRUE";
VAL_ 260 ExLiLpFltRearPosLiLe 0 "DiagExtrLiLinRe_Init" 1 "DiagExtrLiLinRe_NoFlt" 2 "DiagExtrLiLinRe_Warning" 3 "DiagExtrLiLinRe_Flt";
VAL_ 260 ExLiLpFltRearPosLiRi 0 "DiagExtrLiLinRe_Init" 1 "DiagExtrLiLinRe_NoFlt" 2 "DiagExtrLiLinRe_Warning" 3 "DiagExtrLiLinRe_Flt";
VAL_ 260 ExLiLpFltRegPlate 0 "DiagExtrLiLinRe_Init" 1 "DiagExtrLiLinRe_NoFlt" 2 "DiagExtrLiLinRe_Warning" 3 "DiagExtrLiLinRe_Flt";
VAL_ 260 FrontWiperStatus 0 "FrontWiperStatus_Unknown" 1 "FrontWiperStatus_Off" 2 "FrontWiperStatus_Auto" 3 "FrontWiperStatus_Low" 4 "FrontWiperStatus_High";
VAL_ 260 OhcDefrstReq 0 "OnOff1_Off" 1 "OnOff1_On";
VAL_ 260 RainLiCmd 0 "OnOff1_Off" 1 "OnOff1_On";
VAL_ 260 Washer 0 "Washer_Unknown" 1 "Washer_WasherOff" 2 "Washer_WasherOn";
VAL_ 260 WasherRearStatus 0 "Washer_Unknown" 1 "Washer_WasherOff" 2 "Washer_WasherOn";
VAL_ 260 WiprInPosnForSrv 0 "OnOff1_Off" 1 "OnOff1_On";
VAL_ 260 WiprInWipgAr 0 "OnOff1_Off" 1 "OnOff1_On";
VAL_ 260 WshrFldSts1WdElmHMI 0 "OnOff1_Off" 1 "OnOff1_On";
VAL_ 259 DiagcInfoForSunSnsrIntErr 0 "Flg1_Rst" 1 "Flg1_Set";
VAL_ 259 DiagcInfoForSunSnsrLedForSecuFailr 0 "Flg1_Rst" 1 "Flg1_Set";
VAL_ 259 DiagcInfoForSunSnsrSnsrForTFailr 0 "Flg1_Rst" 1 "Flg1_Set";
VAL_ 259 DiagcInfoForSunSnsrTmrRst 0 "Flg1_Rst" 1 "Flg1_Set";
VAL_ 259 DiagcInfoForSunSnsrUHi 0 "Flg1_Rst" 1 "Flg1_Set";
VAL_ 259 DiagcInfoForSunSnsrULo 0 "Flg1_Rst" 1 "Flg1_Set";
VAL_ 259 SunSnsrQf 0 "SunSnsrQf_SnsrDataUndefd" 1 "SunSnsrQf_Resd" 2 "SunSnsrQf_SnsrDataNotOk" 3 "SunSnsrQf_SnsrDataOk";
VAL_ 261 DetnOfMovmtInCbnReLeRecIfDetnSts 0 "DetnSts_Undefd" 1 "DetnSts_NotDetd" 2 "DetnSts_Detd" 3 "DetnSts_Resd";
VAL_ 261 DetnOfMovmtInCbnReLeRecIfIntrDetnAvlSts 0 "IntrDetnAvlSts_Undefd" 1 "IntrDetnAvlSts_NotAvl" 2 "IntrDetnAvlSts_Avl" 3 "IntrDetnAvlSts_Flt" 4 "IntrDetnAvlSts_PosnNotPrsnt" 5 "IntrDetnAvlSts_Resd0" 6 "IntrDetnAvlSts_Resd1" 7 "IntrDetnAvlSts_Resd2";
VAL_ 261 DetnOfMovmtInCbnReLeRecIfIntrDetnOf 0 "IntrDetnQf_Undefd" 1 "IntrDetnQf_InProgs" 2 "IntrDetnQf_NotSpec" 3 "IntrDetnQf_DataOK";
VAL_ 261 DetnOfMovmtInCbnReRiRecIfDetnSts 0 "DetnSts_Undefd" 1 "DetnSts_NotDetd" 2 "DetnSts_Detd" 3 "DetnSts_Resd";
VAL_ 261 DetnOfMovmtInCbnReRiRecIfIntrDetnAvlSts 0 "IntrDetnAvlSts_Undefd" 1 "IntrDetnAvlSts_NotAvl" 2 "IntrDetnAvlSts_Avl" 3 "IntrDetnAvlSts_Flt" 4 "IntrDetnAvlSts_PosnNotPrsnt" 5 "IntrDetnAvlSts_Resd0" 6 "IntrDetnAvlSts_Resd1" 7 "IntrDetnAvlSts_Resd2";
VAL_ 261 DetnOfMovmtInCbnReRiRecIfIntrDetnOf 0 "IntrDetnQf_Undefd" 1 "IntrDetnQf_InProgs" 2 "IntrDetnQf_NotSpec" 3 "IntrDetnQf_DataOK";
VAL_ 261 DetnOfMovmtInCbnThrdLeRecIfDetnSts 0 "DetnSts_Undefd" 1 "DetnSts_NotDetd" 2 "DetnSts_Detd" 3 "DetnSts_Resd";
VAL_ 261 DetnOfMovmtInCbnThrdLeRecIfIntrDetnAvlSts 0 "IntrDetnAvlSts_Undefd" 1 "IntrDetnAvlSts_NotAvl" 2 "IntrDetnAvlSts_Avl" 3 "IntrDetnAvlSts_Flt" 4 "IntrDetnAvlSts_PosnNotPrsnt" 5 "IntrDetnAvlSts_Resd0" 6 "IntrDetnAvlSts_Resd1" 7 "IntrDetnAvlSts_Resd2";
VAL_ 261 DetnOfMovmtInCbnThrdLeRecIfIntrDetnOf 0 "IntrDetnQf_Undefd" 1 "IntrDetnQf_InProgs" 2 "IntrDetnQf_NotSpec" 3 "IntrDetnQf_DataOK";
VAL_ 261 DetnOfMovmtInCbnThrdRiRecIfDetnSts 0 "DetnSts_Undefd" 1 "DetnSts_NotDetd" 2 "DetnSts_Detd" 3 "DetnSts_Resd";
VAL_ 261 DetnOfMovmtInCbnThrdRiRecIfIntrDetnAvlSts 0 "IntrDetnAvlSts_Undefd" 1 "IntrDetnAvlSts_NotAvl" 2 "IntrDetnAvlSts_Avl" 3 "IntrDetnAvlSts_Flt" 4 "IntrDetnAvlSts_PosnNotPrsnt" 5 "IntrDetnAvlSts_Resd0" 6 "IntrDetnAvlSts_Resd1" 7 "IntrDetnAvlSts_Resd2";
VAL_ 261 DetnOfMovmtInCbnThrdRiRecIfIntrDetnOf 0 "IntrDetnQf_Undefd" 1 "IntrDetnQf_InProgs" 2 "IntrDetnQf_NotSpec" 3 "IntrDetnQf_DataOK";
VAL_ 261 DetnOfMovmtInCbnTrMovmtRecIfDetnSts 0 "DetnSts_Undefd" 1 "DetnSts_NotDetd" 2 "DetnSts_Detd" 3 "DetnSts_Resd";
VAL_ 261 DetnOfMovmtInCbnTrMovmtRecIfIntrDetnAvlSts 0 "IntrDetnAvlSts_Undefd" 1 "IntrDetnAvlSts_NotAvl" 2 "IntrDetnAvlSts_Avl" 3 "IntrDetnAvlSts_Flt" 4 "IntrDetnAvlSts_PosnNotPrsnt" 5 "IntrDetnAvlSts_Resd0" 6 "IntrDetnAvlSts_Resd1" 7 "IntrDetnAvlSts_Resd2";
VAL_ 261 DetnOfMovmtInCbnTrMovmtRecIfIntrDetnOf 0 "IntrDetnQf_Undefd" 1 "IntrDetnQf_InProgs" 2 "IntrDetnQf_NotSpec" 3 "IntrDetnQf_DataOK";
VAL_ 261 DetnOfPresInSeatReLeRecIfDetnSts 0 "DetnSts_Undefd" 1 "DetnSts_NotDetd" 2 "DetnSts_Detd" 3 "DetnSts_Resd";
VAL_ 261 DetnOfPresInSeatReLeRecIfIntrDetnAvlSts 0 "IntrDetnAvlSts_Undefd" 1 "IntrDetnAvlSts_NotAvl" 2 "IntrDetnAvlSts_Avl" 3 "IntrDetnAvlSts_Flt" 4 "IntrDetnAvlSts_PosnNotPrsnt" 5 "IntrDetnAvlSts_Resd0" 6 "IntrDetnAvlSts_Resd1" 7 "IntrDetnAvlSts_Resd2";
VAL_ 261 DetnOfPresInSeatReLeRecIfIntrDetnOf 0 "IntrDetnQf_Undefd" 1 "IntrDetnQf_InProgs" 2 "IntrDetnQf_NotSpec" 3 "IntrDetnQf_DataOK";
VAL_ 261 DetnOfPresInSeatReMidRecIfDetnSts 0 "DetnSts_Undefd" 1 "DetnSts_NotDetd" 2 "DetnSts_Detd" 3 "DetnSts_Resd";
VAL_ 261 DetnOfPresInSeatReMidRecIfIntrDetnAvlSts 0 "IntrDetnAvlSts_Undefd" 1 "IntrDetnAvlSts_NotAvl" 2 "IntrDetnAvlSts_Avl" 3 "IntrDetnAvlSts_Flt" 4 "IntrDetnAvlSts_PosnNotPrsnt" 5 "IntrDetnAvlSts_Resd0" 6 "IntrDetnAvlSts_Resd1" 7 "IntrDetnAvlSts_Resd2";
VAL_ 261 DetnOfPresInSeatReMidRecIfIntrDetnOf 0 "IntrDetnQf_Undefd" 1 "IntrDetnQf_InProgs" 2 "IntrDetnQf_NotSpec" 3 "IntrDetnQf_DataOK";
VAL_ 261 DetnOfPresInSeatReRiRecIfDetnSts 0 "DetnSts_Undefd" 1 "DetnSts_NotDetd" 2 "DetnSts_Detd" 3 "DetnSts_Resd";
VAL_ 261 DetnOfPresInSeatReRiRecIfIntrDetnAvlSts 0 "IntrDetnAvlSts_Undefd" 1 "IntrDetnAvlSts_NotAvl" 2 "IntrDetnAvlSts_Avl" 3 "IntrDetnAvlSts_Flt" 4 "IntrDetnAvlSts_PosnNotPrsnt" 5 "IntrDetnAvlSts_Resd0" 6 "IntrDetnAvlSts_Resd1" 7 "IntrDetnAvlSts_Resd2";
VAL_ 261 DetnOfPresInSeatReRiRecIfIntrDetnOf 0 "IntrDetnQf_Undefd" 1 "IntrDetnQf_InProgs" 2 "IntrDetnQf_NotSpec" 3 "IntrDetnQf_DataOK";
VAL_ 261 DetnOfPresInSeatThrdLeRecIfDetnSts 0 "DetnSts_Undefd" 1 "DetnSts_NotDetd" 2 "DetnSts_Detd" 3 "DetnSts_Resd";
VAL_ 261 DetnOfPresInSeatThrdLeRecIfIntrDetnAvlSts 0 "IntrDetnAvlSts_Undefd" 1 "IntrDetnAvlSts_NotAvl" 2 "IntrDetnAvlSts_Avl" 3 "IntrDetnAvlSts_Flt" 4 "IntrDetnAvlSts_PosnNotPrsnt" 5 "IntrDetnAvlSts_Resd0" 6 "IntrDetnAvlSts_Resd1" 7 "IntrDetnAvlSts_Resd2";
VAL_ 261 DetnOfPresInSeatThrdLeRecIfIntrDetnOf 0 "IntrDetnQf_Undefd" 1 "IntrDetnQf_InProgs" 2 "IntrDetnQf_NotSpec" 3 "IntrDetnQf_DataOK";
VAL_ 261 DetnOfPresInSeatThrdRiRecIfDetnSts 0 "DetnSts_Undefd" 1 "DetnSts_NotDetd" 2 "DetnSts_Detd" 3 "DetnSts_Resd";
VAL_ 261 DetnOfPresInSeatThrdRiRecIfIntrDetnAvlSts 0 "IntrDetnAvlSts_Undefd" 1 "IntrDetnAvlSts_NotAvl" 2 "IntrDetnAvlSts_Avl" 3 "IntrDetnAvlSts_Flt" 4 "IntrDetnAvlSts_PosnNotPrsnt" 5 "IntrDetnAvlSts_Resd0" 6 "IntrDetnAvlSts_Resd1" 7 "IntrDetnAvlSts_Resd2";
VAL_ 261 DetnOfPresInSeatThrdRiRecIfIntrDetnOf 0 "IntrDetnQf_Undefd" 1 "IntrDetnQf_InProgs" 2 "IntrDetnQf_NotSpec" 3 "IntrDetnQf_DataOK";
VAL_ 261 DetnOfPresReLeRecIfDetnSts 0 "DetnSts_Undefd" 1 "DetnSts_NotDetd" 2 "DetnSts_Detd" 3 "DetnSts_Resd";
VAL_ 261 DetnOfPresReLeRecIfIntrDetnAvlSts 0 "IntrDetnAvlSts_Undefd" 1 "IntrDetnAvlSts_NotAvl" 2 "IntrDetnAvlSts_Avl" 3 "IntrDetnAvlSts_Flt" 4 "IntrDetnAvlSts_PosnNotPrsnt" 5 "IntrDetnAvlSts_Resd0" 6 "IntrDetnAvlSts_Resd1" 7 "IntrDetnAvlSts_Resd2";
VAL_ 261 DetnOfPresReLeRecIfIntrDetnOf 0 "IntrDetnQf_Undefd" 1 "IntrDetnQf_InProgs" 2 "IntrDetnQf_NotSpec" 3 "IntrDetnQf_DataOK";
VAL_ 261 DetnOfPresReMidRecIfDetnSts 0 "DetnSts_Undefd" 1 "DetnSts_NotDetd" 2 "DetnSts_Detd" 3 "DetnSts_Resd";
VAL_ 261 DetnOfPresReMidRecIfIntrDetnAvlSts 0 "IntrDetnAvlSts_Undefd" 1 "IntrDetnAvlSts_NotAvl" 2 "IntrDetnAvlSts_Avl" 3 "IntrDetnAvlSts_Flt" 4 "IntrDetnAvlSts_PosnNotPrsnt" 5 "IntrDetnAvlSts_Resd0" 6 "IntrDetnAvlSts_Resd1" 7 "IntrDetnAvlSts_Resd2";
VAL_ 261 DetnOfPresReMidRecIfIntrDetnOf 0 "IntrDetnQf_Undefd" 1 "IntrDetnQf_InProgs" 2 "IntrDetnQf_NotSpec" 3 "IntrDetnQf_DataOK";
VAL_ 261 DetnOfPresReRiRecIfDetnSts 0 "DetnSts_Undefd" 1 "DetnSts_NotDetd" 2 "DetnSts_Detd" 3 "DetnSts_Resd";
VAL_ 261 DetnOfPresReRiRecIfIntrDetnAvlSts 0 "IntrDetnAvlSts_Undefd" 1 "IntrDetnAvlSts_NotAvl" 2 "IntrDetnAvlSts_Avl" 3 "IntrDetnAvlSts_Flt" 4 "IntrDetnAvlSts_PosnNotPrsnt" 5 "IntrDetnAvlSts_Resd0" 6 "IntrDetnAvlSts_Resd1" 7 "IntrDetnAvlSts_Resd2";
VAL_ 261 DetnOfPresReRiRecIfIntrDetnOf 0 "IntrDetnQf_Undefd" 1 "IntrDetnQf_InProgs" 2 "IntrDetnQf_NotSpec" 3 "IntrDetnQf_DataOK";
VAL_ 261 DetnOfPresThrdLeRecIfDetnSts 0 "DetnSts_Undefd" 1 "DetnSts_NotDetd" 2 "DetnSts_Detd" 3 "DetnSts_Resd";
VAL_ 261 DetnOfPresThrdLeRecIfIntrDetnAvlSts 0 "IntrDetnAvlSts_Undefd" 1 "IntrDetnAvlSts_NotAvl" 2 "IntrDetnAvlSts_Avl" 3 "IntrDetnAvlSts_Flt" 4 "IntrDetnAvlSts_PosnNotPrsnt" 5 "IntrDetnAvlSts_Resd0" 6 "IntrDetnAvlSts_Resd1" 7 "IntrDetnAvlSts_Resd2";
VAL_ 261 DetnOfPresThrdLeRecIfIntrDetnOf 0 "IntrDetnQf_Undefd" 1 "IntrDetnQf_InProgs" 2 "IntrDetnQf_NotSpec" 3 "IntrDetnQf_DataOK";
VAL_ 261 DetnOfPresThrdRiRecIfDetnSts 0 "DetnSts_Undefd" 1 "DetnSts_NotDetd" 2 "DetnSts_Detd" 3 "DetnSts_Resd";
VAL_ 261 DetnOfPresThrdRiRecIfIntrDetnAvlSts 0 "IntrDetnAvlSts_Undefd" 1 "IntrDetnAvlSts_NotAvl" 2 "IntrDetnAvlSts_Avl" 3 "IntrDetnAvlSts_Flt" 4 "IntrDetnAvlSts_PosnNotPrsnt" 5 "IntrDetnAvlSts_Resd0" 6 "IntrDetnAvlSts_Resd1" 7 "IntrDetnAvlSts_Resd2";
VAL_ 261 DetnOfPresThrdRiRecIfIntrDetnOf 0 "IntrDetnQf_Undefd" 1 "IntrDetnQf_InProgs" 2 "IntrDetnQf_NotSpec" 3 "IntrDetnQf_DataOK";
VAL_ 261 DetnOfTrPresRecIfDetnSts 0 "DetnSts_Undefd" 1 "DetnSts_NotDetd" 2 "DetnSts_Detd" 3 "DetnSts_Resd";
VAL_ 261 DetnOfTrPresRecIfIntrDetnAvlSts 0 "IntrDetnAvlSts_Undefd" 1 "IntrDetnAvlSts_NotAvl" 2 "IntrDetnAvlSts_Avl" 3 "IntrDetnAvlSts_Flt" 4 "IntrDetnAvlSts_PosnNotPrsnt" 5 "IntrDetnAvlSts_Resd0" 6 "IntrDetnAvlSts_Resd1" 7 "IntrDetnAvlSts_Resd2";
VAL_ 261 DetnOfTrPresRecIfIntrDetnOf 0 "IntrDetnQf_Undefd" 1 "IntrDetnQf_InProgs" 2 "IntrDetnQf_NotSpec" 3 "IntrDetnQf_DataOK";
VAL_ 261 ExLiLpReBrkLiFltReBrkLiLeFlt 0 "DiagExtrLiLinRe_Init" 1 "DiagExtrLiLinRe_NoFlt" 2 "DiagExtrLiLinRe_Warning" 3 "DiagExtrLiLinRe_Flt";
VAL_ 261 ExLiLpReBrkLiFltReBrkLiReFlt 0 "DiagExtrLiLinRe_Init" 1 "DiagExtrLiLinRe_NoFlt" 2 "DiagExtrLiLinRe_Warning" 3 "DiagExtrLiLinRe_Flt";
VAL_ 261 ExLiLpReFogLiFltLe 0 "DiagExtrLiLinRe_Init" 1 "DiagExtrLiLinRe_NoFlt" 2 "DiagExtrLiLinRe_Warning" 3 "DiagExtrLiLinRe_Flt";
VAL_ 261 ExLiLpReFogLiFltRi 0 "DiagExtrLiLinRe_Init" 1 "DiagExtrLiLinRe_NoFlt" 2 "DiagExtrLiLinRe_Warning" 3 "DiagExtrLiLinRe_Flt";
VAL_ 261 ExLiLpRevLiFltLe 0 "DiagExtrLiLinRe_Init" 1 "DiagExtrLiLinRe_NoFlt" 2 "DiagExtrLiLinRe_Warning" 3 "DiagExtrLiLinRe_Flt";
VAL_ 261 ExLiLpRevLiFltRi 0 "DiagExtrLiLinRe_Init" 1 "DiagExtrLiLinRe_NoFlt" 2 "DiagExtrLiLinRe_Warning" 3 "DiagExtrLiLinRe_Flt";
VAL_ 261 LpcReqNfcRespIntrEth 0 "Boolean_FALSE" 1 "Boolean_TRUE";
SIG_GROUP_ 337 AdPrimWhlAgEstimdGroupSafe 1 : AdPrimWhlAgEstimdGroupSafeChks AdPrimWhlAgEstimdGroupSafeCntr AdPrimWhlAgEstimdGroupSafeQf1 AdPrimWhlAgEstimdGroupSafeWhlAg AdPrimWhlAgEstimdGroupSafeWhlAgRate;
SIG_GROUP_ 257 AlrmSnsrSts 1 : AlrmSnsrStsInclination AlrmSnsrStsInteriorMotion AlrmSnsrStsPerimeter AlrmSnsrStsSirenConnected;
SIG_GROUP_ 257 AmbIllmnFwdSts2 1 : AmbIllmnFwdSts2AmbLiIllmn AmbIllmnFwdSts2Chks AmbIllmnFwdSts2Cntr;
SIG_GROUP_ 256 ApduCmdLpcToIntrEth 1 : ApduCmdLpcToIntrEthByte0 ApduCmdLpcToIntrEthByte1 ApduCmdLpcToIntrEthByte2 ApduCmdLpcToIntrEthByte3 ApduCmdLpcToIntrEthByte4 ApduCmdLpcToIntrEthByte5 ApduCmdLpcToIntrEthByte6 ApduCmdLpcToIntrEthByte7;
SIG_GROUP_ 256 AutoIllumReq1RCSM 1 : AutoIllumReq1RCSMDelayTime AutoIllumReq1RCSMPWM1 AutoIllumReq1RCSMPWM2 AutoIllumReq1RCSMPWM3 AutoIllumReq1RCSMReserve1 AutoIllumReq1RCSMReserve2 AutoIllumReq1RCSMTranBehavior AutoIllumReq1RCSMTranStep;
SIG_GROUP_ 256 AutoIllumReqCSD 1 : AutoIllumReqCSDDelayTime AutoIllumReqCSDPWM AutoIllumReqCSDReserve1 AutoIllumReqCSDReserve2 AutoIllumReqCSDTranBehavior AutoIllumReqCSDTranStep;
SIG_GROUP_ 256 AutoIllumReqDIM 1 : AutoIllumReqDIMDelayTime AutoIllumReqDIMPWM AutoIllumReqDIMReserve1 AutoIllumReqDIMReserve2 AutoIllumReqDIMTranBehavior AutoIllumReqDIMTranStep;
SIG_GROUP_ 256 AutoIllumReqMSM 1 : AutoIllumReqMSMDelayTime AutoIllumReqMSMPWM AutoIllumReqMSMReserve1 AutoIllumReqMSMReserve2 AutoIllumReqMSMTranBehavior AutoIllumReqMSMTranStep;
SIG_GROUP_ 256 AutoIllumReqSWM 1 : AutoIllumReqSWMDelayTime AutoIllumReqSWMPWM AutoIllumReqSWMReserve1 AutoIllumReqSWMReserve2 AutoIllumReqSWMTranBehavior AutoIllumReqSWMTranStep;
SIG_GROUP_ 256 AutoIllumReqSWS 1 : AutoIllumReqSWSDelayTime AutoIllumReqSWSPWM AutoIllumReqSWSReserve1 AutoIllumReqSWSReserve2 AutoIllumReqSWSTranBehavior AutoIllumReqSWSTranStep;
SIG_GROUP_ 257 CenLockSts 1 : CenLockStsLockSrc CenLockStsLockSts CenLockStsUpdEve;
SIG_GROUP_ 257 ChdLockSts 1 : ChdLockStsDoorDrvrRe ChdLockStsDoorPass ChdLockStsDoorPassRe;
SIG_GROUP_ 260 DayNitSts 1 : DayNitStsChks DayNitStsCntr DayNitStsValue;
SIG_GROUP_ 261 DetnOfMovmtInCbnReLeRecIf 1 : DetnOfMovmtInCbnReLeRecIfDetnSts DetnOfMovmtInCbnReLeRecIfIntrDetnAvlSts DetnOfMovmtInCbnReLeRecIfIntrDetnOf;
SIG_GROUP_ 261 DetnOfMovmtInCbnReRiRecIf 1 : DetnOfMovmtInCbnReRiRecIfDetnSts DetnOfMovmtInCbnReRiRecIfIntrDetnAvlSts DetnOfMovmtInCbnReRiRecIfIntrDetnOf;
SIG_GROUP_ 261 DetnOfMovmtInCbnThrdLeRecIf 1 : DetnOfMovmtInCbnThrdLeRecIfDetnSts DetnOfMovmtInCbnThrdLeRecIfIntrDetnAvlSts DetnOfMovmtInCbnThrdLeRecIfIntrDetnOf;
SIG_GROUP_ 261 DetnOfMovmtInCbnThrdRiRecIf 1 : DetnOfMovmtInCbnThrdRiRecIfDetnSts DetnOfMovmtInCbnThrdRiRecIfIntrDetnAvlSts DetnOfMovmtInCbnThrdRiRecIfIntrDetnOf;
SIG_GROUP_ 261 DetnOfMovmtInCbnTrMovmtRecIf 1 : DetnOfMovmtInCbnTrMovmtRecIfDetnSts DetnOfMovmtInCbnTrMovmtRecIfIntrDetnAvlSts DetnOfMovmtInCbnTrMovmtRecIfIntrDetnOf;
SIG_GROUP_ 261 DetnOfPresInSeatReLeRecIf 1 : DetnOfPresInSeatReLeRecIfDetnSts DetnOfPresInSeatReLeRecIfIntrDetnAvlSts DetnOfPresInSeatReLeRecIfIntrDetnOf;
SIG_GROUP_ 261 DetnOfPresInSeatReMidRecIf 1 : DetnOfPresInSeatReMidRecIfDetnSts DetnOfPresInSeatReMidRecIfIntrDetnAvlSts DetnOfPresInSeatReMidRecIfIntrDetnOf;
SIG_GROUP_ 261 DetnOfPresInSeatReRiRecIf 1 : DetnOfPresInSeatReRiRecIfDetnSts DetnOfPresInSeatReRiRecIfIntrDetnAvlSts DetnOfPresInSeatReRiRecIfIntrDetnOf;
SIG_GROUP_ 261 DetnOfPresInSeatThrdLeRecIf 1 : DetnOfPresInSeatThrdLeRecIfDetnSts DetnOfPresInSeatThrdLeRecIfIntrDetnAvlSts DetnOfPresInSeatThrdLeRecIfIntrDetnOf;
SIG_GROUP_ 261 DetnOfPresInSeatThrdRiRecIf 1 : DetnOfPresInSeatThrdRiRecIfDetnSts DetnOfPresInSeatThrdRiRecIfIntrDetnAvlSts DetnOfPresInSeatThrdRiRecIfIntrDetnOf;
SIG_GROUP_ 261 DetnOfPresReLeRecIf 1 : DetnOfPresReLeRecIfDetnSts DetnOfPresReLeRecIfIntrDetnAvlSts DetnOfPresReLeRecIfIntrDetnOf;
SIG_GROUP_ 261 DetnOfPresReMidRecIf 1 : DetnOfPresReMidRecIfDetnSts DetnOfPresReMidRecIfIntrDetnAvlSts DetnOfPresReMidRecIfIntrDetnOf;
SIG_GROUP_ 261 DetnOfPresReRiRecIf 1 : DetnOfPresReRiRecIfDetnSts DetnOfPresReRiRecIfIntrDetnAvlSts DetnOfPresReRiRecIfIntrDetnOf;
SIG_GROUP_ 261 DetnOfPresThrdLeRecIf 1 : DetnOfPresThrdLeRecIfDetnSts DetnOfPresThrdLeRecIfIntrDetnAvlSts DetnOfPresThrdLeRecIfIntrDetnOf;
SIG_GROUP_ 261 DetnOfPresThrdRiRecIf 1 : DetnOfPresThrdRiRecIfDetnSts DetnOfPresThrdRiRecIfIntrDetnAvlSts DetnOfPresThrdRiRecIfIntrDetnOf;
SIG_GROUP_ 261 DetnOfTrPresRecIf 1 : DetnOfTrPresRecIfDetnSts DetnOfTrPresRecIfIntrDetnAvlSts DetnOfTrPresRecIfIntrDetnOf;
SIG_GROUP_ 259 DiagcInfoForSunSnsr 1 : DiagcInfoForSunSnsrIntErr DiagcInfoForSunSnsrLedForSecuFailr DiagcInfoForSunSnsrSnsrForTFailr DiagcInfoForSunSnsrTmrRst DiagcInfoForSunSnsrUHi DiagcInfoForSunSnsrULo;
SIG_GROUP_ 260 DoorDrvrStsSafe 1 : DoorDrvrStsSafeChks DoorDrvrStsSafeCntr DoorDrvrStsSafeDoorSts;
SIG_GROUP_ 256 DrvrDetnOfMovmtInCbnRecIf 1 : DrvrDetnOfMovmtInCbnRecIfDetnSts DrvrDetnOfMovmtInCbnRecIfIntrDetnAvlSts DrvrDetnOfMovmtInCbnRecIfIntrDetnOf;
SIG_GROUP_ 256 DrvrDetnOfPresInSeatRecIf 1 : DrvrDetnOfPresInSeatRecIfDetnSts DrvrDetnOfPresInSeatRecIfIntrDetnAvlSts DrvrDetnOfPresInSeatRecIfIntrDetnOf;
SIG_GROUP_ 256 DrvrDetnOfPresRecIf 1 : DrvrDetnOfPresRecIfDetnSts DrvrDetnOfPresRecIfIntrDetnAvlSts DrvrDetnOfPresRecIfIntrDetnOf;
SIG_GROUP_ 257 DrvrGearShiftDirReqAux 1 : DrvrGearShiftDirReqAuxChks DrvrGearShiftDirReqAuxCntr DrvrGearShiftDirReqAuxDrvrGearShiftDirReqAukSts DrvrGearShiftDirReqAuxPosn;
SIG_GROUP_ 337 EpbSts2 1 : EpbSts2EpbSts EpbSts2EpbStsChks EpbSts2EpbStsCntr;
SIG_GROUP_ 260 ExLiHcFltHdlampIndcrTurnLe 1 : ExLiHcFltHdlampIndcrTurnLeChks ExLiHcFltHdlampIndcrTurnLeCntr ExLiHcFltHdlampIndcrTurnLeSts;
SIG_GROUP_ 260 ExLiHcFltHdlampIndcrTurnRi 1 : ExLiHcFltHdlampIndcrTurnRiChks ExLiHcFltHdlampIndcrTurnRiCntr ExLiHcFltHdlampIndcrTurnRiSts;
SIG_GROUP_ 260 ExLiHcHdlampConcealStsLe 1 : ExLiHcHdlampConcealStsLePosnSts ExLiHcHdlampConcealStsLeRefSts;
SIG_GROUP_ 260 ExLiHcHdlampConcealStsRi 1 : ExLiHcHdlampConcealStsRiPosnSts ExLiHcHdlampConcealStsRiRefSts;
SIG_GROUP_ 260 ExLiLpFltRearPosLi 1 : ExLiLpFltRearPosLiLe ExLiLpFltRearPosLiRi;
SIG_GROUP_ 261 ExLiLpReBrkLiFlt 1 : ExLiLpReBrkLiFltChks ExLiLpReBrkLiFltCntr ExLiLpReBrkLiFltReBrkLiLeFlt ExLiLpReBrkLiFltReBrkLiReFlt;
SIG_GROUP_ 261 ExLiLpReFogLiFlt 1 : ExLiLpReFogLiFltLe ExLiLpReFogLiFltRi;
SIG_GROUP_ 261 ExLiLpRevLiFlt 1 : ExLiLpRevLiFltLe ExLiLpRevLiFltRi;
SIG_GROUP_ 337 FrntLeWhlSpdSnsrData 1 : FrntLeWhlSpdSnsrDataChks FrntLeWhlSpdSnsrDataCntr FrntLeWhlSpdSnsrDataWhlAgSpdFrntLe FrntLeWhlSpdSnsrDataWhlAgSpdFrntLeQf FrntLeWhlSpdSnsrDataWhlRotDirFrntLe FrntLeWhlSpdSnsrDataWhlRotDirFrntLeQf FrntLeWhlSpdSnsrDataWhlRotToothCntrFrntLe FrntLeWhlSpdSnsrDataWhlRotToothCntrFrntLeQf;
SIG_GROUP_ 337 FrntRiWhlSpdSnsrData 1 : FrntRiWhlSpdSnsrDataChks FrntRiWhlSpdSnsrDataCntr FrntRiWhlSpdSnsrDataWhlAgSpdFrntRi FrntRiWhlSpdSnsrDataWhlAgSpdFrntRiQf FrntRiWhlSpdSnsrDataWhlRotDirFrntRi FrntRiWhlSpdSnsrDataWhlRotDirFrntRiQf FrntRiWhlSpdSnsrDataWhlRotToothCntrFrntRi FrntRiWhlSpdSnsrDataWhlRotToothCntrFrntRiQf;
SIG_GROUP_ 337 IMURawData 1 : IMURawDataIMULatAccRaw IMURawDataIMULatAccRawQf IMURawDataIMULongAccRaw IMURawDataIMULongAccRawQf IMURawDataIMUPitchRateRaw IMURawDataIMUPitchRateRawQf IMURawDataIMURollRateRaw IMURawDataIMURollRateRawQf IMURawDataIMUVertAccRaw IMURawDataIMUVertAccRawQf IMURawDataIMUYawRateRaw IMURawDataIMUYawRateRawQf IMURawDataIndicationChks IMURawDataIndicationCntr;
SIG_GROUP_ 257 MirrPosnSensFdbValDrvr 1 : MirrPosnSensFdbValDrvrMirrSensXPos MirrPosnSensFdbValDrvrMirrSensYPos;
SIG_GROUP_ 257 MirrPosnSensFdbValPass 1 : MirrPosnSensFdbValPassMirrSensXPos MirrPosnSensFdbValPassMirrSensYPos;
SIG_GROUP_ 256 NfcCardAuthPrnst 1 : NfcCardAuthPrnstPakNfcDeviceIDInt NfcCardAuthPrnstSubZoneLocation;
SIG_GROUP_ 337 NFSStMacSts 1 : NFSStMacStsNFSActvSt NFSStMacStsNFSIntrfInfoTyp;
SIG_GROUP_ 339 OutdT 1 : OutdTAmbTVal OutdTQly;
SIG_GROUP_ 256 PassDetnOfMovmtInCbnRecIf 1 : PassDetnOfMovmtInCbnRecIfDetnSts PassDetnOfMovmtInCbnRecIfIntrDetnAvlSts PassDetnOfMovmtInCbnRecIfIntrDetnOf;
SIG_GROUP_ 256 PassDetnOfPresInSeatRecIf 1 : PassDetnOfPresInSeatRecIfDetnSts PassDetnOfPresInSeatRecIfIntrDetnAvlSts PassDetnOfPresInSeatRecIfIntrDetnOf;
SIG_GROUP_ 256 PassDetnOfPresRecIf 1 : PassDetnOfPresRecIfDetnSts PassDetnOfPresRecIfIntrDetnAvlSts PassDetnOfPresRecIfIntrDetnOf;
SIG_GROUP_ 337 ReLeWhlSpdSnsrData 1 : ReLeWhlSpdSnsrDataChks ReLeWhlSpdSnsrDataCntr ReLeWhlSpdSnsrDataWhlAgSpdReLe ReLeWhlSpdSnsrDataWhlAgSpdReLeQf ReLeWhlSpdSnsrDataWhlRotDirReLe ReLeWhlSpdSnsrDataWhlRotDirReLeQf ReLeWhlSpdSnsrDataWhlRotToothCntrReLe ReLeWhlSpdSnsrDataWhlRotToothCntrReLeQf;
SIG_GROUP_ 337 ReRiWhlSpdSnsrData 1 : ReRiWhlSpdSnsrDataChks ReRiWhlSpdSnsrDataCntr ReRiWhlSpdSnsrDataWhlAgSpdReRi ReRiWhlSpdSnsrDataWhlAgSpdReRiQf ReRiWhlSpdSnsrDataWhlRotDirReRi ReRiWhlSpdSnsrDataWhlRotDirReRiQf ReRiWhlSpdSnsrDataWhlRotToothCntrReRi ReRiWhlSpdSnsrDataWhlRotToothCntrReRiQf;
SIG_GROUP_ 257 SeatRowSecBackRestSwtSts 1 : SeatRowSecBackRestSwtStsSwtLeSts SeatRowSecBackRestSwtStsSwtRiSts;
SIG_GROUP_ 257 SeatSwtTrSts 1 : SeatSwtTrStsLeHalfSts SeatSwtTrStsRiHalfSts;
SIG_GROUP_ 259 SunSnsr 1 : SunSnsrDshbT SunSnsrQf SunSnsrSunLoad;
SIG_GROUP_ 337 TrsmParkLockdSafe2 1 : TrsmParkLockdSafe2TrsmParkLockd TrsmParkLockdSafe2TrsmParkLockdChks TrsmParkLockdSafe2TrsmParkLockdCntr;
SIG_GROUP_ 257 TurnIndcrFault 1 : TurnIndcrFaultChks TurnIndcrFaultCntr TurnIndcrFaultRearLe TurnIndcrFaultRearRi TurnIndcrFaultSideLe TurnIndcrFaultSideRi;
SIG_GROUP_ 257 TwbrSts 1 : TwbrStsTwbrSts TwbrStsTwbrTyp;
SIG_GROUP_ 339 VehBattU 1 : VehBattUSysU VehBattUSysUQf;
SIG_GROUP_ 337 VehMtnStSafe3 1 : VehMtnStSafe3VehMtnSt VehMtnStSafe3VehMtnStChks VehMtnStSafe3VehMtnStCntr;
